VERSION "2021.24.4"

NS_ :

BS_:

BU_: VEH CH Receiver X

BO_ 832 VCFRONT_alertMatrix: 8 Vector__XXX
 SG_ VCFRONT_a060_engineeringBuild m0 : 63|1@1+ (1,0) [0|0] "" Vector__XXX
 SG_ VCFRONT_a120_DI_DRIVE_MIA m1 : 63|1@1+ (1,0) [0|0] "" Vector__XXX
 SG_ VCFRONT_a180_DCDCNotSupportingLV m2 : 63|1@1+ (1,0) [0|0] "" Vector__XXX
 SG_ VCFRONT_a240_lowSideCompromised m3 : 63|1@1+ (1,0) [0|0] "" Vector__XXX
 SG_ VCFRONT_a300_louverActuatorSwapD m4 : 63|1@1+ (1,0) [0|0] "" Vector__XXX
 SG_ VCFRONT_a360_ungracefulAccPlusEx m5 : 63|1@1+ (1,0) [0|0] "" Vector__XXX
 SG_ VCFRONT_a420_holidayParty m6 : 63|1@1+ (1,0) [0|0] "" Vector__XXX
 SG_ VCFRONT_a480_vnf1048Fault m7 : 63|1@1+ (1,0) [0|0] "" Vector__XXX
 SG_ VCFRONT_a540_radiatorSteamDetect m8 : 63|1@1+ (1,0) [0|0] "" Vector__XXX
 SG_ VCFRONT_a600_currentSensorMismat m9 : 63|1@1+ (1,0) [0|0] "" Vector__XXX
 SG_ VCFRONT_d660_coolantValveCircuit m10 : 63|1@1+ (1,0) [0|0] "" Vector__XXX
 SG_ VCFRONT_a059_inputResistanceHigh m0 : 62|1@1+ (1,0) [0|0] "" Vector__XXX
 SG_ VCFRONT_a119_SCCM_MIA m1 : 62|1@1+ (1,0) [0|0] "" Vector__XXX
 SG_ VCFRONT_a179_highLVAmpsIntoPCS m2 : 62|1@1+ (1,0) [0|0] "" Vector__XXX
 SG_ VCFRONT_a239_thmlFanChipComms m3 : 62|1@1+ (1,0) [0|0] "" Vector__XXX
 SG_ VCFRONT_a299_homelinkConfigurati m4 : 62|1@1+ (1,0) [0|0] "" Vector__XXX
 SG_ VCFRONT_a359_postPORExcessiveAh m5 : 62|1@1+ (1,0) [0|0] "" Vector__XXX
 SG_ VCFRONT_a419_TLVBMS_BrickSocLow m6 : 62|1@1+ (1,0) [0|0] "" Vector__XXX
 SG_ VCFRONT_a479_LVBMS_ECPA_NotClose m7 : 62|1@1+ (1,0) [0|0] "" Vector__XXX
 SG_ VCFRONT_a539_ccrExvCalibInitDebu m8 : 62|1@1+ (1,0) [0|0] "" Vector__XXX
 SG_ VCFRONT_a599_LVBatteryTypeUnsupp m9 : 62|1@1+ (1,0) [0|0] "" Vector__XXX
 SG_ VCFRONT_d659_radiatorFanCommLost m10 : 62|1@1+ (1,0) [0|0] "" Vector__XXX
 SG_ VCFRONT_a058_inputRHighSyncDebug m0 : 61|1@1+ (1,0) [0|0] "" Vector__XXX
 SG_ VCFRONT_a118_VCFRONT_MIA m1 : 61|1@1+ (1,0) [0|0] "" Vector__XXX
 SG_ VCFRONT_a178_compLiquidPumpOut m2 : 61|1@1+ (1,0) [0|0] "" Vector__XXX
 SG_ VCFRONT_a238_pumpPtChipComms m3 : 61|1@1+ (1,0) [0|0] "" Vector__XXX
 SG_ VCFRONT_a298_radiatorLowAirFlowD m4 : 61|1@1+ (1,0) [0|0] "" Vector__XXX
 SG_ VCFRONT_a358_hornOvercurrent m5 : 61|1@1+ (1,0) [0|0] "" Vector__XXX
 SG_ VCFRONT_a418_TLVBMS_BrickOverVol m6 : 61|1@1+ (1,0) [0|0] "" Vector__XXX
 SG_ VCFRONT_a478_LVBMS_MOSFET_Open m7 : 61|1@1+ (1,0) [0|0] "" Vector__XXX
 SG_ VCFRONT_a538_cclExvCalibInitDebu m8 : 61|1@1+ (1,0) [0|0] "" Vector__XXX
 SG_ VCFRONT_a598_eFuseSelfTestFailur m9 : 61|1@1+ (1,0) [0|0] "" Vector__XXX
 SG_ VCFRONT_d658_radiatorFanCircuitI m10 : 61|1@1+ (1,0) [0|0] "" Vector__XXX
 SG_ VCFRONT_a057_HVP_MIA m0 : 60|1@1+ (1,0) [0|0] "" Vector__XXX
 SG_ VCFRONT_a117_VCLEFT_MIA m1 : 60|1@1+ (1,0) [0|0] "" Vector__XXX
 SG_ VCFRONT_a177_mcuAudioEFuseFault m2 : 60|1@1+ (1,0) [0|0] "" Vector__XXX
 SG_ VCFRONT_a237_pumpBatChipComms m3 : 60|1@1+ (1,0) [0|0] "" Vector__XXX
 SG_ VCFRONT_a297_TLVBMS_BmbHwOverTem m4 : 60|1@1+ (1,0) [0|0] "" Vector__XXX
 SG_ VCFRONT_a357_hornUndercurrent m5 : 60|1@1+ (1,0) [0|0] "" Vector__XXX
 SG_ VCFRONT_a417_TLVBMS_BrickOverVol m6 : 60|1@1+ (1,0) [0|0] "" Vector__XXX
 SG_ VCFRONT_a477_LVBatteryUnrecovera m7 : 60|1@1+ (1,0) [0|0] "" Vector__XXX
 SG_ VCFRONT_a537_lccExvCalibInitDebu m8 : 60|1@1+ (1,0) [0|0] "" Vector__XXX
 SG_ VCFRONT_a597_vcrightFastBlowPowe m9 : 60|1@1+ (1,0) [0|0] "" Vector__XXX
 SG_ VCFRONT_d657_radiatorFanOperatio m10 : 60|1@1+ (1,0) [0|0] "" Vector__XXX
 SG_ VCFRONT_a116_VCRIGHT_MIA m1 : 59|1@1+ (1,0) [0|0] "" Vector__XXX
 SG_ VCFRONT_a176_vehicleInSelfTest m2 : 59|1@1+ (1,0) [0|0] "" Vector__XXX
 SG_ VCFRONT_a236_batTempSnsIrrationa m3 : 59|1@1+ (1,0) [0|0] "" Vector__XXX
 SG_ VCFRONT_a296_turnSignalIssue m4 : 59|1@1+ (1,0) [0|0] "" Vector__XXX
 SG_ VCFRONT_a356_refrigSysLockout m5 : 59|1@1+ (1,0) [0|0] "" Vector__XXX
 SG_ VCFRONT_a416_TLVBMS_BrickOverDis m6 : 59|1@1+ (1,0) [0|0] "" Vector__XXX
 SG_ VCFRONT_a476_LVBMSMIA m7 : 59|1@1+ (1,0) [0|0] "" Vector__XXX
 SG_ VCFRONT_a536_recircExvCalibInitD m8 : 59|1@1+ (1,0) [0|0] "" Vector__XXX
 SG_ VCFRONT_a596_vcrightCurvePowerCu m9 : 59|1@1+ (1,0) [0|0] "" Vector__XXX
 SG_ VCFRONT_d656_batteryCoolantPumpC m10 : 59|1@1+ (1,0) [0|0] "" Vector__XXX
 SG_ VCFRONT_a115_VCSEC_MIA m1 : 58|1@1+ (1,0) [0|0] "" Vector__XXX
 SG_ VCFRONT_a175_ambientTempSns m2 : 58|1@1+ (1,0) [0|0] "" Vector__XXX
 SG_ VCFRONT_a235_ptTempSnsIrrational m3 : 58|1@1+ (1,0) [0|0] "" Vector__XXX
 SG_ VCFRONT_a295_rightSideRepeaterLi m4 : 58|1@1+ (1,0) [0|0] "" Vector__XXX
 SG_ VCFRONT_a355_coolantSysLockout m5 : 58|1@1+ (1,0) [0|0] "" Vector__XXX
 SG_ VCFRONT_a415_prechargeLVLoadRedu m6 : 58|1@1+ (1,0) [0|0] "" Vector__XXX
 SG_ VCFRONT_a475_rightHeadlampIntern m7 : 58|1@1+ (1,0) [0|0] "" Vector__XXX
 SG_ VCFRONT_a535_evapExvCalibInitDeb m8 : 58|1@1+ (1,0) [0|0] "" Vector__XXX
 SG_ VCFRONT_a595_voltageSensorMismat m9 : 58|1@1+ (1,0) [0|0] "" Vector__XXX
 SG_ VCFRONT_d655_batteryCoolantPumpC m10 : 58|1@1+ (1,0) [0|0] "" Vector__XXX
 SG_ VCFRONT_a054_compressorLowFlowUs m0 : 57|1@1+ (1,0) [0|0] "" Vector__XXX
 SG_ VCFRONT_a114_ESP_MIA m1 : 57|1@1+ (1,0) [0|0] "" Vector__XXX
 SG_ VCFRONT_a174_driveNotAuthed m2 : 57|1@1+ (1,0) [0|0] "" Vector__XXX
 SG_ VCFRONT_a234_autopilot2EFuseFaul m3 : 57|1@1+ (1,0) [0|0] "" Vector__XXX
 SG_ VCFRONT_a294_leftSideRepeaterLig m4 : 57|1@1+ (1,0) [0|0] "" Vector__XXX
 SG_ VCFRONT_a354_windshieldCameraHea m5 : 57|1@1+ (1,0) [0|0] "" Vector__XXX
 SG_ VCFRONT_a414_prechargeLVLoadRedu m6 : 57|1@1+ (1,0) [0|0] "" Vector__XXX
 SG_ VCFRONT_a474_leftHeadlampInterna m7 : 57|1@1+ (1,0) [0|0] "" Vector__XXX
 SG_ VCFRONT_a534_chillerExvCalibInit m8 : 57|1@1+ (1,0) [0|0] "" Vector__XXX
 SG_ VCFRONT_a594_virtualPitchConvers m9 : 57|1@1+ (1,0) [0|0] "" Vector__XXX
 SG_ VCFRONT_d654_batteryCoolantPumpS m10 : 57|1@1+ (1,0) [0|0] "" Vector__XXX
 SG_ VCFRONT_a053_wiperCommErrorUser m0 : 56|1@1+ (1,0) [0|0] "" Vector__XXX
 SG_ VCFRONT_a113_UI_MIA m1 : 56|1@1+ (1,0) [0|0] "" Vector__XXX
 SG_ VCFRONT_a173_HVBlckdByMsmtch m2 : 56|1@1+ (1,0) [0|0] "" Vector__XXX
 SG_ VCFRONT_a233_autopilot1EFuseFaul m3 : 56|1@1+ (1,0) [0|0] "" Vector__XXX
 SG_ VCFRONT_a293_interiorFrunkLightF m4 : 56|1@1+ (1,0) [0|0] "" Vector__XXX
 SG_ VCFRONT_a353_wiperHeaterUndercur m5 : 56|1@1+ (1,0) [0|0] "" Vector__XXX
 SG_ VCFRONT_a413_TLVBMS_BmbVrefWarni m6 : 56|1@1+ (1,0) [0|0] "" Vector__XXX
 SG_ VCFRONT_a473_rightHeadlampRangeU m7 : 56|1@1+ (1,0) [0|0] "" Vector__XXX
 SG_ VCFRONT_a533_TLVBMS_MosfetOverTe m8 : 56|1@1+ (1,0) [0|0] "" Vector__XXX
 SG_ VCFRONT_a593_vcleftFastBlowPower m9 : 56|1@1+ (1,0) [0|0] "" Vector__XXX
 SG_ VCFRONT_d653_ptCoolantPumpCommLo m10 : 56|1@1+ (1,0) [0|0] "" Vector__XXX
 SG_ VCFRONT_a112_EPBL_MIA m1 : 55|1@1+ (1,0) [0|0] "" Vector__XXX
 SG_ VCFRONT_a172_wsteHtBlckdByMsmtch m2 : 55|1@1+ (1,0) [0|0] "" Vector__XXX
 SG_ VCFRONT_a232_lowSideControllerHi m3 : 55|1@1+ (1,0) [0|0] "" Vector__XXX
 SG_ VCFRONT_a292_sideMarkerLightPipe m4 : 55|1@1+ (1,0) [0|0] "" Vector__XXX
 SG_ VCFRONT_a352_audioCurrentSpikeDa m5 : 55|1@1+ (1,0) [0|0] "" Vector__XXX
 SG_ VCFRONT_a412_dcrData3 m6 : 55|1@1+ (1,0) [0|0] "" Vector__XXX
 SG_ VCFRONT_a472_leftHeadlampRangeUp m7 : 55|1@1+ (1,0) [0|0] "" Vector__XXX
 SG_ VCFRONT_a532_gtwMIAInDrive m8 : 55|1@1+ (1,0) [0|0] "" Vector__XXX
 SG_ VCFRONT_a592_vcleftCurvePowerCut m9 : 55|1@1+ (1,0) [0|0] "" Vector__XXX
 SG_ VCFRONT_d652_ptCoolantPumpCircui m10 : 55|1@1+ (1,0) [0|0] "" Vector__XXX
 SG_ VCFRONT_a111_EPBR_MIA m1 : 54|1@1+ (1,0) [0|0] "" Vector__XXX
 SG_ VCFRONT_a171_driveBlckdByMsmtch m2 : 54|1@1+ (1,0) [0|0] "" Vector__XXX
 SG_ VCFRONT_a231_12VTempSensShort m3 : 54|1@1+ (1,0) [0|0] "" Vector__XXX
 SG_ VCFRONT_a291_rightFogLightFault m4 : 54|1@1+ (1,0) [0|0] "" Vector__XXX
 SG_ VCFRONT_a351_emergencyFrunkButto m5 : 54|1@1+ (1,0) [0|0] "" Vector__XXX
 SG_ VCFRONT_a411_LVBatteryDataCollec m6 : 54|1@1+ (1,0) [0|0] "" Vector__XXX
 SG_ VCFRONT_a531_lowPowerIndexFlagge m8 : 54|1@1+ (1,0) [0|0] "" Vector__XXX
 SG_ VCFRONT_a591_vcrightFastBlowDete m9 : 54|1@1+ (1,0) [0|0] "" Vector__XXX
 SG_ VCFRONT_d651_ptCoolantPumpStall m10 : 54|1@1+ (1,0) [0|0] "" Vector__XXX
 SG_ VCFRONT_a110_GTW_MIA m1 : 53|1@1+ (1,0) [0|0] "" Vector__XXX
 SG_ VCFRONT_a170_hcmUnderVoltage m2 : 53|1@1+ (1,0) [0|0] "" Vector__XXX
 SG_ VCFRONT_a230_thmlFanFbkSanity m3 : 53|1@1+ (1,0) [0|0] "" Vector__XXX
 SG_ VCFRONT_a290_leftFogLightFault m4 : 53|1@1+ (1,0) [0|0] "" Vector__XXX
 SG_ VCFRONT_a350_espValveCurrentSens m5 : 53|1@1+ (1,0) [0|0] "" Vector__XXX
 SG_ VCFRONT_a410_LVBatteryDataCollec m6 : 53|1@1+ (1,0) [0|0] "" Vector__XXX
 SG_ VCFRONT_a470_implausiblePdPlDete m7 : 53|1@1+ (1,0) [0|0] "" Vector__XXX
 SG_ VCFRONT_a530_sharpCurrentRise m8 : 53|1@1+ (1,0) [0|0] "" Vector__XXX
 SG_ VCFRONT_a590_vcrightPwrRationali m9 : 53|1@1+ (1,0) [0|0] "" Vector__XXX
 SG_ VCFRONT_d650_lowCoolantLevel m10 : 53|1@1+ (1,0) [0|0] "" Vector__XXX
 SG_ VCFRONT_a109_RCM_MIA m1 : 52|1@1+ (1,0) [0|0] "" Vector__XXX
 SG_ VCFRONT_a169_hcmPhaseEnableFail m2 : 52|1@1+ (1,0) [0|0] "" Vector__XXX
 SG_ VCFRONT_a229_pumpPtFbkSanity m3 : 52|1@1+ (1,0) [0|0] "" Vector__XXX
 SG_ VCFRONT_a289_ccRightExvFault m4 : 52|1@1+ (1,0) [0|0] "" Vector__XXX
 SG_ VCFRONT_a349_vbatFusedFastTripSl m5 : 52|1@1+ (1,0) [0|0] "" Vector__XXX
 SG_ VCFRONT_a409_invalidConfiguratio m6 : 52|1@1+ (1,0) [0|0] "" Vector__XXX
 SG_ VCFRONT_a469_prvPopDetected m7 : 52|1@1+ (1,0) [0|0] "" Vector__XXX
 SG_ VCFRONT_a529_discnctdBatteryStat m8 : 52|1@1+ (1,0) [0|0] "" Vector__XXX
 SG_ VCFRONT_a589_vcleftFastBlowDetec m9 : 52|1@1+ (1,0) [0|0] "" Vector__XXX
 SG_ VCFRONT_a649_persistAccPortPower m10 : 52|1@1+ (1,0) [0|0] "" Vector__XXX
 SG_ VCFRONT_a108_DIF_MIA m1 : 51|1@1+ (1,0) [0|0] "" Vector__XXX
 SG_ VCFRONT_a168_hcmShortToVBAT m2 : 51|1@1+ (1,0) [0|0] "" Vector__XXX
 SG_ VCFRONT_a228_pumpBatFbkSanity m3 : 51|1@1+ (1,0) [0|0] "" Vector__XXX
 SG_ VCFRONT_a288_ccLeftExvFault m4 : 51|1@1+ (1,0) [0|0] "" Vector__XXX
 SG_ VCFRONT_a348_espFastTripSlope m5 : 51|1@1+ (1,0) [0|0] "" Vector__XXX
 SG_ VCFRONT_a408_standbyChargeProfil m6 : 51|1@1+ (1,0) [0|0] "" Vector__XXX
 SG_ VCFRONT_a468_highPowerIndexFlagg m7 : 51|1@1+ (1,0) [0|0] "" Vector__XXX
 SG_ VCFRONT_a528_LVBatteryCommsDiscn m8 : 51|1@1+ (1,0) [0|0] "" Vector__XXX
 SG_ VCFRONT_a588_vcleftPwrRationalit m9 : 51|1@1+ (1,0) [0|0] "" Vector__XXX
 SG_ VCFRONT_d648_louverBlocked m10 : 51|1@1+ (1,0) [0|0] "" Vector__XXX
 SG_ VCFRONT_a047_resetReason m0 : 50|1@1+ (1,0) [0|0] "" Vector__XXX
 SG_ VCFRONT_a107_BMS_MIA m1 : 50|1@1+ (1,0) [0|0] "" Vector__XXX
 SG_ VCFRONT_a167_leftHCMMIA m2 : 50|1@1+ (1,0) [0|0] "" Vector__XXX
 SG_ VCFRONT_a287_lccExvFault m4 : 50|1@1+ (1,0) [0|0] "" Vector__XXX
 SG_ VCFRONT_a347_iboosterFastTripSlo m5 : 50|1@1+ (1,0) [0|0] "" Vector__XXX
 SG_ VCFRONT_a407_dcrMilliOhmsAboveTh m6 : 50|1@1+ (1,0) [0|0] "" Vector__XXX
 SG_ VCFRONT_a467_lowPowerIndexFlagge m7 : 50|1@1+ (1,0) [0|0] "" Vector__XXX
 SG_ VCFRONT_a527_LVBatteryCellImbala m8 : 50|1@1+ (1,0) [0|0] "" Vector__XXX
 SG_ VCFRONT_a587_externalLVPowerSupp m9 : 50|1@1+ (1,0) [0|0] "" Vector__XXX
 SG_ VCFRONT_d647_louverCommLost m10 : 50|1@1+ (1,0) [0|0] "" Vector__XXX
 SG_ VCFRONT_a046_Task1000msError m0 : 49|1@1+ (1,0) [0|0] "" Vector__XXX
 SG_ VCFRONT_a106_PCS_MIA m1 : 49|1@1+ (1,0) [0|0] "" Vector__XXX
 SG_ VCFRONT_a166_rightHCMMIA m2 : 49|1@1+ (1,0) [0|0] "" Vector__XXX
 SG_ VCFRONT_a286_recircExvFault m4 : 49|1@1+ (1,0) [0|0] "" Vector__XXX
 SG_ VCFRONT_a346_epas3sFastTripSlope m5 : 49|1@1+ (1,0) [0|0] "" Vector__XXX
 SG_ VCFRONT_a406_dcrData2 m6 : 49|1@1+ (1,0) [0|0] "" Vector__XXX
 SG_ VCFRONT_a466_highFlowIndexLowSub m7 : 49|1@1+ (1,0) [0|0] "" Vector__XXX
 SG_ VCFRONT_a586_rightLowOrHighBeamL m9 : 49|1@1+ (1,0) [0|0] "" Vector__XXX
 SG_ VCFRONT_a646_washPumpHealthCalcu m10 : 49|1@1+ (1,0) [0|0] "" Vector__XXX
 SG_ VCFRONT_a045_Task100msError m0 : 48|1@1+ (1,0) [0|0] "" Vector__XXX
 SG_ VCFRONT_a105_TAS_MIA m1 : 48|1@1+ (1,0) [0|0] "" Vector__XXX
 SG_ VCFRONT_a165_unxpctdEFuseLckout m2 : 48|1@1+ (1,0) [0|0] "" Vector__XXX
 SG_ VCFRONT_a225_driveBlckdByShowroo m3 : 48|1@1+ (1,0) [0|0] "" Vector__XXX
 SG_ VCFRONT_a285_evaporatorExvFault m4 : 48|1@1+ (1,0) [0|0] "" Vector__XXX
 SG_ VCFRONT_a345_epas3pFastTripSlope m5 : 48|1@1+ (1,0) [0|0] "" Vector__XXX
 SG_ VCFRONT_a405_dcrData1 m6 : 48|1@1+ (1,0) [0|0] "" Vector__XXX
 SG_ VCFRONT_a465_lowFlowIndexHighSub m7 : 48|1@1+ (1,0) [0|0] "" Vector__XXX
 SG_ VCFRONT_a525_LVBatterySWMisconfi m8 : 48|1@1+ (1,0) [0|0] "" Vector__XXX
 SG_ VCFRONT_a585_bothHeadlampsIntern m9 : 48|1@1+ (1,0) [0|0] "" Vector__XXX
 SG_ VCFRONT_a645_washPumpHealthCalcu m10 : 48|1@1+ (1,0) [0|0] "" Vector__XXX
 SG_ VCFRONT_a044_Task10msError m0 : 47|1@1+ (1,0) [0|0] "" Vector__XXX
 SG_ VCFRONT_a104_DAS_MIA m1 : 47|1@1+ (1,0) [0|0] "" Vector__XXX
 SG_ VCFRONT_a164_eFuseLckoutMissing m2 : 47|1@1+ (1,0) [0|0] "" Vector__XXX
 SG_ VCFRONT_a224_revBatChrgPmpFault m3 : 47|1@1+ (1,0) [0|0] "" Vector__XXX
 SG_ VCFRONT_a284_chillerExvFault m4 : 47|1@1+ (1,0) [0|0] "" Vector__XXX
 SG_ VCFRONT_a344_pcsFastTripSlope m5 : 47|1@1+ (1,0) [0|0] "" Vector__XXX
 SG_ VCFRONT_a404_resistanceEstimatio m6 : 47|1@1+ (1,0) [0|0] "" Vector__XXX
 SG_ VCFRONT_a464_highFlowIndexHighSu m7 : 47|1@1+ (1,0) [0|0] "" Vector__XXX
 SG_ VCFRONT_a524_rightHeadlampAiming m8 : 47|1@1+ (1,0) [0|0] "" Vector__XXX
 SG_ VCFRONT_a584_frunkSwitchGroupDeb m9 : 47|1@1+ (1,0) [0|0] "" Vector__XXX
 SG_ VCFRONT_a644_washPumpHealthCalcu m10 : 47|1@1+ (1,0) [0|0] "" Vector__XXX
 SG_ VCFRONT_a043_Task1msError m0 : 46|1@1+ (1,0) [0|0] "" Vector__XXX
 SG_ VCFRONT_a103_CP_MIA m1 : 46|1@1+ (1,0) [0|0] "" Vector__XXX
 SG_ VCFRONT_a163_compressorDisabledF m2 : 46|1@1+ (1,0) [0|0] "" Vector__XXX
 SG_ VCFRONT_a223_12VTempSensDiscnect m3 : 46|1@1+ (1,0) [0|0] "" Vector__XXX
 SG_ VCFRONT_a283_thmlFanLimitedByCur m4 : 46|1@1+ (1,0) [0|0] "" Vector__XXX
 SG_ VCFRONT_a343_vcrightFastTripSlop m5 : 46|1@1+ (1,0) [0|0] "" Vector__XXX
 SG_ VCFRONT_a403_chargeExitHardCurre m6 : 46|1@1+ (1,0) [0|0] "" Vector__XXX
 SG_ VCFRONT_a463_frunkSensorService m7 : 46|1@1+ (1,0) [0|0] "" Vector__XXX
 SG_ VCFRONT_a523_eFuseThresholdsInco m8 : 46|1@1+ (1,0) [0|0] "" Vector__XXX
 SG_ VCFRONT_a583_frunkSwitchGroupDis m9 : 46|1@1+ (1,0) [0|0] "" Vector__XXX
 SG_ VCFRONT_a643_rightHeadlampUartCo m10 : 46|1@1+ (1,0) [0|0] "" Vector__XXX
 SG_ VCFRONT_a042_HighStackUsage m0 : 45|1@1+ (1,0) [0|0] "" Vector__XXX
 SG_ VCFRONT_a102_PTC_MIA m1 : 45|1@1+ (1,0) [0|0] "" Vector__XXX
 SG_ VCFRONT_a162_compressorInhibited m2 : 45|1@1+ (1,0) [0|0] "" Vector__XXX
 SG_ VCFRONT_a222_rightTurnLightFault m3 : 45|1@1+ (1,0) [0|0] "" Vector__XXX
 SG_ VCFRONT_a282_coolantLevelSensorF m4 : 45|1@1+ (1,0) [0|0] "" Vector__XXX
 SG_ VCFRONT_a342_vcleftFastTripSlope m5 : 45|1@1+ (1,0) [0|0] "" Vector__XXX
 SG_ VCFRONT_a402_LVBatteryCannotSupp m6 : 45|1@1+ (1,0) [0|0] "" Vector__XXX
 SG_ VCFRONT_a462_LVBMSFault m7 : 45|1@1+ (1,0) [0|0] "" Vector__XXX
 SG_ VCFRONT_a522_hibernationActiveLo m8 : 45|1@1+ (1,0) [0|0] "" Vector__XXX
 SG_ VCFRONT_a582_goodForPCSPowerCycl m9 : 45|1@1+ (1,0) [0|0] "" Vector__XXX
 SG_ VCFRONT_d642_batteryCoolantPumpC m10 : 45|1@1+ (1,0) [0|0] "" Vector__XXX
 SG_ VCFRONT_a041_HighCPULoad m0 : 44|1@1+ (1,0) [0|0] "" Vector__XXX
 SG_ VCFRONT_a101_PM_MIA m1 : 44|1@1+ (1,0) [0|0] "" Vector__XXX
 SG_ VCFRONT_a161_compressorSelfFault m2 : 44|1@1+ (1,0) [0|0] "" Vector__XXX
 SG_ VCFRONT_a221_leftTurnLightFault m3 : 44|1@1+ (1,0) [0|0] "" Vector__XXX
 SG_ VCFRONT_a281_alcoholInterlockBlo m4 : 44|1@1+ (1,0) [0|0] "" Vector__XXX
 SG_ VCFRONT_a341_vbatFusedFastTripOC m5 : 44|1@1+ (1,0) [0|0] "" Vector__XXX
 SG_ VCFRONT_a401_deadLVMinimalAhDisc m6 : 44|1@1+ (1,0) [0|0] "" Vector__XXX
 SG_ VCFRONT_a461_TLVBMS_SocHighAhErr m7 : 44|1@1+ (1,0) [0|0] "" Vector__XXX
 SG_ VCFRONT_a521_vcleftEFuseLoadShed m8 : 44|1@1+ (1,0) [0|0] "" Vector__XXX
 SG_ VCFRONT_a581_windshieldWiperEFus m9 : 44|1@1+ (1,0) [0|0] "" Vector__XXX
 SG_ VCFRONT_d641_ptCoolantPumpCircui m10 : 44|1@1+ (1,0) [0|0] "" Vector__XXX
 SG_ VCFRONT_a040_Backtrace m0 : 43|1@1+ (1,0) [0|0] "" Vector__XXX
 SG_ VCFRONT_a100_CANbus_MIA m1 : 43|1@1+ (1,0) [0|0] "" Vector__XXX
 SG_ VCFRONT_a160_compressorInhibited m2 : 43|1@1+ (1,0) [0|0] "" Vector__XXX
 SG_ VCFRONT_a220_reverseBatteryFault m3 : 43|1@1+ (1,0) [0|0] "" Vector__XXX
 SG_ VCFRONT_a280_refrigLiquidPresSns m4 : 43|1@1+ (1,0) [0|0] "" Vector__XXX
 SG_ VCFRONT_a340_espFastTripOCMax m5 : 43|1@1+ (1,0) [0|0] "" Vector__XXX
 SG_ VCFRONT_a400_TLVBMS_BmbVrefBad m6 : 43|1@1+ (1,0) [0|0] "" Vector__XXX
 SG_ VCFRONT_a460_hardIsentropicTdFai m7 : 43|1@1+ (1,0) [0|0] "" Vector__XXX
 SG_ VCFRONT_a580_rightHeadlightEFuse m9 : 43|1@1+ (1,0) [0|0] "" Vector__XXX
 SG_ VCFRONT_d640_firmwareVersionMism m10 : 43|1@1+ (1,0) [0|0] "" Vector__XXX
 SG_ VCFRONT_a039_ProtFaultAddress m0 : 42|1@1+ (1,0) [0|0] "" Vector__XXX
 SG_ VCFRONT_a099_PARK_MIA m1 : 42|1@1+ (1,0) [0|0] "" Vector__XXX
 SG_ VCFRONT_a159_coolantValveFault m2 : 42|1@1+ (1,0) [0|0] "" Vector__XXX
 SG_ VCFRONT_a219_LVVoltFloorRchd m3 : 42|1@1+ (1,0) [0|0] "" Vector__XXX
 SG_ VCFRONT_a279_refrigLiquidTempSns m4 : 42|1@1+ (1,0) [0|0] "" Vector__XXX
 SG_ VCFRONT_a339_iboosterFastTripOCM m5 : 42|1@1+ (1,0) [0|0] "" Vector__XXX
 SG_ VCFRONT_a399_frunkNeverReportedO m6 : 42|1@1+ (1,0) [0|0] "" Vector__XXX
 SG_ VCFRONT_a459_thermalFillAndDrive m7 : 42|1@1+ (1,0) [0|0] "" Vector__XXX
 SG_ VCFRONT_a579_leftHeadlightEFuseT m9 : 42|1@1+ (1,0) [0|0] "" Vector__XXX
 SG_ VCFRONT_d639_batteryCoolantTempS m10 : 42|1@1+ (1,0) [0|0] "" Vector__XXX
 SG_ VCFRONT_a038_ProtFaultInfo m0 : 41|1@1+ (1,0) [0|0] "" Vector__XXX
 SG_ VCFRONT_a098_DIR_MIA m1 : 41|1@1+ (1,0) [0|0] "" Vector__XXX
 SG_ VCFRONT_a158_louverDisconnected m2 : 41|1@1+ (1,0) [0|0] "" Vector__XXX
 SG_ VCFRONT_a218_socMonitorDetectedT m3 : 41|1@1+ (1,0) [0|0] "" Vector__XXX
 SG_ VCFRONT_a278_TLVBMS_BmbHwOverCur m4 : 41|1@1+ (1,0) [0|0] "" Vector__XXX
 SG_ VCFRONT_a338_epas3sFastTripOCMax m5 : 41|1@1+ (1,0) [0|0] "" Vector__XXX
 SG_ VCFRONT_a398_tempSensorCheckInco m6 : 41|1@1+ (1,0) [0|0] "" Vector__XXX
 SG_ VCFRONT_a458_grosslyLowRefrigera m7 : 41|1@1+ (1,0) [0|0] "" Vector__XXX
 SG_ VCFRONT_a518_LVBMSFault_MOS_Open m8 : 41|1@1+ (1,0) [0|0] "" Vector__XXX
 SG_ VCFRONT_a578_vbatFusedLowCurrent m9 : 41|1@1+ (1,0) [0|0] "" Vector__XXX
 SG_ VCFRONT_a698_rightHeadlampNotAim m11 : 41|1@1+ (1,0) [0|0] "" Vector__XXX
 SG_ VCFRONT_d638_ptCoolantTempSensor m10 : 41|1@1+ (1,0) [0|0] "" Vector__XXX
 SG_ VCFRONT_a097_CMP_MIA m1 : 40|1@1+ (1,0) [0|0] "" Vector__XXX
 SG_ VCFRONT_a157_louverBreakage m2 : 40|1@1+ (1,0) [0|0] "" Vector__XXX
 SG_ VCFRONT_a277_TLVBMS_BmbStatusReg m4 : 40|1@1+ (1,0) [0|0] "" Vector__XXX
 SG_ VCFRONT_a337_epas3pFastTripOCMax m5 : 40|1@1+ (1,0) [0|0] "" Vector__XXX
 SG_ VCFRONT_a397_temperatureSensorCh m6 : 40|1@1+ (1,0) [0|0] "" Vector__XXX
 SG_ VCFRONT_a457_liquidTempSensInter m7 : 40|1@1+ (1,0) [0|0] "" Vector__XXX
 SG_ VCFRONT_a517_hibernationRecovery m8 : 40|1@1+ (1,0) [0|0] "" Vector__XXX
 SG_ VCFRONT_a577_tasEFuseTrip m9 : 40|1@1+ (1,0) [0|0] "" Vector__XXX
 SG_ VCFRONT_a697_leftHeadlampNotAime m11 : 40|1@1+ (1,0) [0|0] "" Vector__XXX
 SG_ VCFRONT_d637_battCoolantPumpDete m10 : 40|1@1+ (1,0) [0|0] "" Vector__XXX
 SG_ VCFRONT_a096_OCS1P_MIA m1 : 39|1@1+ (1,0) [0|0] "" Vector__XXX
 SG_ VCFRONT_a156_louverBlockage m2 : 39|1@1+ (1,0) [0|0] "" Vector__XXX
 SG_ VCFRONT_a216_powerCutoffImminent m3 : 39|1@1+ (1,0) [0|0] "" Vector__XXX
 SG_ VCFRONT_a276_TLVBMS_BmbDataInteg m4 : 39|1@1+ (1,0) [0|0] "" Vector__XXX
 SG_ VCFRONT_a336_pcsFastTripOCMax m5 : 39|1@1+ (1,0) [0|0] "" Vector__XXX
 SG_ VCFRONT_a396_coolantLevelLowUser m6 : 39|1@1+ (1,0) [0|0] "" Vector__XXX
 SG_ VCFRONT_a456_liquidPresSensInter m7 : 39|1@1+ (1,0) [0|0] "" Vector__XXX
 SG_ VCFRONT_a516_hibernationActive m8 : 39|1@1+ (1,0) [0|0] "" Vector__XXX
 SG_ VCFRONT_a576_mcuLogicEFuseTrip m9 : 39|1@1+ (1,0) [0|0] "" Vector__XXX
 SG_ VCFRONT_d636_ptCoolantPumpDetect m10 : 39|1@1+ (1,0) [0|0] "" Vector__XXX
 SG_ VCFRONT_a095_CHG_MIA m1 : 38|1@1+ (1,0) [0|0] "" Vector__XXX
 SG_ VCFRONT_a155_prechargeDCRData2 m2 : 38|1@1+ (1,0) [0|0] "" Vector__XXX
 SG_ VCFRONT_a275_TLVBMS_BmbCommunica m4 : 38|1@1+ (1,0) [0|0] "" Vector__XXX
 SG_ VCFRONT_a335_vcrightFastTripOCMa m5 : 38|1@1+ (1,0) [0|0] "" Vector__XXX
 SG_ VCFRONT_a395_pressureSensorCheck m6 : 38|1@1+ (1,0) [0|0] "" Vector__XXX
 SG_ VCFRONT_a455_suctionTempSensInte m7 : 38|1@1+ (1,0) [0|0] "" Vector__XXX
 SG_ VCFRONT_a515_LVBMSFault_MOS_Open m8 : 38|1@1+ (1,0) [0|0] "" Vector__XXX
 SG_ VCFRONT_a575_frontOilPumpEFuseTr m9 : 38|1@1+ (1,0) [0|0] "" Vector__XXX
 SG_ VCFRONT_a635_rtosSleepFailed m10 : 38|1@1+ (1,0) [0|0] "" Vector__XXX
 SG_ VCFRONT_a094_EPAS3P_MIA m1 : 37|1@1+ (1,0) [0|0] "" Vector__XXX
 SG_ VCFRONT_a154_prechargeDCRData1 m2 : 37|1@1+ (1,0) [0|0] "" Vector__XXX
 SG_ VCFRONT_a274_failureToPrechargeR m4 : 37|1@1+ (1,0) [0|0] "" Vector__XXX
 SG_ VCFRONT_a334_vcleftFastTripOCMax m5 : 37|1@1+ (1,0) [0|0] "" Vector__XXX
 SG_ VCFRONT_a394_pressureSensorCheck m6 : 37|1@1+ (1,0) [0|0] "" Vector__XXX
 SG_ VCFRONT_a454_suctionPresSensInte m7 : 37|1@1+ (1,0) [0|0] "" Vector__XXX
 SG_ VCFRONT_a514_LVBMSFault_MOS_Open m8 : 37|1@1+ (1,0) [0|0] "" Vector__XXX
 SG_ VCFRONT_a574_frontDriveInverterE m9 : 37|1@1+ (1,0) [0|0] "" Vector__XXX
 SG_ VCFRONT_a634_indeterminateSwitch m10 : 37|1@1+ (1,0) [0|0] "" Vector__XXX
 SG_ VCFRONT_a033_eccNonCorrectableEr m0 : 36|1@1+ (1,0) [0|0] "" Vector__XXX
 SG_ VCFRONT_a093_VCSEATP_MIA m1 : 36|1@1+ (1,0) [0|0] "" Vector__XXX
 SG_ VCFRONT_a153_userPresenceDisplay m2 : 36|1@1+ (1,0) [0|0] "" Vector__XXX
 SG_ VCFRONT_a213_LVOvercharge m3 : 36|1@1+ (1,0) [0|0] "" Vector__XXX
 SG_ VCFRONT_a273_wiperFrictionModelF m4 : 36|1@1+ (1,0) [0|0] "" Vector__XXX
 SG_ VCFRONT_a333_vbatFusedSlowTripOC m5 : 36|1@1+ (1,0) [0|0] "" Vector__XXX
 SG_ VCFRONT_a393_ambientTempNetworkS m6 : 36|1@1+ (1,0) [0|0] "" Vector__XXX
 SG_ VCFRONT_a453_dischargeTempSensIn m7 : 36|1@1+ (1,0) [0|0] "" Vector__XXX
 SG_ VCFRONT_a513_LVBMSFault_MOS_Open m8 : 36|1@1+ (1,0) [0|0] "" Vector__XXX
 SG_ VCFRONT_a573_radarEFuseTrip m9 : 36|1@1+ (1,0) [0|0] "" Vector__XXX
 SG_ VCFRONT_a032_ipcWatchdogExpired m0 : 35|1@1+ (1,0) [0|0] "" Vector__XXX
 SG_ VCFRONT_a092_VCSEATD_MIA m1 : 35|1@1+ (1,0) [0|0] "" Vector__XXX
 SG_ VCFRONT_a152_thmlFanLowRPMCBang m2 : 35|1@1+ (1,0) [0|0] "" Vector__XXX
 SG_ VCFRONT_a212_IBSOverTemp m3 : 35|1@1+ (1,0) [0|0] "" Vector__XXX
 SG_ VCFRONT_a332_espSlowTripOC m5 : 35|1@1+ (1,0) [0|0] "" Vector__XXX
 SG_ VCFRONT_a392_TLVBMS_BmbHwUnderVo m6 : 35|1@1+ (1,0) [0|0] "" Vector__XXX
 SG_ VCFRONT_a452_dischargePresSensIn m7 : 35|1@1+ (1,0) [0|0] "" Vector__XXX
 SG_ VCFRONT_a512_LVBMSFault_MOS_Open m8 : 35|1@1+ (1,0) [0|0] "" Vector__XXX
 SG_ VCFRONT_a572_hvacCompressorEFuse m9 : 35|1@1+ (1,0) [0|0] "" Vector__XXX
 SG_ VCFRONT_a031_UDSActive m0 : 34|1@1+ (1,0) [0|0] "" Vector__XXX
 SG_ VCFRONT_a091_CMPD_MIA m1 : 34|1@1+ (1,0) [0|0] "" Vector__XXX
 SG_ VCFRONT_a151_pumpPtLowRPMCBang m2 : 34|1@1+ (1,0) [0|0] "" Vector__XXX
 SG_ VCFRONT_a211_I2CFault m3 : 34|1@1+ (1,0) [0|0] "" Vector__XXX
 SG_ VCFRONT_a271_LVBatteryPermSuppor m4 : 34|1@1+ (1,0) [0|0] "" Vector__XXX
 SG_ VCFRONT_a331_iboosterSlowTripOC m5 : 34|1@1+ (1,0) [0|0] "" Vector__XXX
 SG_ VCFRONT_a391_frunkLatchSwitchFau m6 : 34|1@1+ (1,0) [0|0] "" Vector__XXX
 SG_ VCFRONT_a451_refrigerantNotCommi m7 : 34|1@1+ (1,0) [0|0] "" Vector__XXX
 SG_ VCFRONT_a511_DCDCSaturationLoadS m8 : 34|1@1+ (1,0) [0|0] "" Vector__XXX
 SG_ VCFRONT_a571_headlampsAdaptedToR m9 : 34|1@1+ (1,0) [0|0] "" Vector__XXX
 SG_ VCFRONT_a631_rightHeadlampFactor m10 : 34|1@1+ (1,0) [0|0] "" Vector__XXX
 SG_ VCFRONT_a030_ECULogUploadRequest m0 : 33|1@1+ (1,0) [0|0] "" Vector__XXX
 SG_ VCFRONT_a090_APS_MIA m1 : 33|1@1+ (1,0) [0|0] "" Vector__XXX
 SG_ VCFRONT_a150_pumpBatLowRPMCBang m2 : 33|1@1+ (1,0) [0|0] "" Vector__XXX
 SG_ VCFRONT_a210_coolantValveCalib m3 : 33|1@1+ (1,0) [0|0] "" Vector__XXX
 SG_ VCFRONT_a330_epas3sSlowTripOC m5 : 33|1@1+ (1,0) [0|0] "" Vector__XXX
 SG_ VCFRONT_a390_heatPumpModeConverg m6 : 33|1@1+ (1,0) [0|0] "" Vector__XXX
 SG_ VCFRONT_a450_hornSwitchNotPresse m7 : 33|1@1+ (1,0) [0|0] "" Vector__XXX
 SG_ VCFRONT_a510_LVBatteryRecoveryTi m8 : 33|1@1+ (1,0) [0|0] "" Vector__XXX
 SG_ VCFRONT_a570_headlampsAdaptedToL m9 : 33|1@1+ (1,0) [0|0] "" Vector__XXX
 SG_ VCFRONT_a630_leftHeadlampFactory m10 : 33|1@1+ (1,0) [0|0] "" Vector__XXX
 SG_ VCFRONT_a029_CoreDump m0 : 32|1@1+ (1,0) [0|0] "" Vector__XXX
 SG_ VCFRONT_a089_IBST_MIA m1 : 32|1@1+ (1,0) [0|0] "" Vector__XXX
 SG_ VCFRONT_a149_BLEFrontPowerCycled m2 : 32|1@1+ (1,0) [0|0] "" Vector__XXX
 SG_ VCFRONT_a209_brakeFluidSNA m3 : 32|1@1+ (1,0) [0|0] "" Vector__XXX
 SG_ VCFRONT_a269_drveBlckdVltgeTooLo m4 : 32|1@1+ (1,0) [0|0] "" Vector__XXX
 SG_ VCFRONT_a329_epas3pSlowTripOC m5 : 32|1@1+ (1,0) [0|0] "" Vector__XXX
 SG_ VCFRONT_a389_frunkInhibitingRele m6 : 32|1@1+ (1,0) [0|0] "" Vector__XXX
 SG_ VCFRONT_a449_hornSwitchStuckOn m7 : 32|1@1+ (1,0) [0|0] "" Vector__XXX
 SG_ VCFRONT_a509_vcrightEFuseLoadShe m8 : 32|1@1+ (1,0) [0|0] "" Vector__XXX
 SG_ VCFRONT_a569_rightDaytimeRunning m9 : 32|1@1+ (1,0) [0|0] "" Vector__XXX
 SG_ VCFRONT_a629_TLVBMS_PackTemperat m10 : 32|1@1+ (1,0) [0|0] "" Vector__XXX
 SG_ VCFRONT_a088_DIRER_MIA m1 : 31|1@1+ (1,0) [0|0] "" Vector__XXX
 SG_ VCFRONT_a148_thmlFanSoftStall m2 : 31|1@1+ (1,0) [0|0] "" Vector__XXX
 SG_ VCFRONT_a208_brakeFluidLow m3 : 31|1@1+ (1,0) [0|0] "" Vector__XXX
 SG_ VCFRONT_a268_vbatFusedVoltageMis m4 : 31|1@1+ (1,0) [0|0] "" Vector__XXX
 SG_ VCFRONT_a328_pcsSlowTripOC m5 : 31|1@1+ (1,0) [0|0] "" Vector__XXX
 SG_ VCFRONT_a388_shortedCell m6 : 31|1@1+ (1,0) [0|0] "" Vector__XXX
 SG_ VCFRONT_a448_gtwSteeringBtnReset m7 : 31|1@1+ (1,0) [0|0] "" Vector__XXX
 SG_ VCFRONT_a508_TLVBMS_ImpedanceGro m8 : 31|1@1+ (1,0) [0|0] "" Vector__XXX
 SG_ VCFRONT_a568_leftDaytimeRunningL m9 : 31|1@1+ (1,0) [0|0] "" Vector__XXX
 SG_ VCFRONT_a628_TLVBMS_BmbThermisto m10 : 31|1@1+ (1,0) [0|0] "" Vector__XXX
 SG_ VCFRONT_a087_DIREL_MIA m1 : 30|1@1+ (1,0) [0|0] "" Vector__XXX
 SG_ VCFRONT_a147_pumpPtSoftStall m2 : 30|1@1+ (1,0) [0|0] "" Vector__XXX
 SG_ VCFRONT_a207_vbatFusdSelfTestFai m3 : 30|1@1+ (1,0) [0|0] "" Vector__XXX
 SG_ VCFRONT_a267_EPAS3sVoltageMismat m4 : 30|1@1+ (1,0) [0|0] "" Vector__XXX
 SG_ VCFRONT_a327_vcrightSlowTripOC m5 : 30|1@1+ (1,0) [0|0] "" Vector__XXX
 SG_ VCFRONT_a387_shortedCellInstc m6 : 30|1@1+ (1,0) [0|0] "" Vector__XXX
 SG_ VCFRONT_a447_cabinHVACUnavailabl m7 : 30|1@1+ (1,0) [0|0] "" Vector__XXX
 SG_ VCFRONT_a507_leftHeadlampAimingF m8 : 30|1@1+ (1,0) [0|0] "" Vector__XXX
 SG_ VCFRONT_a567_rightFrontTurnLight m9 : 30|1@1+ (1,0) [0|0] "" Vector__XXX
 SG_ VCFRONT_a627_LVBatteryUnrecovera m10 : 30|1@1+ (1,0) [0|0] "" Vector__XXX
 SG_ VCFRONT_a086_VCBATT_MIA m1 : 29|1@1+ (1,0) [0|0] "" Vector__XXX
 SG_ VCFRONT_a146_pumpBatSoftStall m2 : 29|1@1+ (1,0) [0|0] "" Vector__XXX
 SG_ VCFRONT_a206_espSelfTestFail m3 : 29|1@1+ (1,0) [0|0] "" Vector__XXX
 SG_ VCFRONT_a266_EPAS3pVoltageMismat m4 : 29|1@1+ (1,0) [0|0] "" Vector__XXX
 SG_ VCFRONT_a326_vcleftSlowTripOC m5 : 29|1@1+ (1,0) [0|0] "" Vector__XXX
 SG_ VCFRONT_a386_exvMotorWarning m6 : 29|1@1+ (1,0) [0|0] "" Vector__XXX
 SG_ VCFRONT_a446_cabinHVACUnavailabl m7 : 29|1@1+ (1,0) [0|0] "" Vector__XXX
 SG_ VCFRONT_a506_invalidRefrigerantS m8 : 29|1@1+ (1,0) [0|0] "" Vector__XXX
 SG_ VCFRONT_a566_leftFrontTurnLightF m9 : 29|1@1+ (1,0) [0|0] "" Vector__XXX
 SG_ VCFRONT_a626_LVBatteryResistance m10 : 29|1@1+ (1,0) [0|0] "" Vector__XXX
 SG_ VCFRONT_a085_CCCM_MIA m1 : 28|1@1+ (1,0) [0|0] "" Vector__XXX
 SG_ VCFRONT_a145_thmlFanICTransFault m2 : 28|1@1+ (1,0) [0|0] "" Vector__XXX
 SG_ VCFRONT_a205_iBoosterSelfTestFai m3 : 28|1@1+ (1,0) [0|0] "" Vector__XXX
 SG_ VCFRONT_a265_ESPVoltageMismatch m4 : 28|1@1+ (1,0) [0|0] "" Vector__XXX
 SG_ VCFRONT_a325_vbatFusedOvertempMa m5 : 28|1@1+ (1,0) [0|0] "" Vector__XXX
 SG_ VCFRONT_a385_ccRightExvWarning m6 : 28|1@1+ (1,0) [0|0] "" Vector__XXX
 SG_ VCFRONT_a445_drv8703SpiFaultDBG m7 : 28|1@1+ (1,0) [0|0] "" Vector__XXX
 SG_ VCFRONT_a505_BLEFrontUnderVoltag m8 : 28|1@1+ (1,0) [0|0] "" Vector__XXX
 SG_ VCFRONT_a565_userPresenceDisplay m9 : 28|1@1+ (1,0) [0|0] "" Vector__XXX
 SG_ VCFRONT_a084_TPMS_MIA m1 : 27|1@1+ (1,0) [0|0] "" Vector__XXX
 SG_ VCFRONT_a144_pumpPtICTransFault m2 : 27|1@1+ (1,0) [0|0] "" Vector__XXX
 SG_ VCFRONT_a204_epas3sSelfTestFail m3 : 27|1@1+ (1,0) [0|0] "" Vector__XXX
 SG_ VCFRONT_a264_iBoosterVoltageMism m4 : 27|1@1+ (1,0) [0|0] "" Vector__XXX
 SG_ VCFRONT_a324_espOvertempMax m5 : 27|1@1+ (1,0) [0|0] "" Vector__XXX
 SG_ VCFRONT_a384_ccLeftExvWarning m6 : 27|1@1+ (1,0) [0|0] "" Vector__XXX
 SG_ VCFRONT_a444_drv8703Fault m7 : 27|1@1+ (1,0) [0|0] "" Vector__XXX
 SG_ VCFRONT_a504_airInRefrigerantDet m8 : 27|1@1+ (1,0) [0|0] "" Vector__XXX
 SG_ VCFRONT_a564_leftHeadlampAimingD m9 : 27|1@1+ (1,0) [0|0] "" Vector__XXX
 SG_ VCFRONT_a083_VCLEFT_IPC_MIA m1 : 26|1@1+ (1,0) [0|0] "" Vector__XXX
 SG_ VCFRONT_a143_pumpBatICTransFault m2 : 26|1@1+ (1,0) [0|0] "" Vector__XXX
 SG_ VCFRONT_a203_epas3pSelfTestFail m3 : 26|1@1+ (1,0) [0|0] "" Vector__XXX
 SG_ VCFRONT_a263_pcsVoltageMismatch m4 : 26|1@1+ (1,0) [0|0] "" Vector__XXX
 SG_ VCFRONT_a323_iboosterOvertempMax m5 : 26|1@1+ (1,0) [0|0] "" Vector__XXX
 SG_ VCFRONT_a383_lccExvWarning m6 : 26|1@1+ (1,0) [0|0] "" Vector__XXX
 SG_ VCFRONT_a443_TLVBMS_BmbDieOverTe m7 : 26|1@1+ (1,0) [0|0] "" Vector__XXX
 SG_ VCFRONT_a503_TLVBMS_BrickExtende m8 : 26|1@1+ (1,0) [0|0] "" Vector__XXX
 SG_ VCFRONT_a563_chargePortDoorOpenB m9 : 26|1@1+ (1,0) [0|0] "" Vector__XXX
 SG_ VCFRONT_a623_LVUnhealthy m10 : 26|1@1+ (1,0) [0|0] "" Vector__XXX
 SG_ VCFRONT_a022_TaskInitError m0 : 25|1@1+ (1,0) [0|0] "" Vector__XXX
 SG_ VCFRONT_a082_VCRIGHT_IPC_MIA m1 : 25|1@1+ (1,0) [0|0] "" Vector__XXX
 SG_ VCFRONT_a142_exvMotorFault m2 : 25|1@1+ (1,0) [0|0] "" Vector__XXX
 SG_ VCFRONT_a202_pcsSelfTestFail m3 : 25|1@1+ (1,0) [0|0] "" Vector__XXX
 SG_ VCFRONT_a262_vcrightVoltageMisma m4 : 25|1@1+ (1,0) [0|0] "" Vector__XXX
 SG_ VCFRONT_a322_epas3sOvertempMax m5 : 25|1@1+ (1,0) [0|0] "" Vector__XXX
 SG_ VCFRONT_a382_recircExvWarning m6 : 25|1@1+ (1,0) [0|0] "" Vector__XXX
 SG_ VCFRONT_a442_TLVBMS_SocChange m7 : 25|1@1+ (1,0) [0|0] "" Vector__XXX
 SG_ VCFRONT_a502_TLVBMS_WeakShortImp m8 : 25|1@1+ (1,0) [0|0] "" Vector__XXX
 SG_ VCFRONT_a562_LVBMSModuleOvertemp m9 : 25|1@1+ (1,0) [0|0] "" Vector__XXX
 SG_ VCFRONT_a021_TaskSchedulerError m0 : 24|1@1+ (1,0) [0|0] "" Vector__XXX
 SG_ VCFRONT_a141_coolantTempBatSns m2 : 24|1@1+ (1,0) [0|0] "" Vector__XXX
 SG_ VCFRONT_a201_vcrightSelfTestFail m3 : 24|1@1+ (1,0) [0|0] "" Vector__XXX
 SG_ VCFRONT_a261_vcleftVoltageMismat m4 : 24|1@1+ (1,0) [0|0] "" Vector__XXX
 SG_ VCFRONT_a321_epas3pOvertempMax m5 : 24|1@1+ (1,0) [0|0] "" Vector__XXX
 SG_ VCFRONT_a381_evaporatorExvWarnin m6 : 24|1@1+ (1,0) [0|0] "" Vector__XXX
 SG_ VCFRONT_a441_TLVBMS_ResetNeededF m7 : 24|1@1+ (1,0) [0|0] "" Vector__XXX
 SG_ VCFRONT_a501_vnf1048Configuratio m8 : 24|1@1+ (1,0) [0|0] "" Vector__XXX
 SG_ VCFRONT_a561_LVBMSEFuseOvertempe m9 : 24|1@1+ (1,0) [0|0] "" Vector__XXX
 SG_ VCFRONT_a140_coolantTempPtSns m2 : 23|1@1+ (1,0) [0|0] "" Vector__XXX
 SG_ VCFRONT_a200_vcleftSelfTestFail m3 : 23|1@1+ (1,0) [0|0] "" Vector__XXX
 SG_ VCFRONT_a260_deadLVBattery m4 : 23|1@1+ (1,0) [0|0] "" Vector__XXX
 SG_ VCFRONT_a320_pcsOvertempMax m5 : 23|1@1+ (1,0) [0|0] "" Vector__XXX
 SG_ VCFRONT_a380_chillerExvWarning m6 : 23|1@1+ (1,0) [0|0] "" Vector__XXX
 SG_ VCFRONT_a440_TLVBMS_PackSNInvali m7 : 23|1@1+ (1,0) [0|0] "" Vector__XXX
 SG_ VCFRONT_a500_eFuseASICStateMisma m8 : 23|1@1+ (1,0) [0|0] "" Vector__XXX
 SG_ VCFRONT_a560_compressorHighSuper m9 : 23|1@1+ (1,0) [0|0] "" Vector__XXX
 SG_ VCFRONT_a139_refrigSuctPresSns m2 : 22|1@1+ (1,0) [0|0] "" Vector__XXX
 SG_ VCFRONT_a199_PRVCANUndertrminate m3 : 22|1@1+ (1,0) [0|0] "" Vector__XXX
 SG_ VCFRONT_a259_LVVoltageDropOnHigh m4 : 22|1@1+ (1,0) [0|0] "" Vector__XXX
 SG_ VCFRONT_a319_vcrightOvertempMax m5 : 22|1@1+ (1,0) [0|0] "" Vector__XXX
 SG_ VCFRONT_a379_shortedCellTestRunD m6 : 22|1@1+ (1,0) [0|0] "" Vector__XXX
 SG_ VCFRONT_a439_TLVBMS_PackOverTemp m7 : 22|1@1+ (1,0) [0|0] "" Vector__XXX
 SG_ VCFRONT_a499_loadShedPumpFlowReq m8 : 22|1@1+ (1,0) [0|0] "" Vector__XXX
 SG_ VCFRONT_a559_LVBatteryLowSOC m9 : 22|1@1+ (1,0) [0|0] "" Vector__XXX
 SG_ VCFRONT_a619_frunkSwitchReleaseT m10 : 22|1@1+ (1,0) [0|0] "" Vector__XXX
 SG_ VCFRONT_a138_refrigSuctTempSns m2 : 21|1@1+ (1,0) [0|0] "" Vector__XXX
 SG_ VCFRONT_a198_PRVCANOverterminate m3 : 21|1@1+ (1,0) [0|0] "" Vector__XXX
 SG_ VCFRONT_a258_resistanceEstimatio m4 : 21|1@1+ (1,0) [0|0] "" Vector__XXX
 SG_ VCFRONT_a318_vcleftOvertempMax m5 : 21|1@1+ (1,0) [0|0] "" Vector__XXX
 SG_ VCFRONT_a378_wiperECUDebug m6 : 21|1@1+ (1,0) [0|0] "" Vector__XXX
 SG_ VCFRONT_a438_TLVBMS_PackOverTemp m7 : 21|1@1+ (1,0) [0|0] "" Vector__XXX
 SG_ VCFRONT_a498_TLVBMS_ImpedanceTes m8 : 21|1@1+ (1,0) [0|0] "" Vector__XXX
 SG_ VCFRONT_a558_rightHeadlampAiming m9 : 21|1@1+ (1,0) [0|0] "" Vector__XXX
 SG_ VCFRONT_a618_cabinCoolingCapacit m10 : 21|1@1+ (1,0) [0|0] "" Vector__XXX
 SG_ VCFRONT_a017_NVMMStatusDbg m0 : 20|1@1+ (1,0) [0|0] "" Vector__XXX
 SG_ VCFRONT_a137_refrigDischPresSns m2 : 20|1@1+ (1,0) [0|0] "" Vector__XXX
 SG_ VCFRONT_a197_prechargeDCRData3 m3 : 20|1@1+ (1,0) [0|0] "" Vector__XXX
 SG_ VCFRONT_a257_portExpanderVOR m4 : 20|1@1+ (1,0) [0|0] "" Vector__XXX
 SG_ VCFRONT_a317_vbatFusedOvertempSl m5 : 20|1@1+ (1,0) [0|0] "" Vector__XXX
 SG_ VCFRONT_a377_wiperParkFault m6 : 20|1@1+ (1,0) [0|0] "" Vector__XXX
 SG_ VCFRONT_a437_TLVBMS_NvmRegistrat m7 : 20|1@1+ (1,0) [0|0] "" Vector__XXX
 SG_ VCFRONT_a497_LVBatteryWarnDiscon m8 : 20|1@1+ (1,0) [0|0] "" Vector__XXX
 SG_ VCFRONT_a016_NVMMRecordError m0 : 19|1@1+ (1,0) [0|0] "" Vector__XXX
 SG_ VCFRONT_a136_refrigDischTempSns m2 : 19|1@1+ (1,0) [0|0] "" Vector__XXX
 SG_ VCFRONT_a196_discnctdLVBattery m3 : 19|1@1+ (1,0) [0|0] "" Vector__XXX
 SG_ VCFRONT_a256_compTornShaftSeal m4 : 19|1@1+ (1,0) [0|0] "" Vector__XXX
 SG_ VCFRONT_a316_espOvertempSlope m5 : 19|1@1+ (1,0) [0|0] "" Vector__XXX
 SG_ VCFRONT_a376_controllerWakeupDeb m6 : 19|1@1+ (1,0) [0|0] "" Vector__XXX
 SG_ VCFRONT_a436_TLVBMS_DischargeOve m7 : 19|1@1+ (1,0) [0|0] "" Vector__XXX
 SG_ VCFRONT_a496_LVBatteryExitDriveW m8 : 19|1@1+ (1,0) [0|0] "" Vector__XXX
 SG_ VCFRONT_a556_falseTriggerOfDiscn m9 : 19|1@1+ (1,0) [0|0] "" Vector__XXX
 SG_ VCFRONT_a015_NVMMError m0 : 18|1@1+ (1,0) [0|0] "" Vector__XXX
 SG_ VCFRONT_a135_coolantLevelLow m2 : 18|1@1+ (1,0) [0|0] "" Vector__XXX
 SG_ VCFRONT_a195_drveBlckdVltgeTooHg m3 : 18|1@1+ (1,0) [0|0] "" Vector__XXX
 SG_ VCFRONT_a255_pumpPtStopped m4 : 18|1@1+ (1,0) [0|0] "" Vector__XXX
 SG_ VCFRONT_a315_iboosterOvertempSlo m5 : 18|1@1+ (1,0) [0|0] "" Vector__XXX
 SG_ VCFRONT_a375_refVoltageOutOfSpec m6 : 18|1@1+ (1,0) [0|0] "" Vector__XXX
 SG_ VCFRONT_a435_TLVBMS_DchgCurrentL m7 : 18|1@1+ (1,0) [0|0] "" Vector__XXX
 SG_ VCFRONT_a495_LVBatteryRecoveryBl m8 : 18|1@1+ (1,0) [0|0] "" Vector__XXX
 SG_ VCFRONT_a555_LVBatteryCellRebala m9 : 18|1@1+ (1,0) [0|0] "" Vector__XXX
 SG_ VCFRONT_a615_TLVBMS_BatteryHeate m10 : 18|1@1+ (1,0) [0|0] "" Vector__XXX
 SG_ VCFRONT_a134_fusedHighEFuseTrip m2 : 17|1@1+ (1,0) [0|0] "" Vector__XXX
 SG_ VCFRONT_a194_iBoosterRetry m3 : 17|1@1+ (1,0) [0|0] "" Vector__XXX
 SG_ VCFRONT_a254_pumpBatStopped m4 : 17|1@1+ (1,0) [0|0] "" Vector__XXX
 SG_ VCFRONT_a314_epas3sOvertempSlope m5 : 17|1@1+ (1,0) [0|0] "" Vector__XXX
 SG_ VCFRONT_a374_lccInletSolenoidFau m6 : 17|1@1+ (1,0) [0|0] "" Vector__XXX
 SG_ VCFRONT_a434_TLVBMS_ConfigInitFa m7 : 17|1@1+ (1,0) [0|0] "" Vector__XXX
 SG_ VCFRONT_a494_LVBatteryTempBlocki m8 : 17|1@1+ (1,0) [0|0] "" Vector__XXX
 SG_ VCFRONT_a614_coolantSysDriverles m10 : 17|1@1+ (1,0) [0|0] "" Vector__XXX
 SG_ VCFRONT_a013_AlertManagerFault m0 : 16|1@1+ (1,0) [0|0] "" Vector__XXX
 SG_ VCFRONT_a133_espEFuseTrip m2 : 16|1@1+ (1,0) [0|0] "" Vector__XXX
 SG_ VCFRONT_a193_mcuAudioRetry m3 : 16|1@1+ (1,0) [0|0] "" Vector__XXX
 SG_ VCFRONT_a253_maxChrgeSssionTmeou m4 : 16|1@1+ (1,0) [0|0] "" Vector__XXX
 SG_ VCFRONT_a313_epas3pOvertempSlope m5 : 16|1@1+ (1,0) [0|0] "" Vector__XXX
 SG_ VCFRONT_a373_chillerControlFlood m6 : 16|1@1+ (1,0) [0|0] "" Vector__XXX
 SG_ VCFRONT_a433_TLVBMS_ConfigFromBm m7 : 16|1@1+ (1,0) [0|0] "" Vector__XXX
 SG_ VCFRONT_a493_TLVBMS_SocImbalance m8 : 16|1@1+ (1,0) [0|0] "" Vector__XXX
 SG_ VCFRONT_a553_rightHeadlampSoftSh m9 : 16|1@1+ (1,0) [0|0] "" Vector__XXX
 SG_ VCFRONT_a613_selfTestsBlockingDr m10 : 16|1@1+ (1,0) [0|0] "" Vector__XXX
 SG_ VCFRONT_a012_CPUReset m0 : 15|1@1+ (1,0) [0|0] "" Vector__XXX
 SG_ VCFRONT_a132_iBoosterEFuseTrip m2 : 15|1@1+ (1,0) [0|0] "" Vector__XXX
 SG_ VCFRONT_a192_vehicleLoadShed m3 : 15|1@1+ (1,0) [0|0] "" Vector__XXX
 SG_ VCFRONT_a252_controllerWakeup m4 : 15|1@1+ (1,0) [0|0] "" Vector__XXX
 SG_ VCFRONT_a312_pcsOvertempSlope m5 : 15|1@1+ (1,0) [0|0] "" Vector__XXX
 SG_ VCFRONT_a372_TLVBMS_BmbHwOverVol m6 : 15|1@1+ (1,0) [0|0] "" Vector__XXX
 SG_ VCFRONT_a432_TLVBMS_ChargeRegula m7 : 15|1@1+ (1,0) [0|0] "" Vector__XXX
 SG_ VCFRONT_a492_TLVBMS_SocImbalance m8 : 15|1@1+ (1,0) [0|0] "" Vector__XXX
 SG_ VCFRONT_a552_eFuseSelfTestFailur m9 : 15|1@1+ (1,0) [0|0] "" Vector__XXX
 SG_ VCFRONT_a612_LVUnhealthyLoadShed m10 : 15|1@1+ (1,0) [0|0] "" Vector__XXX
 SG_ VCFRONT_a131_epas3sEFuseTrip m2 : 14|1@1+ (1,0) [0|0] "" Vector__XXX
 SG_ VCFRONT_a191_exitDriveLowLVBusVo m3 : 14|1@1+ (1,0) [0|0] "" Vector__XXX
 SG_ VCFRONT_a251_UIWakeupTrigger m4 : 14|1@1+ (1,0) [0|0] "" Vector__XXX
 SG_ VCFRONT_a311_vcrightOvertempSlop m5 : 14|1@1+ (1,0) [0|0] "" Vector__XXX
 SG_ VCFRONT_a371_failureToPrechargeR m6 : 14|1@1+ (1,0) [0|0] "" Vector__XXX
 SG_ VCFRONT_a431_TLVBMS_ChargeOverCu m7 : 14|1@1+ (1,0) [0|0] "" Vector__XXX
 SG_ VCFRONT_a491_rightHeadlampLastPo m8 : 14|1@1+ (1,0) [0|0] "" Vector__XXX
 SG_ VCFRONT_a551_leftHeadlampSoftSho m9 : 14|1@1+ (1,0) [0|0] "" Vector__XXX
 SG_ VCFRONT_a611_poorRadiatorHeatRej m10 : 14|1@1+ (1,0) [0|0] "" Vector__XXX
 SG_ VCFRONT_a010_ExtSupplyVoltError m0 : 13|1@1+ (1,0) [0|0] "" Vector__XXX
 SG_ VCFRONT_a130_epas3pEFuseTrip m2 : 13|1@1+ (1,0) [0|0] "" Vector__XXX
 SG_ VCFRONT_a190_linSchedulingInfo m3 : 13|1@1+ (1,0) [0|0] "" Vector__XXX
 SG_ VCFRONT_a250_headlampsNotAimed m4 : 13|1@1+ (1,0) [0|0] "" Vector__XXX
 SG_ VCFRONT_a310_vcleftOvertempSlope m5 : 13|1@1+ (1,0) [0|0] "" Vector__XXX
 SG_ VCFRONT_a370_noLVSupportSocTooLo m6 : 13|1@1+ (1,0) [0|0] "" Vector__XXX
 SG_ VCFRONT_a430_TLVBMS_ChargeCurren m7 : 13|1@1+ (1,0) [0|0] "" Vector__XXX
 SG_ VCFRONT_a490_coolantPumpsNotIden m8 : 13|1@1+ (1,0) [0|0] "" Vector__XXX
 SG_ VCFRONT_a610_frunkOpenFailureMet m10 : 13|1@1+ (1,0) [0|0] "" Vector__XXX
 SG_ VCFRONT_a670_TLVBMS_EfuseStateIr m11 : 13|1@1+ (1,0) [0|0] "" Vector__XXX
 SG_ VCFRONT_a009_LCCPurgeAttempted m0 : 12|1@1+ (1,0) [0|0] "" Vector__XXX
 SG_ VCFRONT_a129_pcsEFuseTrip m2 : 12|1@1+ (1,0) [0|0] "" Vector__XXX
 SG_ VCFRONT_a189_IBSMIA m3 : 12|1@1+ (1,0) [0|0] "" Vector__XXX
 SG_ VCFRONT_a249_coolantValveBadMode m4 : 12|1@1+ (1,0) [0|0] "" Vector__XXX
 SG_ VCFRONT_a309_frunkEmergencyRelea m5 : 12|1@1+ (1,0) [0|0] "" Vector__XXX
 SG_ VCFRONT_a369_reducedPowerDischar m6 : 12|1@1+ (1,0) [0|0] "" Vector__XXX
 SG_ VCFRONT_a429_TLVBMS_CapacityTest m7 : 12|1@1+ (1,0) [0|0] "" Vector__XXX
 SG_ VCFRONT_a489_ValveStuckFlagged m8 : 12|1@1+ (1,0) [0|0] "" Vector__XXX
 SG_ VCFRONT_a609_autopilotDriveNotAu m10 : 12|1@1+ (1,0) [0|0] "" Vector__XXX
 SG_ VCFRONT_a669_thermalHVPowerBudge m11 : 12|1@1+ (1,0) [0|0] "" Vector__XXX
 SG_ VCFRONT_a008_adaptiveHeadlightsU m0 : 11|1@1+ (1,0) [0|0] "" Vector__XXX
 SG_ VCFRONT_a128_vcrightEFuseTrip m2 : 11|1@1+ (1,0) [0|0] "" Vector__XXX
 SG_ VCFRONT_a188_sleepFailed m3 : 11|1@1+ (1,0) [0|0] "" Vector__XXX
 SG_ VCFRONT_a248_voltageOutOfSpec m4 : 11|1@1+ (1,0) [0|0] "" Vector__XXX
 SG_ VCFRONT_a308_frunkSecUnderCurren m5 : 11|1@1+ (1,0) [0|0] "" Vector__XXX
 SG_ VCFRONT_a368_dischargeRoutineExi m6 : 11|1@1+ (1,0) [0|0] "" Vector__XXX
 SG_ VCFRONT_a428_TLVBMS_CacImbalance m7 : 11|1@1+ (1,0) [0|0] "" Vector__XXX
 SG_ VCFRONT_a488_rightHeadlampSteppe m8 : 11|1@1+ (1,0) [0|0] "" Vector__XXX
 SG_ VCFRONT_a548_HVFaultLoadShed m9 : 11|1@1+ (1,0) [0|0] "" Vector__XXX
 SG_ VCFRONT_a608_TLVBMS_BleedFetFail m10 : 11|1@1+ (1,0) [0|0] "" Vector__XXX
 SG_ VCFRONT_a668_rightHeadlampRegion m11 : 11|1@1+ (1,0) [0|0] "" Vector__XXX
 SG_ VCFRONT_a127_vcleftEFuseTrip m2 : 10|1@1+ (1,0) [0|0] "" Vector__XXX
 SG_ VCFRONT_a187_busesNotSleeping m3 : 10|1@1+ (1,0) [0|0] "" Vector__XXX
 SG_ VCFRONT_a247_evapSolenoidFault m4 : 10|1@1+ (1,0) [0|0] "" Vector__XXX
 SG_ VCFRONT_a307_frunkSecOverCurrent m5 : 10|1@1+ (1,0) [0|0] "" Vector__XXX
 SG_ VCFRONT_a367_dischargeRoutineEnt m6 : 10|1@1+ (1,0) [0|0] "" Vector__XXX
 SG_ VCFRONT_a427_TLVBMS_CacChange m7 : 10|1@1+ (1,0) [0|0] "" Vector__XXX
 SG_ VCFRONT_a487_leftHeadlampLastPos m8 : 10|1@1+ (1,0) [0|0] "" Vector__XXX
 SG_ VCFRONT_a547_postCrashLoadShed m9 : 10|1@1+ (1,0) [0|0] "" Vector__XXX
 SG_ VCFRONT_a607_sleepPowerDebug m10 : 10|1@1+ (1,0) [0|0] "" Vector__XXX
 SG_ VCFRONT_a667_leftHeadlampRegionO m11 : 10|1@1+ (1,0) [0|0] "" Vector__XXX
 SG_ VCFRONT_a006_CANTX_cyclicError m0 : 9|1@1+ (1,0) [0|0] "" Vector__XXX
 SG_ VCFRONT_a126_thmlFanICWarning m2 : 9|1@1+ (1,0) [0|0] "" Vector__XXX
 SG_ VCFRONT_a186_noDriveChgCableCon m3 : 9|1@1+ (1,0) [0|0] "" Vector__XXX
 SG_ VCFRONT_a246_pump2EFuseFault m4 : 9|1@1+ (1,0) [0|0] "" Vector__XXX
 SG_ VCFRONT_a306_frunkPriUnderCurren m5 : 9|1@1+ (1,0) [0|0] "" Vector__XXX
 SG_ VCFRONT_a366_burnInRoutineExited m6 : 9|1@1+ (1,0) [0|0] "" Vector__XXX
 SG_ VCFRONT_a426_TLVBMS_BusVoltageTo m7 : 9|1@1+ (1,0) [0|0] "" Vector__XXX
 SG_ VCFRONT_a486_mcuGraphicsEFuseFau m8 : 9|1@1+ (1,0) [0|0] "" Vector__XXX
 SG_ VCFRONT_a546_leftLowOrHighBeamLi m9 : 9|1@1+ (1,0) [0|0] "" Vector__XXX
 SG_ VCFRONT_a606_chillerBattHeatingE m10 : 9|1@1+ (1,0) [0|0] "" Vector__XXX
 SG_ VCFRONT_a666_rightHeadlampRetryI m11 : 9|1@1+ (1,0) [0|0] "" Vector__XXX
 SG_ VCFRONT_a005_CANTXError m0 : 8|1@1+ (1,0) [0|0] "" Vector__XXX
 SG_ VCFRONT_a125_thmlFanICLatchFault m2 : 8|1@1+ (1,0) [0|0] "" Vector__XXX
 SG_ VCFRONT_a185_washerFluidLow m3 : 8|1@1+ (1,0) [0|0] "" Vector__XXX
 SG_ VCFRONT_a245_pump1EFuseFault m4 : 8|1@1+ (1,0) [0|0] "" Vector__XXX
 SG_ VCFRONT_a305_frunkPriOverCurrent m5 : 8|1@1+ (1,0) [0|0] "" Vector__XXX
 SG_ VCFRONT_a365_burnInRoutineEntere m6 : 8|1@1+ (1,0) [0|0] "" Vector__XXX
 SG_ VCFRONT_a425_TLVBMS_BusVoltageTo m7 : 8|1@1+ (1,0) [0|0] "" Vector__XXX
 SG_ VCFRONT_a485_leftHeadlampMigrati m8 : 8|1@1+ (1,0) [0|0] "" Vector__XXX
 SG_ VCFRONT_a545_LVBatteryTypeUnknow m9 : 8|1@1+ (1,0) [0|0] "" Vector__XXX
 SG_ VCFRONT_a605_sleepBypassPowerOff m10 : 8|1@1+ (1,0) [0|0] "" Vector__XXX
 SG_ VCFRONT_a665_leftHeadlampRetryIn m11 : 8|1@1+ (1,0) [0|0] "" Vector__XXX
 SG_ VCFRONT_a004_adaptiveHeadlightsU m0 : 7|1@1+ (1,0) [0|0] "" Vector__XXX
 SG_ VCFRONT_a064_busSleepReqTimeout m1 : 7|1@1+ (1,0) [0|0] "" Vector__XXX
 SG_ VCFRONT_a124_pumpPtICWarning m2 : 7|1@1+ (1,0) [0|0] "" Vector__XXX
 SG_ VCFRONT_a184_cabinCoolingPerform m3 : 7|1@1+ (1,0) [0|0] "" Vector__XXX
 SG_ VCFRONT_a244_sleepBypassFault m4 : 7|1@1+ (1,0) [0|0] "" Vector__XXX
 SG_ VCFRONT_a304_frunkReleaseFailed m5 : 7|1@1+ (1,0) [0|0] "" Vector__XXX
 SG_ VCFRONT_a364_heaterTypeEstimatio m6 : 7|1@1+ (1,0) [0|0] "" Vector__XXX
 SG_ VCFRONT_a424_TLVBMS_BrickUnderVo m7 : 7|1@1+ (1,0) [0|0] "" Vector__XXX
 SG_ VCFRONT_a484_headlampLevelingRid m8 : 7|1@1+ (1,0) [0|0] "" Vector__XXX
 SG_ VCFRONT_a544_LVBatteryCommsBusTu m9 : 7|1@1+ (1,0) [0|0] "" Vector__XXX
 SG_ VCFRONT_a664_rightHeadlampUartWa m11 : 7|1@1+ (1,0) [0|0] "" Vector__XXX
 SG_ VCFRONT_a003_SWAssertion m0 : 6|1@1+ (1,0) [0|0] "" Vector__XXX
 SG_ VCFRONT_a063_SwitchFault m1 : 6|1@1+ (1,0) [0|0] "" Vector__XXX
 SG_ VCFRONT_a123_pumpPtICLatchFault m2 : 6|1@1+ (1,0) [0|0] "" Vector__XXX
 SG_ VCFRONT_a183_replaceLVBattery2 m3 : 6|1@1+ (1,0) [0|0] "" Vector__XXX
 SG_ VCFRONT_a243_LVOverchargeInstc m4 : 6|1@1+ (1,0) [0|0] "" Vector__XXX
 SG_ VCFRONT_a303_frunkAccessPostActi m5 : 6|1@1+ (1,0) [0|0] "" Vector__XXX
 SG_ VCFRONT_a363_TLVBMS_BleedBasedWe m6 : 6|1@1+ (1,0) [0|0] "" Vector__XXX
 SG_ VCFRONT_a423_TLVBMS_BrickUnderVo m7 : 6|1@1+ (1,0) [0|0] "" Vector__XXX
 SG_ VCFRONT_a483_leftHeadlampStepper m8 : 6|1@1+ (1,0) [0|0] "" Vector__XXX
 SG_ VCFRONT_a543_compressorLowFlowDe m9 : 6|1@1+ (1,0) [0|0] "" Vector__XXX
 SG_ VCFRONT_a663_leftHeadlampUartWat m11 : 6|1@1+ (1,0) [0|0] "" Vector__XXX
 SG_ VCFRONT_a002_PowerLossReset m0 : 5|1@1+ (1,0) [0|0] "" Vector__XXX
 SG_ VCFRONT_a062_XCPWasConnected m1 : 5|1@1+ (1,0) [0|0] "" Vector__XXX
 SG_ VCFRONT_a122_pumpBatICWarning m2 : 5|1@1+ (1,0) [0|0] "" Vector__XXX
 SG_ VCFRONT_a182_replaceLVBattery m3 : 5|1@1+ (1,0) [0|0] "" Vector__XXX
 SG_ VCFRONT_a242_drveBlckdVltgeTooLo m4 : 5|1@1+ (1,0) [0|0] "" Vector__XXX
 SG_ VCFRONT_a302_wiperCommError m5 : 5|1@1+ (1,0) [0|0] "" Vector__XXX
 SG_ VCFRONT_a362_TLVBMS_AllSocCorrec m6 : 5|1@1+ (1,0) [0|0] "" Vector__XXX
 SG_ VCFRONT_a482_rightHeadlampMigrat m8 : 5|1@1+ (1,0) [0|0] "" Vector__XXX
 SG_ VCFRONT_a542_refrigerantReclaim m9 : 5|1@1+ (1,0) [0|0] "" Vector__XXX
 SG_ VCFRONT_a662_mculessRightHeadlam m11 : 5|1@1+ (1,0) [0|0] "" Vector__XXX
 SG_ VCFRONT_a001_WatchdogReset m0 : 4|1@1+ (1,0) [0|0] "" Vector__XXX
 SG_ VCFRONT_a061_XCPConnected m1 : 4|1@1+ (1,0) [0|0] "" Vector__XXX
 SG_ VCFRONT_a121_pumpBatICLatchFault m2 : 4|1@1+ (1,0) [0|0] "" Vector__XXX
 SG_ VCFRONT_a181_homelinkMIA m3 : 4|1@1+ (1,0) [0|0] "" Vector__XXX
 SG_ VCFRONT_a301_wipersFactoryDisabl m5 : 4|1@1+ (1,0) [0|0] "" Vector__XXX
 SG_ VCFRONT_a361_washerFluidLowMomen m6 : 4|1@1+ (1,0) [0|0] "" Vector__XXX
 SG_ VCFRONT_a421_leftHeadlampUartCon m7 : 4|1@1+ (1,0) [0|0] "" Vector__XXX
 SG_ VCFRONT_a481_vnf1048SelfTestFail m8 : 4|1@1+ (1,0) [0|0] "" Vector__XXX
 SG_ VCFRONT_a541_LVBatteryChargeOCLe m9 : 4|1@1+ (1,0) [0|0] "" Vector__XXX
 SG_ VCFRONT_a601_autopilotAirPurgeLi m10 : 4|1@1+ (1,0) [0|0] "" Vector__XXX
 SG_ VCFRONT_a661_mculessLeftHeadlamp m11 : 4|1@1+ (1,0) [0|0] "" Vector__XXX
 SG_ VCFRONT_matrixIndex M : 0|4@1+ (1,0) [0|0] "" Vector__XXX

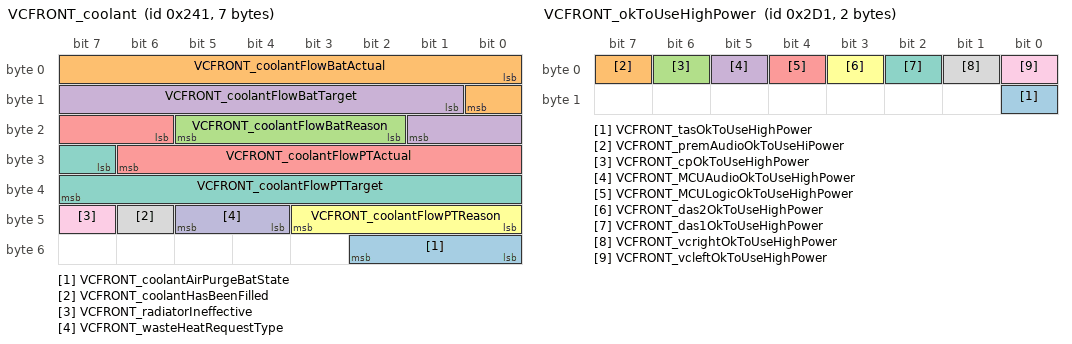
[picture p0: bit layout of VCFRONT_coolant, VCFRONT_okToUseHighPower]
BO_ 577 VCFRONT_coolant: 7 VEH
 SG_ VCFRONT_coolantAirPurgeBatState: 48|3@1+ (1,0) [0|0] "" X
 SG_ VCFRONT_coolantFlowBatActual: 0|9@1+ (0.1,0) [0|0] "LPM" X
 SG_ VCFRONT_coolantFlowBatReason: 18|4@1+ (1,0) [0|0] "" X
 SG_ VCFRONT_coolantFlowBatTarget: 9|9@1+ (0.1,0) [0|0] "LPM" X
 SG_ VCFRONT_coolantFlowPTActual: 22|9@1+ (0.1,0) [0|0] "LPM" X
 SG_ VCFRONT_coolantFlowPTReason: 40|4@1+ (1,0) [0|0] "" X
 SG_ VCFRONT_coolantFlowPTTarget: 31|9@1+ (0.1,0) [0|0] "LPM" X
 SG_ VCFRONT_coolantHasBeenFilled: 46|1@1+ (1,0) [0|0] "" X
 SG_ VCFRONT_radiatorIneffective: 47|1@1+ (1,0) [0|0] "" X
 SG_ VCFRONT_wasteHeatRequestType: 44|2@1+ (1,0) [0|0] "" X

BO_ 753 VCFRONT_eFuseDebugStatus: 8 Vector__XXX
 SG_ VCFRONT_headlampRightTemperature m12 : 56|8@1+ (1,-40) [0|0] "" Vector__XXX
 SG_ VCFRONT_pump2AndAirCompVoltage m14 : 51|12@1+ (0.1,0) [0|0] "" Vector__XXX
 SG_ VCFRONT_headlampRightCurrentFilt m16 : 50|10@1+ (0.027,0) [0|0] "" Vector__XXX
 SG_ VCFRONT_headlampLeftTemperature m12 : 48|8@1+ (1,-40) [0|0] "" Vector__XXX
 SG_ VCFRONT_EPAS3PCurrent m4 : 47|14@1+ (0.1,0) [0|0] "" Vector__XXX
 SG_ VCFRONT_EPAS3SCurrent m5 : 47|14@1+ (0.1,0) [0|0] "" Vector__XXX
 SG_ VCFRONT_ESPMotorCurrent m6 : 47|14@1+ (0.1,0) [0|0] "" Vector__XXX
 SG_ VCFRONT_iBoosterCurrent m3 : 47|14@1+ (0.1,0) [0|0] "" Vector__XXX
 SG_ VCFRONT_leftControllerCurrent m1 : 47|14@1+ (0.1,0) [0|0] "" Vector__XXX
 SG_ VCFRONT_rightControllerCurrent m0 : 47|14@1+ (0.1,0) [0|0] "" Vector__XXX
 SG_ VCFRONT_vbatFusedHighCurrent m13 : 46|16@1+ (0.1,0) [0|0] "" Vector__XXX
 SG_ VCFRONT_ESPValveCurrent m7 : 44|16@1+ (0.01,0) [0|0] "" Vector__XXX
 SG_ VCFRONT_railB_5v m15 : 44|12@1+ (0.005443676098,0) [0|0] "" Vector__XXX
 SG_ VCFRONT_autopilot1Current m8 : 43|10@1+ (0.044,0) [0|0] "" Vector__XXX
 SG_ VCFRONT_autopilot2Current m9 : 43|10@1+ (0.044,0) [0|0] "" Vector__XXX
 SG_ VCFRONT_mcuGraphicsCurrent m18 : 42|16@1+ (0.1,0) [0|0] "" Vector__XXX
 SG_ VCFRONT_mcuGraphicsFault m18 : 41|1@1+ (1,0) [0|0] "" Vector__XXX
 SG_ VCFRONT_IBSUnfilteredTemperature m17 : 40|16@1- (0.01,0) [0|0] "" Vector__XXX
 SG_ VCFRONT_headlampLeftCurrentFilte m16 : 40|10@1+ (0.027,0) [0|0] "" Vector__XXX
 SG_ VCFRONT_headlampRightVoltage m12 : 40|8@1+ (0.1,0) [0|0] "" Vector__XXX
 SG_ VCFRONT_mcuGraphicsState m18 : 40|1@1+ (1,0) [0|0] "" Vector__XXX
 SG_ VCFRONT_pump2AndAirCompCurrent m14 : 35|10@1+ (0.05,0) [0|0] "" Vector__XXX
 SG_ VCFRONT_pump2AndAirCompState m14 : 34|1@1+ (1,0) [0|0] "" Vector__XXX
 SG_ VCFRONT_railA_5v m15 : 32|12@1+ (0.005443676098,0) [0|0] "" Vector__XXX
 SG_ VCFRONT_EPAS3PVoltage m4 : 31|9@1+ (0.1,0) [0|0] "" Vector__XXX
 SG_ VCFRONT_EPAS3SVoltage m5 : 31|14@1+ (0.1,0) [0|0] "" Vector__XXX
 SG_ VCFRONT_ESPMotorVoltage m6 : 31|14@1+ (0.1,0) [0|0] "" Vector__XXX
 SG_ VCFRONT_PCSVoltage m2 : 31|14@1+ (0.1,0) [0|0] "" Vector__XXX
 SG_ VCFRONT_iBoosterVoltage m3 : 31|9@1+ (0.1,0) [0|0] "" Vector__XXX
 SG_ VCFRONT_leftControllerVoltage m1 : 31|14@1+ (0.1,0) [0|0] "" Vector__XXX
 SG_ VCFRONT_rightControllerVoltage m0 : 31|14@1+ (0.1,0) [0|0] "" Vector__XXX
 SG_ VCFRONT_headlampRightCurrent m12 : 30|10@1+ (0.027,0) [0|0] "" Vector__XXX
 SG_ VCFRONT_vbatFusedHighVoltage m13 : 30|16@1+ (0.1,0) [0|0] "" Vector__XXX
 SG_ VCFRONT_headlampRightFault m12 : 29|1@1+ (1,0) [0|0] "" Vector__XXX
 SG_ VCFRONT_ESPValveVoltage m7 : 28|16@1+ (0.1,0) [0|0] "" Vector__XXX
 SG_ VCFRONT_headlampRightState m12 : 28|1@1+ (1,0) [0|0] "" Vector__XXX
 SG_ VCFRONT_autopilot1Voltage m8 : 27|16@1+ (0.1,0) [0|0] "" Vector__XXX
 SG_ VCFRONT_autopilot2Voltage m9 : 27|16@1+ (0.1,0) [0|0] "" Vector__XXX
 SG_ VCFRONT_sleepBypassCurrent m10 : 26|16@1+ (0.1,0) [0|0] "" Vector__XXX
 SG_ VCFRONT_ChargePumpVoltage m16 : 24|16@1+ (0.005443676098,0) [0|0] "" Vector__XXX
 SG_ VCFRONT_dischargedIBSAmpHours m17 : 24|16@1+ (1,0) [0|0] "" Vector__XXX
 SG_ VCFRONT_mcuAudioVoltage m18 : 24|8@1+ (0.1,0) [0|0] "" Vector__XXX
 SG_ VCFRONT_mcuLogicVoltage m11 : 24|8@1+ (0.1,0) [0|0] "" Vector__XXX
 SG_ VCFRONT_pump1AndFanVoltage m14 : 22|12@1+ (0.1,0) [0|0] "" Vector__XXX
 SG_ VCFRONT_headlampLeftVoltage m12 : 20|8@1+ (0.1,0) [0|0] "" Vector__XXX
 SG_ VCFRONT_railB_12v m15 : 20|12@1+ (0.005443676098,0) [0|0] "" Vector__XXX
 SG_ VCFRONT_EPAS3PTemp m4 : 15|11@1+ (0.125,-40) [0|0] "" Vector__XXX
 SG_ VCFRONT_EPAS3STemp m5 : 15|11@1+ (0.125,-40) [0|0] "" Vector__XXX
 SG_ VCFRONT_ESPMotorTemp m6 : 15|11@1+ (0.125,-40) [0|0] "" Vector__XXX
 SG_ VCFRONT_PCSTemp m2 : 15|11@1+ (0.125,-40) [0|0] "" Vector__XXX
 SG_ VCFRONT_iBoosterTemp m3 : 15|11@1+ (0.125,-40) [0|0] "" Vector__XXX
 SG_ VCFRONT_leftControllerTemp m1 : 15|11@1+ (0.125,-40) [0|0] "" Vector__XXX
 SG_ VCFRONT_rightControllerTemp m0 : 15|11@1+ (0.125,-40) [0|0] "" Vector__XXX
 SG_ VCFRONT_vbatFusedHighTemp m13 : 14|11@1+ (0.125,-40) [0|0] "" Vector__XXX
 SG_ VCFRONT_ESPValveTemp m7 : 12|11@1+ (0.125,-40) [0|0] "" Vector__XXX
 SG_ VCFRONT_EPAS3PSelfTestResult m4 : 11|4@1+ (1,0) [0|0] "" Vector__XXX
 SG_ VCFRONT_EPAS3SSelfTestResult m5 : 11|4@1+ (1,0) [0|0] "" Vector__XXX
 SG_ VCFRONT_ESPMotorSelfTestResult m6 : 11|4@1+ (1,0) [0|0] "" Vector__XXX
 SG_ VCFRONT_autopilot1Temp m8 : 11|11@1+ (0.125,-40) [0|0] "" Vector__XXX
 SG_ VCFRONT_autopilot2Temp m9 : 11|11@1+ (0.125,-40) [0|0] "" Vector__XXX
 SG_ VCFRONT_iBoosterSelfTestResult m3 : 11|4@1+ (1,0) [0|0] "" Vector__XXX
 SG_ VCFRONT_pcsSelfTestResult m2 : 11|4@1+ (1,0) [0|0] "" Vector__XXX
 SG_ VCFRONT_vcleftSelfTestResult m1 : 11|4@1+ (1,0) [0|0] "" Vector__XXX
 SG_ VCFRONT_vcrightSelfTestResult m0 : 11|4@1+ (1,0) [0|0] "" Vector__XXX
 SG_ VCFRONT_EPAS3PFault m4 : 10|1@1+ (1,0) [0|0] "" Vector__XXX
 SG_ VCFRONT_EPAS3SFault m5 : 10|1@1+ (1,0) [0|0] "" Vector__XXX
 SG_ VCFRONT_ESPMotorFault m6 : 10|1@1+ (1,0) [0|0] "" Vector__XXX
 SG_ VCFRONT_ESPValveFault m7 : 10|1@1+ (1,0) [0|0] "" Vector__XXX
 SG_ VCFRONT_PCSFault m2 : 10|1@1+ (1,0) [0|0] "" Vector__XXX
 SG_ VCFRONT_autopilot1Fault m8 : 10|1@1+ (1,0) [0|0] "" Vector__XXX
 SG_ VCFRONT_autopilot2Fault m9 : 10|1@1+ (1,0) [0|0] "" Vector__XXX
 SG_ VCFRONT_headlampLeftCurrent m12 : 10|10@1+ (0.027,0) [0|0] "" Vector__XXX
 SG_ VCFRONT_iBoosterFault m3 : 10|1@1+ (1,0) [0|0] "" Vector__XXX
 SG_ VCFRONT_leftControllerFault m1 : 10|1@1+ (1,0) [0|0] "" Vector__XXX
 SG_ VCFRONT_rightControllerFault m0 : 10|1@1+ (1,0) [0|0] "" Vector__XXX
 SG_ VCFRONT_sleepBypassVoltage m10 : 10|16@1+ (0.1,0) [0|0] "" Vector__XXX
 SG_ VCFRONT_vbatFusedSelfTestResult m13 : 10|4@1+ (1,0) [0|0] "" Vector__XXX
 SG_ VCFRONT_headlampLeftFault m12 : 9|1@1+ (1,0) [0|0] "" Vector__XXX
 SG_ VCFRONT_sleepBypassFault m10 : 9|1@1+ (1,0) [0|0] "" Vector__XXX
 SG_ VCFRONT_vbatFusedHighFault m13 : 9|1@1+ (1,0) [0|0] "" Vector__XXX
 SG_ VCFRONT_EPAS3PState m4 : 8|2@1+ (1,0) [0|0] "" Vector__XXX
 SG_ VCFRONT_EPAS3SState m5 : 8|2@1+ (1,0) [0|0] "" Vector__XXX
 SG_ VCFRONT_ESPMotorState m6 : 8|2@1+ (1,0) [0|0] "" Vector__XXX
 SG_ VCFRONT_ESPValveState m7 : 8|2@1+ (1,0) [0|0] "" Vector__XXX
 SG_ VCFRONT_PCSState m2 : 8|2@1+ (1,0) [0|0] "" Vector__XXX
 SG_ VCFRONT_autopilot1State m8 : 8|2@1+ (1,0) [0|0] "" Vector__XXX
 SG_ VCFRONT_autopilot2State m9 : 8|2@1+ (1,0) [0|0] "" Vector__XXX
 SG_ VCFRONT_chargedIBSAmpHours m17 : 8|16@1+ (1,0) [0|0] "" Vector__XXX
 SG_ VCFRONT_eFuseLockoutVoltage m16 : 8|12@1+ (0.005443676098,0) [0|0] "" Vector__XXX
 SG_ VCFRONT_headlampLeftState m12 : 8|1@1+ (1,0) [0|0] "" Vector__XXX
 SG_ VCFRONT_iBoosterState m3 : 8|2@1+ (1,0) [0|0] "" Vector__XXX
 SG_ VCFRONT_leftControllerState m1 : 8|2@1+ (1,0) [0|0] "" Vector__XXX
 SG_ VCFRONT_mcuAudioCurrent m18 : 8|10@1+ (0.025,0) [0|0] "" Vector__XXX
 SG_ VCFRONT_mcuLogicCurrent m11 : 8|10@1+ (0.027,0) [0|0] "" Vector__XXX
 SG_ VCFRONT_railA_12v m15 : 8|12@1+ (0.005443676098,0) [0|0] "" Vector__XXX
 SG_ VCFRONT_rightControllerState m0 : 8|2@1+ (1,0) [0|0] "" Vector__XXX
 SG_ VCFRONT_sleepBypassState m10 : 8|1@1+ (1,0) [0|0] "" Vector__XXX
 SG_ VCFRONT_vbatFusedHighState m13 : 8|1@1+ (1,0) [0|0] "" Vector__XXX
 SG_ VCFRONT_mcuAudioFault m18 : 6|1@1+ (1,0) [0|0] "" Vector__XXX
 SG_ VCFRONT_mcuLogicFault m11 : 6|1@1+ (1,0) [0|0] "" Vector__XXX
 SG_ VCFRONT_pump1AndFanCurrent m14 : 6|16@1+ (0.05,0) [0|0] "" Vector__XXX
 SG_ VCFRONT_mcuAudioState m18 : 5|1@1+ (1,0) [0|0] "" Vector__XXX
 SG_ VCFRONT_mcuLogicState m11 : 5|1@1+ (1,0) [0|0] "" Vector__XXX
 SG_ VCFRONT_pump1AndFanState m14 : 5|1@1+ (1,0) [0|0] "" Vector__XXX
 SG_ VCFRONT_eFuseDebugStatusIndex M : 0|5@1+ (1,0) [0|0] "" Vector__XXX

BO_ 769 VCFRONT_info: 8 Vector__XXX
 SG_ VCFRONT_infoComponentId m10 : 48|16@1+ (1,0) [0|0] "" Vector__XXX
 SG_ VCFRONT_infoSubUsageId m11 : 40|16@1+ (1,0) [0|0] "" Vector__XXX
 SG_ VCFRONT_infoBattPumpAppCRC m32 : 32|32@1+ (1,0) [0|0] "" Vector__XXX
 SG_ VCFRONT_infoFanAppCRC m34 : 32|32@1+ (1,0) [0|0] "" Vector__XXX
 SG_ VCFRONT_infoHardwareId m10 : 32|16@1+ (1,0) [0|0] "" Vector__XXX
 SG_ VCFRONT_infoPtPumpAppCRC m33 : 32|32@1+ (1,0) [0|0] "" Vector__XXX
 SG_ VCFRONT_infoSubcomponent10 m37 : 32|32@1+ (1,0) [0|0] "" Vector__XXX
 SG_ VCFRONT_infoSubcomponent11 m38 : 32|32@1+ (1,0) [0|0] "" Vector__XXX
 SG_ VCFRONT_infoSubcomponent12 m39 : 32|32@1+ (1,0) [0|0] "" Vector__XXX
 SG_ VCFRONT_infoSubcomponent13 m40 : 32|32@1+ (1,0) [0|0] "" Vector__XXX
 SG_ VCFRONT_infoSubcomponent14 m41 : 32|32@1+ (1,0) [0|0] "" Vector__XXX
 SG_ VCFRONT_infoSubcomponent3 m24 : 32|32@1+ (1,0) [0|0] "" Vector__XXX
 SG_ VCFRONT_infoSubcomponent8 m35 : 32|32@1+ (1,0) [0|0] "" Vector__XXX
 SG_ VCFRONT_infoSubcomponent9 m36 : 32|32@1+ (1,0) [0|0] "" Vector__XXX
 SG_ VC_infoHCMLAppCRC m16 : 32|32@1+ (1,0) [0|0] "" Vector__XXX
 SG_ VC_infoHCMRAppCRC m23 : 32|32@1+ (1,0) [0|0] "" Vector__XXX
 SG_ VC_infoWiperAppCRC m31 : 32|32@1+ (1,0) [0|0] "" Vector__XXX
 SG_ VCFRONT_infoBootCrc m20 : 24|32@1+ (1,0) [0|0] "" Vector__XXX
 SG_ VCFRONT_infoUsageId m11 : 24|16@1+ (1,0) [0|0] "" Vector__XXX
 SG_ VCFRONT_infoAssemblyId m11 : 16|8@1+ (1,0) [0|0] "" Vector__XXX
 SG_ VCFRONT_infoBuildConfigId m10 : 16|16@1+ (1,0) [0|0] "" Vector__XXX
 SG_ VCFRONT_infoAppCrc m13 : 8|32@1+ (1,0) [0|0] "" Vector__XXX
 SG_ VCFRONT_infoAppGitHash m17 : 8|56@1+ (1,0) [0|0] "" Vector__XXX
 SG_ VCFRONT_infoBootGitHash m18 : 8|56@1+ (1,0) [0|0] "" Vector__XXX
 SG_ VCFRONT_infoBootUdsProtoVersion m20 : 8|16@1+ (1,0) [0|0] "" Vector__XXX
 SG_ VCFRONT_infoBuildType m10 : 8|3@1+ (1,0) [0|0] "" Vector__XXX
 SG_ VCFRONT_infoPcbaId m11 : 8|8@1+ (1,0) [0|0] "" Vector__XXX
 SG_ VCFRONT_infoPlatformType m19 : 8|8@1+ (1,0) [0|0] "" Vector__XXX
 SG_ VCFRONT_infoIndex M : 0|8@1+ (1,0) [0|0] "" Vector__XXX

BO_ 1009 VCFRONT_lighting_3F1: 8 VEH
 SG_ VCFRONT_DRLLeftStatus: 36|2@1+ (1,0) [0|0] "" X
 SG_ VCFRONT_DRLRightStatus: 38|2@1+ (1,0) [0|0] "" X
 SG_ VCFRONT_ambientLightingBrightnes: 8|8@1+ (0.5,0) [0|0] "%" X
 SG_ VCFRONT_approachLightingRequest: 25|1@1+ (1,0) [0|0] "" X
 SG_ VCFRONT_courtesyLightingRequest: 24|1@1+ (1,0) [0|0] "" X
 SG_ VCFRONT_fogLeftStatus: 40|2@1+ (1,0) [0|0] "" X
 SG_ VCFRONT_fogRightStatus: 42|2@1+ (1,0) [0|0] "" X
 SG_ VCFRONT_hazardLightRequest: 4|3@1+ (1,0) [0|0] "" X
 SG_ VCFRONT_hazardSwitchBacklight: 27|1@1+ (1,0) [0|0] "" X
 SG_ VCFRONT_highBeamLeftStatus: 32|2@1+ (1,0) [0|0] "" X
 SG_ VCFRONT_highBeamRightStatus: 34|2@1+ (1,0) [0|0] "" X
 SG_ VCFRONT_highBeamSwitchActive: 58|1@1+ (1,0) [0|0] "" X
 SG_ VCFRONT_indicatorLeftRequest: 0|2@1+ (1,0) [0|0] "" X
 SG_ VCFRONT_indicatorRightRequest: 2|2@1+ (1,0) [0|0] "" X
 SG_ VCFRONT_lowBeamLeftStatus: 28|2@1+ (1,0) [0|0] "" X
 SG_ VCFRONT_lowBeamRightStatus: 30|2@1+ (1,0) [0|0] "" X
 SG_ VCFRONT_lowBeamsCalibrated: 62|1@1+ (1,0) [0|0] "" X
 SG_ VCFRONT_lowBeamsOnForDRL: 61|1@1+ (1,0) [0|0] "" X
 SG_ VCFRONT_parkLeftStatus: 54|2@1+ (1,0) [0|0] "" X
 SG_ VCFRONT_parkRightStatus: 56|2@1+ (1,0) [0|0] "" X
 SG_ VCFRONT_seeYouHomeLightingReq: 26|1@1+ (1,0) [0|0] "" X
 SG_ VCFRONT_sideMarkersStatus: 44|2@1+ (1,0) [0|0] "" X
 SG_ VCFRONT_sideRepeaterLeftStatus: 46|2@1+ (1,0) [0|0] "" X
 SG_ VCFRONT_sideRepeaterRightStatus: 48|2@1+ (1,0) [0|0] "" X
 SG_ VCFRONT_simLatchingStalk: 59|2@1+ (1,0) [0|0] "" X
 SG_ VCFRONT_switchLightingBrightness: 16|8@1+ (0.5,0) [0|0] "%" X
 SG_ VCFRONT_turnSignalLeftStatus: 50|2@1+ (1,0) [0|0] "" X
 SG_ VCFRONT_turnSignalRightStatus: 52|2@1+ (1,0) [0|0] "" X

BO_ 705 VCFRONT_logging10Hz: 8 Vector__XXX
 SG_ VCFRONT_compLimitHvPowerBudget m1 : 63|1@1+ (1,0) [0|0] "" Vector__XXX
 SG_ VCFRONT_compressorDwellEnabled m2 : 63|1@1+ (1,0) [0|0] "" Vector__XXX
 SG_ VCFRONT_COP1OilWarmingActive m1 : 62|1@1+ (1,0) [0|0] "" Vector__XXX
 SG_ VCFRONT_COP1OilWarmingNeeded m0 : 62|1@1+ (1,0) [0|0] "" Vector__XXX
 SG_ VCFRONT_compressorDelayEnabled m2 : 62|1@1+ (1,0) [0|0] "" Vector__XXX
 SG_ VCFRONT_chargeTrapNominalCOP1Chi m0 : 61|1@1+ (1,0) [0|0] "" Vector__XXX
 SG_ VCFRONT_compLimitTempDischargeSi m1 : 61|1@1+ (1,0) [0|0] "" Vector__XXX
 SG_ VCFRONT_chargeTrapNominalCOP1Bat m0 : 60|1@1+ (1,0) [0|0] "" Vector__XXX
 SG_ VCFRONT_compStandbyMultipleTdCut m1 : 60|1@1+ (1,0) [0|0] "" Vector__XXX
 SG_ VCFRONT_activeLouverStallCounter m2 : 59|3@1+ (1,0) [0|0] "" Vector__XXX
 SG_ VCFRONT_compStandbyMultiplePdCut m1 : 59|1@1+ (1,0) [0|0] "" Vector__XXX
 SG_ VCFRONT_thmlFanSpiError m0 : 59|1@1+ (1,0) [0|0] "" Vector__XXX
 SG_ VCFRONT_activeLouverFalsStallCal m2 : 58|1@1+ (1,0) [0|0] "" Vector__XXX
 SG_ VCFRONT_compStandbyRefrigNotOk m1 : 58|1@1+ (1,0) [0|0] "" Vector__XXX
 SG_ VCFRONT_activeLouverFalsStallRun m2 : 57|1@1+ (1,0) [0|0] "" Vector__XXX
 SG_ VCFRONT_compStandbyLowDischPress m1 : 57|1@1+ (1,0) [0|0] "" Vector__XXX
 SG_ VCFRONT_ccRightExvTorqueCount m4 : 56|8@1+ (1,0) [0|0] "" Vector__XXX
 SG_ VCFRONT_compStandbyLowAmbient m1 : 56|1@1+ (1,0) [0|0] "" Vector__XXX
 SG_ VCFRONT_compStandbyHVNotReady m1 : 55|1@1+ (1,0) [0|0] "" Vector__XXX
 SG_ VCFRONT_compStandbyCommunication m1 : 54|1@1+ (1,0) [0|0] "" Vector__XXX
 SG_ VCFRONT_compStandbySelfNotReady m1 : 53|1@1+ (1,0) [0|0] "" Vector__XXX
 SG_ VCFRONT_compLimitDeadband m1 : 52|1@1+ (1,0) [0|0] "" Vector__XXX
 SG_ VCFRONT_radiatorFanPhaseIMax m0 : 52|7@1+ (0.25,5) [0|0] "" Vector__XXX
 SG_ VCFRONT_compLimitScrollSepRamp m1 : 51|1@1+ (1,0) [0|0] "" Vector__XXX
 SG_ VCFRONT_activeLouverDemand m2 : 50|7@1+ (1,0) [0|0] "" Vector__XXX
 SG_ VCFRONT_compLimitNvh m1 : 50|1@1+ (1,0) [0|0] "" Vector__XXX
 SG_ VCFRONT_wiperHeaterCurrent m3 : 50|9@1+ (0.032,0) [0|0] "" Vector__XXX
 SG_ VCFRONT_COP1PdOscillationPurge m3 : 49|1@1+ (1,0) [0|0] "" Vector__XXX
 SG_ VCFRONT_activeLouverIsCalibrated m2 : 49|1@1+ (1,0) [0|0] "" Vector__XXX
 SG_ VCFRONT_compLimitScrollSepRegion m1 : 49|1@1+ (1,0) [0|0] "" Vector__XXX
 SG_ VCFRONT_COP1PdOscillationDetecte m3 : 48|1@1+ (1,0) [0|0] "" Vector__XXX
 SG_ VCFRONT_activeLouverStallOL m2 : 48|1@1+ (1,0) [0|0] "" Vector__XXX
 SG_ VCFRONT_ccLeftExvTorqueCount m4 : 48|8@1+ (1,0) [0|0] "" Vector__XXX
 SG_ VCFRONT_compLimitTempDischargeHi m1 : 48|1@1+ (1,0) [0|0] "" Vector__XXX
 SG_ VCFRONT_activeLouverCommSuccess m2 : 47|1@1+ (1,0) [0|0] "" Vector__XXX
 SG_ VCFRONT_compLimitPresDischargeHi m1 : 47|1@1+ (1,0) [0|0] "" Vector__XXX
 SG_ VCFRONT_activeLouverMotorState m2 : 44|3@1+ (1,0) [0|0] "" Vector__XXX
 SG_ VCFRONT_radiatorFanPhaseCurrent m0 : 44|8@1+ (0.25,-10) [0|0] "" Vector__XXX
 SG_ VCFRONT_activeLouverStalled m2 : 43|1@1+ (1,0) [0|0] "" Vector__XXX
 SG_ VCFRONT_radiatorFanPowerOn m0 : 43|1@1+ (1,0) [0|0] "" Vector__XXX
 SG_ VCFRONT_activeLouverDisconnect m2 : 42|1@1+ (1,0) [0|0] "" Vector__XXX
 SG_ VCFRONT_coolantValveISense m1 : 42|5@1+ (0.05,0) [0|0] "" Vector__XXX
 SG_ VCFRONT_radiatorFanEnabled m0 : 42|1@1+ (1,0) [0|0] "" Vector__XXX
 SG_ VCFRONT_activeLouverOverTemp m2 : 41|1@1+ (1,0) [0|0] "" Vector__XXX
 SG_ VCFRONT_radiatorFanInitd m0 : 41|1@1+ (1,0) [0|0] "" Vector__XXX
 SG_ VCFRONT_activeLouverOverCurrent m2 : 40|1@1+ (1,0) [0|0] "" Vector__XXX
 SG_ VCFRONT_lccExvTorqueCount m4 : 40|8@1+ (1,0) [0|0] "" Vector__XXX
 SG_ VCFRONT_radarHeaterTargetVoltage m3 : 40|8@1+ (0.1,0) [0|0] "" Vector__XXX
 SG_ VCFRONT_activeLouverAbnormalKT m2 : 39|1@1+ (1,0) [0|0] "" Vector__XXX
 SG_ VCFRONT_coolantValveDuty m1 : 34|8@1- (1,0) [0|0] "" Vector__XXX
 SG_ VCFRONT_radiatorFanOutVoltage m0 : 34|7@1+ (0.2,0) [0|0] "" Vector__XXX
 SG_ VCFRONT_solenoidEvapCurrent m2 : 33|6@1+ (0.04,0) [0|0] "" Vector__XXX
 SG_ VCFRONT_coolantValveState m1 : 32|2@1+ (1,0) [0|0] "" Vector__XXX
 SG_ VCFRONT_radarHeaterDuty m3 : 32|7@1+ (1,0) [0|0] "" Vector__XXX
 SG_ VCFRONT_recircExvTorqueCount m4 : 32|8@1+ (1,0) [0|0] "" Vector__XXX
 SG_ VCFRONT_usingSimulatedAmbTemp m2 : 32|1@1+ (1,0) [0|0] "" Vector__XXX
 SG_ VCFRONT_usingSimulatedDischTemp m2 : 31|1@1+ (1,0) [0|0] "" Vector__XXX
 SG_ VCFRONT_usingSimulatedSuctTemp m2 : 30|1@1+ (1,0) [0|0] "" Vector__XXX
 SG_ VCFRONT_exvPrechillActive m2 : 29|1@1+ (1,0) [0|0] "" Vector__XXX
 SG_ VCFRONT_exvIsFlooding m2 : 28|1@1+ (1,0) [0|0] "" Vector__XXX
 SG_ VCFRONT_coolantFlowChillerActual m0 : 26|8@1+ (0.1,0) [0|0] "" Vector__XXX
 SG_ VCFRONT_pumpPtSpiError m0 : 25|1@1+ (1,0) [0|0] "" Vector__XXX
 SG_ VCFRONT_evapExvTorqueCount m4 : 24|8@1+ (1,0) [0|0] "" Vector__XXX
 SG_ VCFRONT_pumpBatSpiError m0 : 24|1@1+ (1,0) [0|0] "" Vector__XXX
 SG_ VCFRONT_radarHeaterCurrent m3 : 24|8@1+ (0.1,0) [0|0] "" Vector__XXX
 SG_ VCFRONT_pumpsWake m0 : 23|1@1+ (1,0) [0|0] "" Vector__XXX
 SG_ VCFRONT_coolantValveAngleTarget m1 : 22|10@1+ (0.25,-5) [0|0] "" Vector__XXX
 SG_ VCFRONT_pumpPowertrainPowerOn m0 : 22|1@1+ (1,0) [0|0] "" Vector__XXX
 SG_ VCFRONT_pumpBatteryPowerOn m0 : 21|1@1+ (1,0) [0|0] "" Vector__XXX
 SG_ VCFRONT_exvFlow m2 : 20|8@1+ (0.5,0) [0|0] "" Vector__XXX
 SG_ VCFRONT_pumpPowertrainEnabled m0 : 20|1@1+ (1,0) [0|0] "" Vector__XXX
 SG_ VCFRONT_pumpBatteryEnabled m0 : 19|1@1+ (1,0) [0|0] "" Vector__XXX
 SG_ VCFRONT_pumpPowertrainInitd m0 : 18|1@1+ (1,0) [0|0] "" Vector__XXX
 SG_ VCFRONT_pumpBatteryInitd m0 : 17|1@1+ (1,0) [0|0] "" Vector__XXX
 SG_ VCFRONT_activeLouverCalibRange m3 : 16|8@1+ (1,630) [0|0] "" Vector__XXX
 SG_ VCFRONT_chillerExvTorqueCount m4 : 16|8@1+ (1,0) [0|0] "" Vector__XXX
 SG_ VCFRONT_exvMotorState m2 : 16|4@1+ (1,0) [0|0] "" Vector__XXX
 SG_ VCFRONT_refrigerantValvesClosed m2 : 15|1@1+ (1,0) [0|0] "" Vector__XXX
 SG_ VCFRONT_coolantValveAngleActual m1 : 11|11@1+ (0.25,-100) [0|0] "" Vector__XXX
 SG_ VCFRONT_pumpPowertrainOutVoltage m0 : 10|7@1+ (0.2,0) [0|0] "" Vector__XXX
 SG_ VCFRONT_radiatorFanDemandLimited m1 : 10|1@1+ (1,0) [0|0] "" Vector__XXX
 SG_ VCFRONT_ccRightExvTorqueCountAva m4 : 8|1@1+ (1,0) [0|0] "" Vector__XXX
 SG_ VCFRONT_compRampRateUpMax m2 : 8|7@1+ (0.2,0) [0|0] "" Vector__XXX
 SG_ VCFRONT_ccLeftExvTorqueCountAvai m4 : 7|1@1+ (1,0) [0|0] "" Vector__XXX
 SG_ VCFRONT_lccExvTorqueCountAvailab m4 : 6|1@1+ (1,0) [0|0] "" Vector__XXX
 SG_ VCFRONT_recircExvTorqueCountAvai m4 : 5|1@1+ (1,0) [0|0] "" Vector__XXX
 SG_ VCFRONT_evapExvTorqueCountAvaila m4 : 4|1@1+ (1,0) [0|0] "" Vector__XXX
 SG_ VCFRONT_activeLouverMotorCounts m3 : 3|11@1+ (1,-100) [0|0] "" Vector__XXX
 SG_ VCFRONT_chillerExvTorqueCountAva m4 : 3|1@1+ (1,0) [0|0] "" Vector__XXX
 SG_ VCFRONT_pumpBatteryOutVoltage m0 : 3|7@1+ (0.2,0) [0|0] "" Vector__XXX
 SG_ VCFRONT_radiatorFanDemandLimit m1 : 3|7@1+ (1,0) [0|0] "" Vector__XXX
 SG_ VCFRONT_logging10HzIndex M : 0|3@1+ (1,0) [0|0] "" Vector__XXX

BO_ 897 VCFRONT_logging1Hz: 8 Vector__XXX
 SG_ VCFRONT_battAboveMaxCoolantTemp m13 : 63|1@1+ (1,0) [0|0] "" Vector__XXX
 SG_ VCFRONT_cmpIsentropicCheckPassed m17 : 63|1@1+ (1,0) [0|0] "" Vector__XXX
 SG_ VCFRONT_compStandbyOTA m9 : 63|1@1+ (1,0) [0|0] "" Vector__XXX
 SG_ VCFRONT_compStandbyShowroomMode m7 : 63|1@1+ (1,0) [0|0] "" Vector__XXX
 SG_ VCFRONT_hpPotentialFrozenRadiato m14 : 63|1@1+ (1,0) [0|0] "" Vector__XXX
 SG_ VCFRONT_LCCPurgeActive m5 : 62|1@1+ (1,0) [0|0] "" Vector__XXX
 SG_ VCFRONT_ambientTempSpeedSampling m8 : 62|1@1+ (1,0) [0|0] "" Vector__XXX
 SG_ VCFRONT_autopilotAirPurgeRo_0000 m21 : 62|2@1+ (1,0) [0|0] "" Vector__XXX
 SG_ VCFRONT_compStandbyCoastDownMode m7 : 62|1@1+ (1,0) [0|0] "" Vector__XXX
 SG_ VCFRONT_coolantTempBasedMode m1 : 62|2@1+ (1,0) [0|0] "" Vector__XXX
 SG_ VCFRONT_hpRefrigerantPurgeState m6 : 62|2@1+ (1,0) [0|0] "" Vector__XXX
 SG_ VCFRONT_psModelGrosslyOff m13 : 62|1@1+ (1,0) [0|0] "" Vector__XXX
 SG_ VCFRONT_usingModeledTl m2 : 62|1@1+ (1,0) [0|0] "" Vector__XXX
 SG_ VCFRONT_ambientTempRadSampling m8 : 61|1@1+ (1,0) [0|0] "" Vector__XXX
 SG_ VCFRONT_autopilotAirPurgeRoutine m3 : 61|3@1+ (1,0) [0|0] "" Vector__XXX
 SG_ VCFRONT_coolantValveModeWrong m1 : 61|1@1+ (1,0) [0|0] "" Vector__XXX
 SG_ VCFRONT_cycleModelConverged m7 : 61|1@1+ (1,0) [0|0] "" Vector__XXX
 SG_ VCFRONT_hpPotentialLowRefrig m6 : 61|1@1+ (1,0) [0|0] "" Vector__XXX
 SG_ VCFRONT_hpRefrigPressureSensorCh m18 : 61|1@1+ (1,0) [0|0] "" Vector__XXX
 SG_ VCFRONT_isExpectedQChillerVeryHi m21 : 61|1@1+ (1,0) [0|0] "" Vector__XXX
 SG_ VCFRONT_pdModelGrosslyOff m13 : 61|1@1+ (1,0) [0|0] "" Vector__XXX
 SG_ VCFRONT_targetPTActiveCoolSource m16 : 61|3@1+ (1,0) [0|0] "" Vector__XXX
 SG_ VCFRONT_usingModeledTd m2 : 61|1@1+ (1,0) [0|0] "" Vector__XXX
 SG_ VCFRONT_vcleftFastBlowCounter0 m23 : 61|3@1+ (1,0) [0|0] "" Vector__XXX
 SG_ VCFRONT_vcrightFastBlowCounter0 m24 : 61|3@1+ (1,0) [0|0] "" Vector__XXX
 SG_ VCFRONT_ambientTempPassiveSniffi m8 : 60|1@1+ (1,0) [0|0] "" Vector__XXX
 SG_ VCFRONT_chillerBattHeatingPowerA m21 : 60|1@1+ (1,0) [0|0] "" Vector__XXX
 SG_ VCFRONT_dtcConfirmed m3 : 60|1@1+ (1,0) [0|0] "" Vector__XXX
 SG_ VCFRONT_hpRefrigTempSensorCheckC m18 : 60|1@1+ (1,0) [0|0] "" Vector__XXX
 SG_ VCFRONT_modelLoadCoolingDominant m6 : 60|1@1+ (1,0) [0|0] "" Vector__XXX
 SG_ VCFRONT_refCommissionStatus m5 : 60|2@1+ (1,0) [0|0] "" Vector__XXX
 SG_ VCFRONT_usingModeledTs m2 : 60|1@1+ (1,0) [0|0] "" Vector__XXX
 SG_ VCFRONT_ambientTempSniffActive m8 : 59|1@1+ (1,0) [0|0] "" Vector__XXX
 SG_ VCFRONT_feedfwdLoadCoolingDomina m6 : 59|1@1+ (1,0) [0|0] "" Vector__XXX
 SG_ VCFRONT_preventReEntryTillNexthp m21 : 59|1@1+ (1,0) [0|0] "" Vector__XXX
 SG_ VCFRONT_refrigerantHasBeenFilled m5 : 59|1@1+ (1,0) [0|0] "" Vector__XXX
 SG_ VCFRONT_usingModeledPl m2 : 59|1@1+ (1,0) [0|0] "" Vector__XXX
 SG_ VCFRONT_ccRightExvCalibFailed m8 : 58|1@1+ (1,0) [0|0] "" Vector__XXX
 SG_ VCFRONT_chargeShuttleType m18 : 58|2@1+ (1,0) [0|0] "" Vector__XXX
 SG_ VCFRONT_targetBatActiveCoolSourc m16 : 58|3@1+ (1,0) [0|0] "" Vector__XXX
 SG_ VCFRONT_totalLoadCoolingDominant m6 : 58|1@1+ (1,0) [0|0] "" Vector__XXX
 SG_ VCFRONT_usingModeledPd m2 : 58|1@1+ (1,0) [0|0] "" Vector__XXX
 SG_ VCFRONT_vcleftFastBlowCounter m23 : 58|3@1+ (1,0) [0|0] "" Vector__XXX
 SG_ VCFRONT_vcrightFastBlowCounter m24 : 58|3@1+ (1,0) [0|0] "" Vector__XXX
 SG_ VCFRONT_ccLeftExvCalibFailed m8 : 57|1@1+ (1,0) [0|0] "" Vector__XXX
 SG_ VCFRONT_lowerGlassHeaterCurrent m20 : 57|7@1+ (0.2,0) [0|0] "" Vector__XXX
 SG_ VCFRONT_pressureRefrigLiquidEst m17 : 57|6@1+ (0.5,0) [0|0] "" Vector__XXX
 SG_ VCFRONT_radiatorFanRunReason m1 : 57|4@1+ (1,0) [0|0] "" Vector__XXX
 SG_ VCFRONT_suctionSuperheatEstPsSNA m13 : 57|4@1+ (2,0) [0|0] "" Vector__XXX
 SG_ VCFRONT_usingModeledPs m2 : 57|1@1+ (1,0) [0|0] "" Vector__XXX
 SG_ VCFRONT_batteryDischArbState m21 : 56|3@1+ (1,0) [0|0] "" Vector__XXX
 SG_ VCFRONT_chillerCOP1CoolantFlowRa m10 : 56|8@1+ (0.00196078431372549,0) [0|0] "" Vector__XXX
 SG_ VCFRONT_chillerCOP1CoolantInlet m22 : 56|7@1- (1.2698412698412698,0) [0|0] "" Vector__XXX
 SG_ VCFRONT_fanControlRadiatorInletT m12 : 56|6@1- (1.8,36) [0|0] "" Vector__XXX
 SG_ VCFRONT_hpCompPowerIndexFiltered m9 : 56|7@1+ (1,0) [0|0] "" Vector__XXX
 SG_ VCFRONT_hvCompCurrent m19 : 56|8@1+ (0.1,0) [0|0] "" Vector__XXX
 SG_ VCFRONT_lccExvCalibFailed m8 : 56|1@1+ (1,0) [0|0] "" Vector__XXX
 SG_ VCFRONT_maxCompressorRPMAllowed m11 : 56|7@1+ (90,0) [0|0] "" Vector__XXX
 SG_ VCFRONT_passiveCoolingState m6 : 56|2@1+ (1,0) [0|0] "" Vector__XXX
 SG_ VCFRONT_tempCoolantRadOutletEst m4 : 56|7@1- (1,23) [0|0] "" Vector__XXX
 SG_ VCFRONT_tempCoolantRadOutletEstS m16 : 56|2@1+ (1,0) [0|0] "" Vector__XXX
 SG_ VCFRONT_totalBattHeatingPower m14 : 56|7@1+ (150,0) [0|0] "" Vector__XXX
 SG_ VCFRONT_estQLift m7 : 55|6@1+ (100,0) [0|0] "" Vector__XXX
 SG_ VCFRONT_recircExvCalibFailed m8 : 55|1@1+ (1,0) [0|0] "" Vector__XXX
 SG_ VCFRONT_targetBatActiveHeat m0 : 55|7@1+ (1,-40) [0|0] "" Vector__XXX
 SG_ VCFRONT_evapExvCalibFailed m8 : 54|1@1+ (1,0) [0|0] "" Vector__XXX
 SG_ VCFRONT_chillerExvCalibFailed m8 : 53|1@1+ (1,0) [0|0] "" Vector__XXX
 SG_ VCFRONT_vcleftDynamicBucketFill3 m23 : 53|5@1+ (40,0) [0|0] "" Vector__XXX
 SG_ VCFRONT_vcrightDynamicBucke_0003 m24 : 53|5@1+ (40,0) [0|0] "" Vector__XXX
 SG_ VCFRONT_estimatedChillerLoadCOP1 m3 : 52|8@1+ (39.21568627450981,0) [0|0] "" Vector__XXX
 SG_ VCFRONT_pressureRefrigSuctionEst m13 : 51|6@1+ (0.16,0) [0|0] "" Vector__XXX
 SG_ VCFRONT_tempRefrigLiquidEst m17 : 51|6@1+ (2,0) [0|0] "" Vector__XXX
 SG_ VCFRONT_ccrEXVControlState m8 : 50|3@1+ (1,0) [0|0] "" Vector__XXX
 SG_ VCFRONT_coolantValveRadBypass m2 : 50|7@1+ (1,0) [0|0] "" Vector__XXX
 SG_ VCFRONT_hpAtSteadyState m13 : 50|1@1+ (1,0) [0|0] "" Vector__XXX
 SG_ VCFRONT_shutOffValve1Current m19 : 50|6@1+ (0.2,0) [0|0] "" Vector__XXX
 SG_ VCFRONT_evapFdFrwrdTargetMinimum m6 : 49|7@1+ (80,0) [0|0] "" Vector__XXX
 SG_ VCFRONT_fanControlRadiatorUa m12 : 49|7@1+ (8,0) [0|0] "" Vector__XXX
 SG_ VCFRONT_hpBattHeatingPower m16 : 49|7@1+ (100,0) [0|0] "" Vector__XXX
 SG_ VCFRONT_radOptionalRejectEstimat m10 : 49|7@1+ (150,0) [0|0] "" Vector__XXX
 SG_ VCFRONT_radiatorFanFETTemp m1 : 49|8@1+ (1,-40) [0|0] "" Vector__XXX
 SG_ VCFRONT_tempSuperheatTarget m5 : 49|10@1+ (0.1,0) [0|0] "" Vector__XXX
 SG_ VCFRONT_cabinHeatingCOP1MinActiv m25 : 48|7@1+ (10,0) [0|0] "" Vector__XXX
 SG_ VCFRONT_ccRightExvRange m4 : 48|8@1+ (7,0) [0|0] "" Vector__XXX
 SG_ VCFRONT_coolantValveAngleTravel m18 : 48|10@1+ (5,0) [0|0] "" Vector__XXX
 SG_ VCFRONT_fanControlFeedfwdActive m12 : 48|1@1+ (1,0) [0|0] "" Vector__XXX
 SG_ VCFRONT_hpCompPowerIndexCorrecte m22 : 48|7@1+ (1,0) [0|0] "" Vector__XXX
 SG_ VCFRONT_minAllowedChillerPowerIn m9 : 48|8@1+ (40,0) [0|0] "" Vector__XXX
 SG_ VCFRONT_minAllowedSuctionPressur m11 : 48|7@1+ (0.02,0) [0|0] "" Vector__XXX
 SG_ VCFRONT_radiatorFanRPMTarget m21 : 48|8@1+ (40,0) [0|0] "" Vector__XXX
 SG_ VCFRONT_targetBatPassive m0 : 48|7@1+ (1,-20) [0|0] "" Vector__XXX
 SG_ VCFRONT_upperGlassHeaterCurrent m20 : 48|9@1+ (0.05,0) [0|0] "" Vector__XXX
 SG_ VCFRONT_vcleftDynamicBucketFill2 m23 : 48|5@1+ (40,0) [0|0] "" Vector__XXX
 SG_ VCFRONT_vcrightDynamicBucke_0002 m24 : 48|5@1+ (40,0) [0|0] "" Vector__XXX
 SG_ VCFRONT_wiperCycles m15 : 48|16@1+ (100,0) [0|0] "" Vector__XXX
 SG_ VCFRONT_abnormalHighSuctionSuper m18 : 47|1@1+ (1,0) [0|0] "" Vector__XXX
 SG_ VCFRONT_cclEXVControlState m8 : 47|3@1+ (1,0) [0|0] "" Vector__XXX
 SG_ VCFRONT_fanControlRadCanCool m12 : 47|1@1+ (1,0) [0|0] "" Vector__XXX
 SG_ VCFRONT_estCompressorRpm m7 : 46|9@1+ (30,0) [0|0] "" Vector__XXX
 SG_ VCFRONT_radBypassMoveReason m16 : 45|4@1+ (1,0) [0|0] "" Vector__XXX
 SG_ VCFRONT_radarCurrent m19 : 45|5@1+ (0.5,0) [0|0] "" Vector__XXX
 SG_ VCFRONT_subcoolEstPlSNA m17 : 45|6@1- (2,0) [0|0] "" Vector__XXX
 SG_ VCFRONT_tempRefrigLiquid m14 : 45|11@1+ (0.125,-40) [0|0] "" Vector__XXX
 SG_ VCFRONT_coolantValveWindupEst m2 : 44|6@1+ (2,0) [0|0] "" Vector__XXX
 SG_ VCFRONT_lccEXVControlState m8 : 44|3@1+ (1,0) [0|0] "" Vector__XXX
 SG_ VCFRONT_radMovementBlockActive m16 : 44|1@1+ (1,0) [0|0] "" Vector__XXX
 SG_ VCFRONT_coolantLevelVoltage m3 : 43|9@1+ (0.01,0) [0|0] "" Vector__XXX
 SG_ VCFRONT_hpCompPowerIndex m13 : 43|7@1+ (1,0) [0|0] "" Vector__XXX
 SG_ VCFRONT_vcleftDynamicBucketFill1 m23 : 43|5@1+ (40,0) [0|0] "" Vector__XXX
 SG_ VCFRONT_vcrightDynamicBucke_0001 m24 : 43|5@1+ (40,0) [0|0] "" Vector__XXX
 SG_ VCFRONT_DIQdotA m6 : 42|7@1+ (80,0) [0|0] "" Vector__XXX
 SG_ VCFRONT_radActiveRejectEstimate m10 : 42|7@1+ (150,0) [0|0] "" Vector__XXX
 SG_ VCFRONT_windshldFluidPumpCurrent m20 : 42|6@1+ (0.5,0) [0|0] "" Vector__XXX
 SG_ VCFRONT_chillerCOP1ResidualLoad m15 : 41|7@1+ (78.74015748031496,0) [0|0] "" Vector__XXX
 SG_ VCFRONT_pumpPowertrainFETTemp m1 : 41|8@1+ (1,-40) [0|0] "" Vector__XXX
 SG_ VCFRONT_recircEXVControlState m8 : 41|3@1+ (1,0) [0|0] "" Vector__XXX
 SG_ VCFRONT_targetBatOptionalActiveC m0 : 41|7@1+ (1,0) [0|0] "" Vector__XXX
 SG_ VCFRONT_PSuctionControllerOutput m11 : 40|8@1+ (0.5,0) [0|0] "" Vector__XXX
 SG_ VCFRONT_ccLeftExvRange m4 : 40|8@1+ (7,0) [0|0] "" Vector__XXX
 SG_ VCFRONT_compressorSuctionVaporQu m25 : 40|5@1+ (0.01,0.7) [0|0] "" Vector__XXX
 SG_ VCFRONT_coolantFlowChillerTarget m21 : 40|8@1+ (0.161,0) [0|0] "" Vector__XXX
 SG_ VCFRONT_fanCurrentIndex m22 : 40|7@1+ (1,0) [0|0] "" Vector__XXX
 SG_ VCFRONT_highSideDpResidual m18 : 40|7@1- (0.1,0) [0|0] "" Vector__XXX
 SG_ VCFRONT_homelinkCurrent m19 : 40|5@1+ (0.01,0) [0|0] "" Vector__XXX
 SG_ VCFRONT_maxAllowedEvapPowerInSer m9 : 40|8@1+ (40,0) [0|0] "" Vector__XXX
 SG_ VCFRONT_chillerLiftDisabledLowPs m11 : 39|1@1+ (1,0) [0|0] "" Vector__XXX
 SG_ VCFRONT_estTempDisch m7 : 39|7@1- (1.5,75) [0|0] "" Vector__XXX
 SG_ VCFRONT_maxChillerCoolingPower m12 : 39|8@1+ (100,0) [0|0] "" Vector__XXX
 SG_ VCFRONT_subcoolEstTlSNA m17 : 39|6@1- (2,0) [0|0] "" Vector__XXX
 SG_ VCFRONT_tempSuperheatActual m5 : 39|10@1+ (0.1,-20) [0|0] "" Vector__XXX
 SG_ VCFRONT_ambientSourcingDisabled m11 : 38|1@1+ (1,0) [0|0] "" Vector__XXX
 SG_ VCFRONT_estPressureDischargeSat m14 : 38|7@1+ (0.25,0) [0|0] "" Vector__XXX
 SG_ VCFRONT_evapEXVControlState m8 : 38|3@1+ (1,0) [0|0] "" Vector__XXX
 SG_ VCFRONT_isSolenoidAllowed m12 : 38|1@1+ (1,0) [0|0] "" Vector__XXX
 SG_ VCFRONT_vcleftDynamicBucketFill0 m23 : 38|5@1+ (40,0) [0|0] "" Vector__XXX
 SG_ VCFRONT_vcrightDynamicBucke_0000 m24 : 38|5@1+ (40,0) [0|0] "" Vector__XXX
 SG_ VCFRONT_coolantPurgeMinutesRun m3 : 37|6@1+ (1,0) [0|0] "" Vector__XXX
 SG_ VCFRONT_dischargePressureLimit m16 : 37|7@1+ (0.25,0) [0|0] "" Vector__XXX
 SG_ VCFRONT_hpForceModeRadClear m14 : 37|1@1+ (1,0) [0|0] "" Vector__XXX
 SG_ VCFRONT_frunkLEDCurrent m19 : 36|4@1+ (0.01,0) [0|0] "" Vector__XXX
 SG_ VCFRONT_hpDiagHighSideNotNominal m14 : 36|1@1+ (1,0) [0|0] "" Vector__XXX
 SG_ VCFRONT_windshieldWiperCurrent m20 : 36|6@1+ (1,0) [0|0] "" Vector__XXX
 SG_ VCFRONT_chillerEXVControlState m8 : 35|3@1+ (1,0) [0|0] "" Vector__XXX
 SG_ VCFRONT_evapFdbk m6 : 35|7@1- (100,-3300) [0|0] "" Vector__XXX
 SG_ VCFRONT_feedFwdPumpDemand m10 : 35|7@1+ (1,0) [0|0] "" Vector__XXX
 SG_ VCFRONT_hcmrSelectedBinningMetho m3 : 35|2@1+ (1,0) [0|0] "" Vector__XXX
 SG_ VCFRONT_hpDiagLouverCalib m14 : 35|1@1+ (1,0) [0|0] "" Vector__XXX
 SG_ VCFRONT_ambientTempUnlatchReason m25 : 34|3@1+ (1,0) [0|0] "" Vector__XXX
 SG_ VCFRONT_ccRefrigerantMassFlow m18 : 34|6@1+ (4,0) [0|0] "" Vector__XXX
 SG_ VCFRONT_estCompPower m13 : 34|9@1+ (20,0) [0|0] "" Vector__XXX
 SG_ VCFRONT_hpBattOverTempHvacDisabl m14 : 34|1@1+ (1,0) [0|0] "" Vector__XXX
 SG_ VCFRONT_mdotAirRadiator m15 : 34|7@1+ (0.031496062992125984,0) [0|0] "" Vector__XXX
 SG_ VCFRONT_targetBatActiveCool m0 : 34|7@1+ (1,0) [0|0] "" Vector__XXX
 SG_ VCFRONT_estTempSuct m7 : 33|6@1- (1,2) [0|0] "" Vector__XXX
 SG_ VCFRONT_hcmlSelectedBinningMetho m3 : 33|2@1+ (1,0) [0|0] "" Vector__XXX
 SG_ VCFRONT_pumpBatteryFETTemp m1 : 33|8@1+ (1,-40) [0|0] "" Vector__XXX
 SG_ VCFRONT_vcleftDynamicBucketFill m23 : 33|5@1+ (40,0) [0|0] "" Vector__XXX
 SG_ VCFRONT_vcrightDynamicBucketFill m24 : 33|5@1+ (40,0) [0|0] "" Vector__XXX
 SG_ VCFRONT_ambientTempState m25 : 32|2@1+ (1,0) [0|0] "" Vector__XXX
 SG_ VCFRONT_lccExvRange m4 : 32|8@1+ (7,0) [0|0] "" Vector__XXX
 SG_ VCFRONT_lccPassiveHeatPower m9 : 32|8@1+ (60,0) [0|0] "" Vector__XXX
 SG_ VCFRONT_lowSideWattsLift m5 : 32|7@1+ (60,0) [0|0] "" Vector__XXX
 SG_ VCFRONT_pumpPowertrainRPMTarget m21 : 32|8@1+ (30,0) [0|0] "" Vector__XXX
 SG_ VCFRONT_suctionPressureTarget m11 : 32|6@1+ (0.15,0) [0|0] "" Vector__XXX
 SG_ VCFRONT_battCoolEvapEnableDelay m25 : 31|1@1+ (1,0) [0|0] "" Vector__XXX
 SG_ VCFRONT_hpCompFlowIndexFiltered m17 : 31|8@1+ (1,30) [0|0] "" Vector__XXX
 SG_ VCFRONT_ccRightExvCalibOffset m8 : 30|5@1- (8,0) [0|0] "" Vector__XXX
 SG_ VCFRONT_coolantValveCurrent m20 : 30|6@1+ (0.5,0) [0|0] "" Vector__XXX
 SG_ VCFRONT_coolantValveDailyAngleTr m16 : 30|7@1+ (60,0) [0|0] "" Vector__XXX
 SG_ VCFRONT_feedBackDuctTempControll m12 : 30|8@1+ (0.01,-1) [0|0] "" Vector__XXX
 SG_ VCFRONT_radiatorSteamDetectionSt m3 : 30|3@1+ (1,0) [0|0] "" Vector__XXX
 SG_ VCFRONT_coolantValveRecalCount m2 : 28|16@1+ (1,0) [0|0] "" Vector__XXX
 SG_ VCFRONT_evapFdFrwrdTarget m6 : 28|7@1+ (80,0) [0|0] "" Vector__XXX
 SG_ VCFRONT_feedFwdFanDemand m10 : 28|7@1+ (1,0) [0|0] "" Vector__XXX
 SG_ VCFRONT_rightSideRepeaterCurrent m19 : 28|8@1+ (0.062,0) [0|0] "" Vector__XXX
 SG_ VCFRONT_tempRefrigDischargeEst m13 : 28|6@1+ (1.5,46) [0|0] "" Vector__XXX
 SG_ VCFRONT_tempRefrigSuctionEst m14 : 28|6@1- (1.2,7.2) [0|0] "" Vector__XXX
 SG_ VCFRONT_vcleftStaticBucketFill3 m23 : 28|5@1+ (40,0) [0|0] "" Vector__XXX
 SG_ VCFRONT_vcrightStaticBucketFill3 m24 : 28|5@1+ (40,0) [0|0] "" Vector__XXX
 SG_ VCFRONT_minCompressorRPMAllowed m18 : 27|7@1+ (90,0) [0|0] "" Vector__XXX
 SG_ VCFRONT_targetPTPassive m0 : 27|7@1+ (1,-20) [0|0] "" Vector__XXX
 SG_ VCFRONT_correctedLowSideTemperat m15 : 26|8@1- (0.7874015748031497,10.236220472440946) [0|0] "" Vector__XXX
 SG_ VCFRONT_ductRightAtSS m18 : 26|1@1+ (1,0) [0|0] "" Vector__XXX
 SG_ VCFRONT_hpCOP m5 : 26|6@1+ (0.1,0) [0|0] "" Vector__XXX
 SG_ VCFRONT_ccLeftExvCalibOffset m8 : 25|5@1- (8,0) [0|0] "" Vector__XXX
 SG_ VCFRONT_ductLeftAtSS m18 : 25|1@1+ (1,0) [0|0] "" Vector__XXX
 SG_ VCFRONT_estTempLiq m7 : 25|8@1- (0.8,68.8) [0|0] "" Vector__XXX
 SG_ VCFRONT_frunkSensorWindowActive m15 : 25|1@1+ (1,0) [0|0] "" Vector__XXX
 SG_ VCFRONT_tempRefrigSuction m1 : 25|8@1+ (0.5,-40) [0|0] "" Vector__XXX
 SG_ VCFRONT_PDischargeControllerOutp m11 : 24|8@1+ (0.5,0) [0|0] "" Vector__XXX
 SG_ VCFRONT_chillerPassiveCoolPower m9 : 24|8@1- (60,7560) [0|0] "" Vector__XXX
 SG_ VCFRONT_nominalTevapHWLimit m25 : 24|7@1+ (0.5,0) [0|0] "" Vector__XXX
 SG_ VCFRONT_pumpBatteryRPMTarget m21 : 24|8@1+ (30,0) [0|0] "" Vector__XXX
 SG_ VCFRONT_radiatorUAIndex m26 : 24|8@1+ (1,0) [0|0] "" Vector__XXX
 SG_ VCFRONT_recircExvRange m4 : 24|8@1+ (7,0) [0|0] "" Vector__XXX
 SG_ VCFRONT_suctionSuperheatEstTsSNA m14 : 24|4@1+ (2,0) [0|0] "" Vector__XXX
 SG_ VCFRONT_feedBackEvapTempControll m12 : 23|7@1+ (0.01,-0.5) [0|0] "" Vector__XXX
 SG_ VCFRONT_hpBatteryCoolEvaporator m14 : 23|1@1+ (1,0) [0|0] "" Vector__XXX
 SG_ VCFRONT_hpCompFlowIndex m17 : 23|8@1+ (1,30) [0|0] "" Vector__XXX
 SG_ VCFRONT_pressureRefrigDischEst m13 : 23|5@1+ (1,0) [0|0] "" Vector__XXX
 SG_ VCFRONT_targetLccActiveCoolEff m16 : 23|7@1+ (1,0) [0|0] "" Vector__XXX
 SG_ VCFRONT_vcleftStaticBucketFill2 m23 : 23|5@1+ (40,0) [0|0] "" Vector__XXX
 SG_ VCFRONT_vcrightStaticBucketFill2 m24 : 23|5@1+ (40,0) [0|0] "" Vector__XXX
 SG_ VCFRONT_hpBatteryCoolCabinReheat m14 : 22|1@1+ (1,0) [0|0] "" Vector__XXX
 SG_ VCFRONT_radInletTempEstimate m3 : 22|8@1- (1,0) [0|0] "" Vector__XXX
 SG_ VCFRONT_CCQdotActual m6 : 21|7@1+ (80,0) [0|0] "" Vector__XXX
 SG_ VCFRONT_CMPDischargeSuperheat m5 : 21|5@1- (1,6) [0|0] "" Vector__XXX
 SG_ VCFRONT_frontOilPumpCurrent m20 : 21|9@1+ (0.047,0) [0|0] "" Vector__XXX
 SG_ VCFRONT_hpBatteryCoolCabinC_0000 m14 : 21|1@1+ (1,0) [0|0] "" Vector__XXX
 SG_ VCFRONT_chillerInletTempEstimate m10 : 20|8@1- (1,0) [0|0] "" Vector__XXX
 SG_ VCFRONT_hpBatteryCoolCabinConden m14 : 20|1@1+ (1,0) [0|0] "" Vector__XXX
 SG_ VCFRONT_lccExvCalibOffset m8 : 20|5@1- (8,0) [0|0] "" Vector__XXX
 SG_ VCFRONT_leftSideRepeaterCurrent m19 : 20|8@1+ (0.062,0) [0|0] "" Vector__XXX
 SG_ VCFRONT_targetPtOptionalActiveCo m0 : 20|7@1+ (1,0) [0|0] "" Vector__XXX
 SG_ VCFRONT_hpBatteryCool m14 : 19|1@1+ (1,0) [0|0] "" Vector__XXX
 SG_ VCFRONT_coolantValveAngleDrift m2 : 18|10@1+ (0.25,-127) [0|0] "" Vector__XXX
 SG_ VCFRONT_estPressureDisch m7 : 18|7@1+ (0.25,0) [0|0] "" Vector__XXX
 SG_ VCFRONT_fanDemandRadiator m1 : 18|7@1+ (1,0) [0|0] "" Vector__XXX
 SG_ VCFRONT_hpBatteryHeatCOP1 m14 : 18|1@1+ (1,0) [0|0] "" Vector__XXX
 SG_ VCFRONT_vcleftStaticBucketFill1 m23 : 18|5@1+ (40,0) [0|0] "" Vector__XXX
 SG_ VCFRONT_vcrightStaticBucketFill1 m24 : 18|5@1+ (40,0) [0|0] "" Vector__XXX
 SG_ VCFRONT_estCompRefrigMassflow m13 : 17|6@1+ (4,0) [0|0] "" Vector__XXX
 SG_ VCFRONT_hpBatteryHeatAmbientSour m14 : 17|1@1+ (1,0) [0|0] "" Vector__XXX
 SG_ VCFRONT_hpEnergyFlowIndexFiltere m18 : 17|8@1+ (4,0) [0|0] "" Vector__XXX
 SG_ VCFRONT_chillerDemandWatts m25 : 16|8@1+ (100,0) [0|0] "" Vector__XXX
 SG_ VCFRONT_diDissipation m9 : 16|8@1+ (80,0) [0|0] "" Vector__XXX
 SG_ VCFRONT_difDischargeCurrent m20 : 16|5@1+ (0.05,0) [0|0] "" Vector__XXX
 SG_ VCFRONT_evapExvRange m4 : 16|8@1+ (7,0) [0|0] "" Vector__XXX
 SG_ VCFRONT_hpCabinCoolEvaporatorReh m14 : 16|1@1+ (1,0) [0|0] "" Vector__XXX
 SG_ VCFRONT_hpDuctTargetRight m26 : 16|7@1+ (1,0) [0|0] "" Vector__XXX
 SG_ VCFRONT_hpHotStagnationLimit m17 : 16|7@1+ (1,-40) [0|0] "" Vector__XXX
 SG_ VCFRONT_hpSubcoolTarget m5 : 16|5@1+ (1,0) [0|0] "" Vector__XXX
 SG_ VCFRONT_minFlowPDCont m11 : 16|8@1+ (0.5,0) [0|0] "" Vector__XXX
 SG_ VCFRONT_ptLoopWorthCooling m13 : 16|1@1+ (1,0) [0|0] "" Vector__XXX
 SG_ VCFRONT_targetLccActiveCoolCap m16 : 16|7@1+ (1,0) [0|0] "" Vector__XXX
 SG_ VCFRONT_battLoopWorthCooling m13 : 15|1@1+ (1,0) [0|0] "" Vector__XXX
 SG_ VCFRONT_evapDisabledLowPsCutout m11 : 15|1@1+ (1,0) [0|0] "" Vector__XXX
 SG_ VCFRONT_feedFwdMDotCabinCondense m12 : 15|8@1+ (0.005,0) [0|0] "" Vector__XXX
 SG_ VCFRONT_frunkSwitch2Voltage m15 : 15|10@1+ (5,0) [0|0] "" Vector__XXX
 SG_ VCFRONT_hpCabinCoolEvaporator m14 : 15|1@1+ (1,0) [0|0] "" Vector__XXX
 SG_ VCFRONT_recircExvCalibOffset m8 : 15|5@1- (8,0) [0|0] "" Vector__XXX
 SG_ VCFRONT_sideMarkersCurrent m19 : 15|5@1+ (0.2,0) [0|0] "" Vector__XXX
 SG_ VCFRONT_CCQdotFdbk m6 : 14|7@1- (80,0) [0|0] "" Vector__XXX
 SG_ VCFRONT_hpCabinHeatBatteryCoolRe m14 : 14|1@1+ (1,0) [0|0] "" Vector__XXX
 SG_ VCFRONT_hpCabinHeatBatteryHeatCO m12 : 14|1@1+ (1,0) [0|0] "" Vector__XXX
 SG_ VCFRONT_hpCabinHeatBatteryHeatAm m12 : 13|1@1+ (1,0) [0|0] "" Vector__XXX
 SG_ VCFRONT_hpCabinHeatBatteryHeatRe m14 : 13|1@1+ (1,0) [0|0] "" Vector__XXX
 SG_ VCFRONT_targetPTActiveCool m0 : 13|7@1+ (1,0) [0|0] "" Vector__XXX
 SG_ VCFRONT_tempRefrigDischarge m21 : 13|11@1+ (0.125,-40) [0|0] "" Vector__XXX
 SG_ VCFRONT_vcleftStaticBucketFill0 m23 : 13|5@1+ (40,0) [0|0] "" Vector__XXX
 SG_ VCFRONT_vcrightStaticBucketFill0 m24 : 13|5@1+ (40,0) [0|0] "" Vector__XXX
 SG_ VCFRONT_hpCabinHeatCOP1 m14 : 12|1@1+ (1,0) [0|0] "" Vector__XXX
 SG_ VCFRONT_lccInletTempEstimate m10 : 12|8@1- (1,0) [0|0] "" Vector__XXX
 SG_ VCFRONT_estPressureSuct m7 : 11|7@1+ (0.125,0) [0|0] "" Vector__XXX
 SG_ VCFRONT_fanDemandCondenser m1 : 11|7@1+ (1,0) [0|0] "" Vector__XXX
 SG_ VCFRONT_hpCabinHeatBlend m14 : 11|1@1+ (1,0) [0|0] "" Vector__XXX
 SG_ VCFRONT_modeDesired m0 : 11|2@1+ (1,0) [0|0] "" Vector__XXX
 SG_ VCFRONT_evapExvCalibOffset m8 : 10|5@1- (8,0) [0|0] "" Vector__XXX
 SG_ VCFRONT_hpCabinHeatReheatAmbient m14 : 10|1@1+ (1,0) [0|0] "" Vector__XXX
 SG_ VCFRONT_hpMode m13 : 10|5@1+ (1,0) [0|0] "" Vector__XXX
 SG_ VCFRONT_rightFogLightCurrent m19 : 10|5@1+ (0.2,0) [0|0] "" Vector__XXX
 SG_ VCFRONT_PCSCurrentFiltered m3 : 9|13@1- (0.1,0) [0|0] "" Vector__XXX
 SG_ VCFRONT_ambientSourcingAvailable m13 : 9|1@1+ (1,0) [0|0] "" Vector__XXX
 SG_ VCFRONT_difCurrent m20 : 9|7@1+ (0.05,0) [0|0] "" Vector__XXX
 SG_ VCFRONT_hpCabinHeatReheatScaveng m14 : 9|1@1+ (1,0) [0|0] "" Vector__XXX
 SG_ VCFRONT_hpEnergyFlowIndex m18 : 9|8@1+ (4,0) [0|0] "" Vector__XXX
 SG_ VCFRONT_ambientColderThanBatt m13 : 8|1@1+ (1,0) [0|0] "" Vector__XXX
 SG_ VCFRONT_battDissipation m9 : 8|8@1+ (140,0) [0|0] "" Vector__XXX
 SG_ VCFRONT_chillerExvRange m4 : 8|8@1+ (7,0) [0|0] "" Vector__XXX
 SG_ VCFRONT_coolantValveCountRange m2 : 8|10@1+ (1,375) [0|0] "" Vector__XXX
 SG_ VCFRONT_debugWakeUp m22 : 8|32@1+ (1,0) [0|0] "" Vector__XXX
 SG_ VCFRONT_dischargePressureTarget m11 : 8|7@1+ (0.25,0) [0|0] "" Vector__XXX
 SG_ VCFRONT_hpCabinHeatAmbientSource m14 : 8|1@1+ (1,0) [0|0] "" Vector__XXX
 SG_ VCFRONT_hpColdStagnationLimit m17 : 8|7@1+ (1,-40) [0|0] "" Vector__XXX
 SG_ VCFRONT_hpDuctTargetLeft m26 : 8|7@1+ (1,0) [0|0] "" Vector__XXX
 SG_ VCFRONT_passiveDemandRadBypass m16 : 8|7@1+ (1,0) [0|0] "" Vector__XXX
 SG_ VCFRONT_subcoolActual m5 : 8|7@1- (0.4,15.2) [0|0] "" Vector__XXX
 SG_ VCFRONT_vcleftStaticBucketFill m23 : 8|5@1+ (40,0) [0|0] "" Vector__XXX
 SG_ VCFRONT_vcrightStaticBucketFill m24 : 8|5@1+ (40,0) [0|0] "" Vector__XXX
 SG_ VCFRONT_CCQdotFdFrwrdTarget m6 : 7|7@1+ (80,0) [0|0] "" Vector__XXX
 SG_ VCFRONT_battUnderStagUpperLimit m13 : 7|1@1+ (1,0) [0|0] "" Vector__XXX
 SG_ VCFRONT_hpCabinHeatScavengeOnly m14 : 7|1@1+ (1,0) [0|0] "" Vector__XXX
 SG_ VCFRONT_battOverStagUpperLimit m13 : 6|1@1+ (1,0) [0|0] "" Vector__XXX
 SG_ VCFRONT_exteriorQuietModeAllowed m6 : 6|1@1+ (1,0) [0|0] "" Vector__XXX
 SG_ VCFRONT_hpCOP1BatteryHeatingAllo m14 : 6|1@1+ (1,0) [0|0] "" Vector__XXX
 SG_ VCFRONT_chillerExvCalibOffset m8 : 5|5@1- (8,0) [0|0] "" Vector__XXX
 SG_ VCFRONT_condenserPressureLimit m1 : 5|6@1+ (0.16,10) [0|0] "" Vector__XXX
 SG_ VCFRONT_coolantValveRecalReason m2 : 5|3@1+ (1,0) [0|0] "" Vector__XXX
 SG_ VCFRONT_espABSValveCurrent m20 : 5|4@1+ (0.1,0) [0|0] "" Vector__XXX
 SG_ VCFRONT_estPressureLiq m7 : 5|6@1+ (0.5,0) [0|0] "" Vector__XXX
 SG_ VCFRONT_exteriorQuietModeEnabled m6 : 5|1@1+ (1,0) [0|0] "" Vector__XXX
 SG_ VCFRONT_feedFwdMDotEvaporator m12 : 5|8@1+ (0.005,0) [0|0] "" Vector__XXX
 SG_ VCFRONT_frunkSwitch1Voltage m15 : 5|10@1+ (5,0) [0|0] "" Vector__XXX
 SG_ VCFRONT_homelinkRegionCode m3 : 5|4@1+ (1,0) [0|0] "" Vector__XXX
 SG_ VCFRONT_hpASBatteryHeatingAllowe m14 : 5|1@1+ (1,0) [0|0] "" Vector__XXX
 SG_ VCFRONT_hpChargeCableType m5 : 5|2@1+ (1,0) [0|0] "" Vector__XXX
 SG_ VCFRONT_hpForceScavenge m13 : 5|1@1+ (1,0) [0|0] "" Vector__XXX
 SG_ VCFRONT_leftFogLightCurrent m19 : 5|5@1+ (0.2,0) [0|0] "" Vector__XXX
 SG_ VCFRONT_louverPosReason m18 : 5|4@1+ (1,0) [0|0] "" Vector__XXX
 SG_ VCFRONT_modeTransitionID m0 : 5|6@1+ (1,0) [0|0] "" Vector__XXX
 SG_ VCFRONT_passiveSeriesRegOn m16 : 5|1@1+ (1,0) [0|0] "" Vector__XXX
 SG_ VCFRONT_radPassiveRejectEstimate m10 : 5|7@1+ (150,0) [0|0] "" Vector__XXX
 SG_ VCFRONT_superheatProtectionLimit m25 : 5|10@1+ (0.1,0) [0|0] "" Vector__XXX
 SG_ VCFRONT_tempSuperheatActFiltered m21 : 5|8@1- (0.25,26.5) [0|0] "" Vector__XXX
 SG_ VCFRONT_logging1HzIndex M : 0|5@1+ (1,0) [0|0] "" Vector__XXX

BO_ 721 VCFRONT_okToUseHighPower: 2 Vector__XXX
 SG_ VCFRONT_tasOkToUseHighPower : 8|1@1+ (1,0) [0|0] "" Vector__XXX
 SG_ VCFRONT_premAudioOkToUseHiPower : 7|1@1+ (1,0) [0|0] "" Vector__XXX
 SG_ VCFRONT_cpOkToUseHighPower : 6|1@1+ (1,0) [0|0] "" Vector__XXX
 SG_ VCFRONT_MCUAudioOkToUseHighPower : 5|1@1+ (1,0) [0|0] "" Vector__XXX
 SG_ VCFRONT_MCULogicOkToUseHighPower : 4|1@1+ (1,0) [0|0] "" Vector__XXX
 SG_ VCFRONT_das2OkToUseHighPower : 3|1@1+ (1,0) [0|0] "" Vector__XXX
 SG_ VCFRONT_das1OkToUseHighPower : 2|1@1+ (1,0) [0|0] "" Vector__XXX
 SG_ VCFRONT_vcrightOkToUseHighPower : 1|1@1+ (1,0) [0|0] "" Vector__XXX
 SG_ VCFRONT_vcleftOkToUseHighPower : 0|1@1+ (1,0) [0|0] "" Vector__XXX

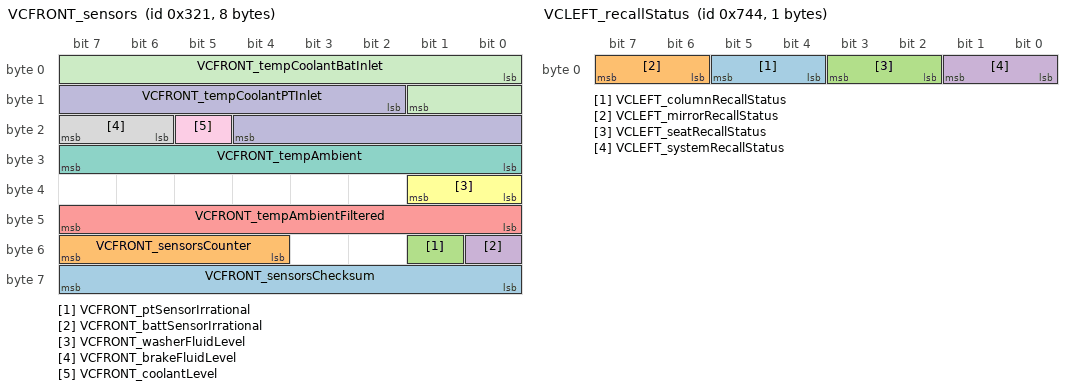
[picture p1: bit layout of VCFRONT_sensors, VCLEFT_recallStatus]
BO_ 801 VCFRONT_sensors: 8 Vector__XXX
 SG_ VCFRONT_sensorsChecksum : 56|8@1+ (1,0) [0|0] "" Vector__XXX
 SG_ VCFRONT_sensorsCounter : 52|4@1+ (1,0) [0|0] "" Vector__XXX
 SG_ VCFRONT_ptSensorIrrational : 49|1@1+ (1,0) [0|0] "" Vector__XXX
 SG_ VCFRONT_battSensorIrrational : 48|1@1+ (1,0) [0|0] "" Vector__XXX
 SG_ VCFRONT_tempAmbientFiltered : 40|8@1+ (0.5,-40) [0|0] "" Vector__XXX
 SG_ VCFRONT_washerFluidLevel : 32|2@1+ (1,0) [0|0] "" Vector__XXX
 SG_ VCFRONT_tempAmbient : 24|8@1+ (0.5,-40) [0|0] "" Vector__XXX
 SG_ VCFRONT_brakeFluidLevel : 22|2@1+ (1,0) [0|0] "" Vector__XXX
 SG_ VCFRONT_coolantLevel : 21|1@1+ (1,0) [0|0] "" Vector__XXX
 SG_ VCFRONT_tempCoolantPTInlet : 10|11@1+ (0.125,-40) [0|0] "" Vector__XXX
 SG_ VCFRONT_tempCoolantBatInlet : 0|10@1+ (0.125,-40) [0|0] "" Vector__XXX

BO_ 737 VCFRONT_status: 8 Vector__XXX
 SG_ VCFRONT_isActiveHeatingBattery m0 : 63|1@1+ (1,0) [0|0] "" Vector__XXX
 SG_ VCFRONT_frunkAccessPost m0 : 62|1@1+ (1,0) [0|0] "" Vector__XXX
 SG_ VCFRONT_headlampRightFanStatus m0 : 61|1@1+ (1,0) [0|0] "" Vector__XXX
 SG_ VCFRONT_extendedHvacPerfTestComm m2 : 60|4@1+ (1,0) [0|0] "" Vector__XXX
 SG_ VCFRONT_headlampLeftFanStatus m0 : 60|1@1+ (1,0) [0|0] "" Vector__XXX
 SG_ VCFRONT_thermalPerfTestRunning m2 : 59|1@1+ (1,0) [0|0] "" Vector__XXX
 SG_ VCFRONT_frunkLatchType m0 : 58|2@1+ (1,0) [0|0] "" Vector__XXX
 SG_ VCFRONT_closeValvesRoutineStatus m2 : 57|2@1+ (1,0) [0|0] "" Vector__XXX
 SG_ VCFRONT_passengerBuckleStatus m0 : 57|1@1+ (1,0) [0|0] "" Vector__XXX
 SG_ VCFRONT_isCOP1Running m2 : 56|1@1+ (1,0) [0|0] "" Vector__XXX
 SG_ VCFRONT_limitedSplitTempDeltaEnf m1 : 56|1@1+ (1,0) [0|0] "" Vector__XXX
 SG_ VCFRONT_windshieldCameraHeaterPo m4 : 56|6@1+ (2.5,0) [0|0] "" Vector__XXX
 SG_ VCFRONT_hvacReqOffForFasterCharg m1 : 55|1@1+ (1,0) [0|0] "" Vector__XXX
 SG_ VCFRONT_trunkExteriorWakeSwitch m0 : 55|1@1+ (1,0) [0|0] "" Vector__XXX
 SG_ VCFRONT_potentialRadiatorSteamUI m1 : 54|1@1+ (1,0) [0|0] "" Vector__XXX
 SG_ VCFRONT_refrigFillRoutineStatus m2 : 54|2@1+ (1,0) [0|0] "" Vector__XXX
 SG_ VCFRONT_potentialRadiatorSteam m1 : 53|1@1+ (1,0) [0|0] "" Vector__XXX
 SG_ VCFRONT_allowEvapInLowAmbient m1 : 52|1@1+ (1,0) [0|0] "" Vector__XXX
 SG_ VCFRONT_coolantFillRoutineStatus m2 : 52|2@1+ (1,0) [0|0] "" Vector__XXX
 SG_ VCFRONT_logVerbosity m3 : 52|3@1+ (1,0) [0|0] "" Vector__XXX
 SG_ VCFRONT_radarHeaterState m0 : 52|3@1+ (1,0) [0|0] "" Vector__XXX
 SG_ VCFRONT_activeLouverState m4 : 51|5@1+ (1,0) [0|0] "" Vector__XXX
 SG_ VCFRONT_espWakeLine m1 : 51|1@1+ (1,0) [0|0] "" Vector__XXX
 SG_ VCFRONT_hornOn m0 : 51|1@1+ (1,0) [0|0] "" Vector__XXX
 SG_ VCFRONT_anyDoorOpen m0 : 50|1@1+ (1,0) [0|0] "" Vector__XXX
 SG_ VCFRONT_anyClosureOpen m0 : 49|1@1+ (1,0) [0|0] "" Vector__XXX
 SG_ VCFRONT_hvacPerfTestCommand m2 : 49|3@1+ (1,0) [0|0] "" Vector__XXX
 SG_ VCFRONT_closureEasterEggState m1 : 48|3@1+ (1,0) [0|0] "" Vector__XXX
 SG_ VCFRONT_frunkInteriorRelSwitch m0 : 48|1@1+ (1,0) [0|0] "" Vector__XXX
 SG_ VCFRONT_occupantCount m1 : 45|3@1+ (1,0) [0|0] "" Vector__XXX
 SG_ VCFRONT_activeLouverOpenPos m4 : 44|7@1+ (1,0) [0|0] "" Vector__XXX
 SG_ VCFRONT_wiperHeaterState m1 : 42|3@1+ (1,0) [0|0] "" Vector__XXX
 SG_ VCFRONT_frunkLatchCurrent m0 : 40|8@1- (0.15748031496062992,0) [0|0] "" Vector__XXX
 SG_ VCFRONT_pressureRefrigDischarge m2 : 40|9@1+ (0.08,0) [0|0] "" Vector__XXX
 SG_ VCFRONT_vbatProt m3 : 40|12@1+ (0.005443676098,0) [0|0] "" Vector__XXX
 SG_ VCFRONT_wiperECUType m1 : 40|2@1+ (1,0) [0|0] "" Vector__XXX
 SG_ VCFRONT_maxHeatingPowerRightCC m4 : 37|7@1+ (100,0) [0|0] "" Vector__XXX
 SG_ VCFRONT_hibernationState m1 : 36|3@1+ (1,0) [0|0] "" Vector__XXX
 SG_ VCFRONT_wiperLINHealth m0 : 35|3@1+ (1,0) [0|0] "" Vector__XXX
 SG_ VCFRONT_lastUserPresenceUpdateEp m5 : 32|32@1+ (1,0) [0|0] "" Vector__XXX
 SG_ VCFRONT_pressureRefrigSuction m2 : 32|7@1+ (0.125,0) [0|0] "" Vector__XXX
 SG_ VCFRONT_wiperHealth m0 : 32|3@1+ (1,0) [0|0] "" Vector__XXX
 SG_ VCFRONT_isHeatPumpOilPurgeActive m2 : 31|1@1+ (1,0) [0|0] "" Vector__XXX
 SG_ VCFRONT_isColdStartRunning m2 : 30|1@1+ (1,0) [0|0] "" Vector__XXX
 SG_ VCFRONT_maxHeatingPowerLeftCC m4 : 30|7@1+ (100,0) [0|0] "" Vector__XXX
 SG_ VCFRONT_hasLowRefrigerant m2 : 29|1@1+ (1,0) [0|0] "" Vector__XXX
 SG_ VCFRONT_AS8510Voltage m3 : 28|12@1+ (0.005443676098,0) [0|0] "" Vector__XXX
 SG_ VCFRONT_hvacModeNotAttainable m2 : 28|1@1+ (1,0) [0|0] "" Vector__XXX
 SG_ VCFRONT_compPerfRecoveryLimited m2 : 27|1@1+ (1,0) [0|0] "" Vector__XXX
 SG_ VCFRONT_chillerDemandActive m2 : 26|1@1+ (1,0) [0|0] "" Vector__XXX
 SG_ VCFRONT_isEvapOperationAllowed m2 : 25|1@1+ (1,0) [0|0] "" Vector__XXX
 SG_ VCFRONT_crashUnlockOverrideSet m0 : 24|1@1+ (1,0) [0|0] "" Vector__XXX
 SG_ VCFRONT_freezeEvapITerm m2 : 24|1@1+ (1,0) [0|0] "" Vector__XXX
 SG_ VCFRONT_sleepCurrent m1 : 24|12@1+ (0.125,-511.875) [0|0] "" Vector__XXX
 SG_ VCFRONT_crashState m0 : 22|2@1+ (1,0) [0|0] "" Vector__XXX
 SG_ VCFRONT_UP_chargeStateTransition m5 : 21|1@1+ (1,0) [0|0] "" Vector__XXX
 SG_ VCFRONT_UP_passengerPresent m5 : 20|1@1+ (1,0) [0|0] "" Vector__XXX
 SG_ VCFRONT_crashDetectedType m0 : 20|2@1+ (1,0) [0|0] "" Vector__XXX
 SG_ VCFRONT_UP_UIUserActivity m5 : 19|1@1+ (1,0) [0|0] "" Vector__XXX
 SG_ VCFRONT_compPowerSupportingPT m4 : 19|11@1+ (10,0) [0|0] "" Vector__XXX
 SG_ VCFRONT_UP_UIChargePortDoorReque m5 : 18|1@1+ (1,0) [0|0] "" Vector__XXX
 SG_ VCFRONT_UP_chargePortDoorOpen m5 : 17|1@1+ (1,0) [0|0] "" Vector__XXX
 SG_ VCFRONT_UP_brakePressed m5 : 16|1@1+ (1,0) [0|0] "" Vector__XXX
 SG_ VCFRONT_minEvapHeatRejection m2 : 16|8@1+ (15,0) [0|0] "" Vector__XXX
 SG_ VCFRONT_vbatMonitorVoltage m3 : 16|12@1+ (0.005443676098,0) [0|0] "" Vector__XXX
 SG_ VCFRONT_wiperState m0 : 16|4@1+ (1,0) [0|0] "" Vector__XXX
 SG_ VCFRONT_UP_driverPresent m5 : 15|1@1+ (1,0) [0|0] "" Vector__XXX
 SG_ VCFRONT_wiperBlocked m0 : 15|1@1+ (1,0) [0|0] "" Vector__XXX
 SG_ VCFRONT_UP_anyClosureIsOpen m5 : 14|1@1+ (1,0) [0|0] "" Vector__XXX
 SG_ VCFRONT_UP_inTransportMode m5 : 13|1@1+ (1,0) [0|0] "" Vector__XXX
 SG_ VCFRONT_timeSpentSleeping m1 : 13|10@1+ (1,0) [0|0] "" Vector__XXX
 SG_ VCFRONT_HSDInitCompleteU16 m3 : 12|1@1+ (1,0) [0|0] "" Vector__XXX
 SG_ VCFRONT_UP_trunkOpen m5 : 12|1@1+ (1,0) [0|0] "" Vector__XXX
 SG_ VCFRONT_wiperPosition m0 : 12|3@1+ (1,0) [0|0] "" Vector__XXX
 SG_ VCFRONT_HSDInitCompleteU13 m3 : 11|1@1+ (1,0) [0|0] "" Vector__XXX
 SG_ VCFRONT_UP_rearPassengerDoorOpen m5 : 11|1@1+ (1,0) [0|0] "" Vector__XXX
 SG_ VCFRONT_PEResetLineState m3 : 10|1@1+ (1,0) [0|0] "" Vector__XXX
 SG_ VCFRONT_UP_rearDriverDoorOpen m5 : 10|1@1+ (1,0) [0|0] "" Vector__XXX
 SG_ VCFRONT_ChargePumpVoltageStable m3 : 9|1@1+ (1,0) [0|0] "" Vector__XXX
 SG_ VCFRONT_UP_frontPassengerDoorOpe m5 : 9|1@1+ (1,0) [0|0] "" Vector__XXX
 SG_ VCFRONT_UP_frontDriverDoorOpen m5 : 8|1@1+ (1,0) [0|0] "" Vector__XXX
 SG_ VCFRONT_compPowerSupportingHvac m4 : 8|11@1+ (10,0) [0|0] "" Vector__XXX
 SG_ VCFRONT_maxEvapHeatRejection m2 : 8|8@1+ (65,0) [0|0] "" Vector__XXX
 SG_ VCFRONT_railBState m3 : 8|1@1+ (1,0) [0|0] "" Vector__XXX
 SG_ VCFRONT_vehicleStatusDBG m1 : 8|5@1+ (1,0) [0|0] "" Vector__XXX
 SG_ VCFRONT_wiperSpeed m0 : 8|4@1+ (1,0) [0|0] "" Vector__XXX
 SG_ VCFRONT_UP_steeringWheelButtonIn m5 : 7|1@1+ (1,0) [0|0] "" Vector__XXX
 SG_ VCFRONT_cabinHeatingCapacityLimi m4 : 7|1@1+ (1,0) [0|0] "" Vector__XXX
 SG_ VCFRONT_railAState m3 : 7|1@1+ (1,0) [0|0] "" Vector__XXX
 SG_ VCFRONT_12VBRailStable m3 : 6|1@1+ (1,0) [0|0] "" Vector__XXX
 SG_ VCFRONT_UP_UIDisplayOnForUser m5 : 6|1@1+ (1,0) [0|0] "" Vector__XXX
 SG_ VCFRONT_cabinCoolingCapacityLimi m4 : 6|1@1+ (1,0) [0|0] "" Vector__XXX
 SG_ VCFRONT_12VARailStable m3 : 5|1@1+ (1,0) [0|0] "" Vector__XXX
 SG_ VCFRONT_UP_inDriveState m5 : 5|1@1+ (1,0) [0|0] "" Vector__XXX
 SG_ VCFRONT_iBoosterStateDBG m1 : 5|3@1+ (1,0) [0|0] "" Vector__XXX
 SG_ VCFRONT_5VBRailStable m3 : 4|1@1+ (1,0) [0|0] "" Vector__XXX
 SG_ VCFRONT_epasWakeLine m1 : 4|1@1+ (1,0) [0|0] "" Vector__XXX
 SG_ VCFRONT_5VARailStable m3 : 3|1@1+ (1,0) [0|0] "" Vector__XXX
 SG_ VCFRONT_frunkLatchStatus m0 : 3|4@1+ (1,0) [0|0] "" Vector__XXX
 SG_ VCFRONT_iBoosterWakeLine m1 : 3|1@1+ (1,0) [0|0] "" Vector__XXX
 SG_ VCFRONT_statusIndex M : 0|3@1+ (1,0) [0|0] "" Vector__XXX

BO_ 929 VCFRONT_vehicleStatus: 8 Vector__XXX
 SG_ VCFRONT_vehicleStatusChecksum : 56|8@1+ (1,0) [0|0] "" Vector__XXX
 SG_ VCFRONT_vehicleStatusCounter : 52|4@1+ (1,0) [0|0] "" Vector__XXX
 SG_ VCFRONT_pcsEFuseVoltage m0 : 42|10@1+ (0.1,0) [0|0] "" Vector__XXX
 SG_ VCFRONT_hpBattHeatingPowerTrgt m1 : 41|7@1+ (100,0) [0|0] "" Vector__XXX
 SG_ VCFRONT_2RowRightUnbuckled m0 : 40|2@1+ (1,0) [0|0] "" Vector__XXX
 SG_ VCFRONT_anySWEFuseActive m1 : 40|1@1+ (1,0) [0|0] "" Vector__XXX
 SG_ VCFRONT_driverEnteredCabinEstimateDBG m1 : 39|1@1+ (1,0) [0|0] "" Vector__XXX
 SG_ VCFRONT_2RowCenterUnbuckled m0 : 38|2@1+ (1,0) [0|0] "" Vector__XXX
 SG_ VCFRONT_refSystemNominal m1 : 38|1@1+ (1,0) [0|0] "" Vector__XXX
 SG_ VCFRONT_2RowLeftUnbuckled m0 : 36|2@1+ (1,0) [0|0] "" Vector__XXX
 SG_ VCFRONT_passengerUnbuckled m0 : 34|2@1+ (1,0) [0|0] "" Vector__XXX
 SG_ VCFRONT_driverUnbuckled m0 : 32|2@1+ (1,0) [0|0] "" Vector__XXX
 SG_ VCFRONT_driverDoorStatus m0 : 31|1@1+ (1,0) [0|0] "" Vector__XXX
 SG_ VCFRONT_driverBuckleStatus m0 : 30|1@1+ (1,0) [0|0] "" Vector__XXX
 SG_ VCFRONT_ota12VSupportRequest m0 : 29|1@1+ (1,0) [0|0] "" Vector__XXX
 SG_ VCFRONT_factoryLimitsOverrideOk m0 : 27|1@1+ (1,0) [0|0] "" Vector__XXX
 SG_ VCFRONT_PCSCurrent m1 : 25|13@1- (0.1,0) [0|0] "" Vector__XXX
 SG_ VC_userPresenceState m0 : 24|2@1+ (1,0) [0|0] "" Vector__XXX
 SG_ VCFRONT_dcr12VMilliOhms m0 : 16|8@1+ (1,0) [0|0] "" Vector__XXX
 SG_ VCFRONT_hvacReqBattCoolOutTemp m1 : 16|9@1+ (0.1,40) [0|0] "" Vector__XXX
 SG_ VCFRONT_12vStatusForDrive m0 : 14|2@1+ (1,0) [0|0] "" Vector__XXX
 SG_ VCFRONT_diPowerOnState m0 : 10|3@1+ (1,0) [0|0] "" Vector__XXX
 SG_ VCFRONT_accPlusAvailable m0 : 9|1@1+ (1,0) [0|0] "" Vector__XXX
 SG_ VCFRONT_passengerPresent m0 : 8|1@1+ (1,0) [0|0] "" Vector__XXX
 SG_ VCFRONT_driverPresent m0 : 7|1@1+ (1,0) [0|0] "" Vector__XXX
 SG_ VCFRONT_maxBattHeatRejection m1 : 6|10@1+ (30,0) [0|0] "" Vector__XXX
 SG_ VCFRONT_standbySupplySupported m0 : 6|1@1+ (1,0) [0|0] "" Vector__XXX
 SG_ VCFRONT_thermalSystemType m0 : 5|1@1+ (1,0) [0|0] "" Vector__XXX
 SG_ VCFRONT_3RowRightUnbuckled m1 : 4|2@1+ (1,0) [0|0] "" Vector__XXX
 SG_ VCFRONT_3RowLeftUnbuckled m1 : 2|2@1+ (1,0) [0|0] "" Vector__XXX
 SG_ VCFRONT_APGlassHeaterState m0 : 2|3@1+ (1,0) [0|0] "" Vector__XXX
 SG_ VCFRONT_bmsHvChargeEnable m1 : 1|1@1+ (1,0) [0|0] "" Vector__XXX
 SG_ VCFRONT_preconditionRequest m0 : 1|1@1+ (1,0) [0|0] "" Vector__XXX
 SG_ VCFRONT_vehicleStatusMuxIndex M : 0|1@1+ (1,0) [0|0] "" Vector__XXX

BO_ 864 VCLEFT_alertMatrix: 8 Vector__XXX
 SG_ VCLEFT_a060_engineeringBuild m0 : 63|1@1+ (1,0) [0|0] "" Vector__XXX
 SG_ VCLEFT_a120_DI_DRIVE_MIA m1 : 63|1@1+ (1,0) [0|0] "" Vector__XXX
 SG_ VCLEFT_a180_frontDoorLatchRehome m2 : 63|1@1+ (1,0) [0|0] "" Vector__XXX
 SG_ VCLEFT_a240_seatHeatShortFront m3 : 63|1@1+ (1,0) [0|0] "" Vector__XXX
 SG_ VCLEFT_a300_swcUnderVoltage m4 : 63|1@1+ (1,0) [0|0] "" Vector__XXX
 SG_ VCLEFT_a360_detectedStationaryWh m5 : 63|1@1+ (1,0) [0|0] "" Vector__XXX
 SG_ VCLEFT_a480_vnf1048Fault m7 : 63|1@1+ (1,0) [0|0] "" Vector__XXX
 SG_ VCLEFT_a059_inputResistanceHigh m0 : 62|1@1+ (1,0) [0|0] "" Vector__XXX
 SG_ VCLEFT_a119_SCCM_MIA m1 : 62|1@1+ (1,0) [0|0] "" Vector__XXX
 SG_ VCLEFT_a239_seatHeatIFront m3 : 62|1@1+ (1,0) [0|0] "" Vector__XXX
 SG_ VCLEFT_a299_swcMIA m4 : 62|1@1+ (1,0) [0|0] "" Vector__XXX
 SG_ VCLEFT_a359_liftgateLatchExitNoP m5 : 62|1@1+ (1,0) [0|0] "" Vector__XXX
 SG_ VCLEFT_a599_LVBatteryTypeUnsuppo m9 : 62|1@1+ (1,0) [0|0] "" Vector__XXX
 SG_ VCLEFT_a058_inputRHighSyncDebug m0 : 61|1@1+ (1,0) [0|0] "" Vector__XXX
 SG_ VCLEFT_a118_VCFRONT_MIA m1 : 61|1@1+ (1,0) [0|0] "" Vector__XXX
 SG_ VCLEFT_a238_lumbarValveMIA m3 : 61|1@1+ (1,0) [0|0] "" Vector__XXX
 SG_ VCLEFT_a358_debugLiftgateCurrent m5 : 61|1@1+ (1,0) [0|0] "" Vector__XXX
 SG_ VCLEFT_a478_BPillarCameraHeaterF m7 : 61|1@1+ (1,0) [0|0] "" Vector__XXX
 SG_ VCLEFT_a057_HVP_MIA m0 : 60|1@1+ (1,0) [0|0] "" Vector__XXX
 SG_ VCLEFT_a117_VCLEFT_MIA m1 : 60|1@1+ (1,0) [0|0] "" Vector__XXX
 SG_ VCLEFT_a237_lumbarOverPresB m3 : 60|1@1+ (1,0) [0|0] "" Vector__XXX
 SG_ VCLEFT_a297_seatBelowMinPumpTmp m4 : 60|1@1+ (1,0) [0|0] "" Vector__XXX
 SG_ VCLEFT_a357_liftgateUncalibrated m5 : 60|1@1+ (1,0) [0|0] "" Vector__XXX
 SG_ VCLEFT_a116_VCRIGHT_MIA m1 : 59|1@1+ (1,0) [0|0] "" Vector__XXX
 SG_ VCLEFT_a176_windowSealDefectRear m2 : 59|1@1+ (1,0) [0|0] "" Vector__XXX
 SG_ VCLEFT_a236_lumbarOverPresA m3 : 59|1@1+ (1,0) [0|0] "" Vector__XXX
 SG_ VCLEFT_a296_buckleFaultedRearC m4 : 59|1@1+ (1,0) [0|0] "" Vector__XXX
 SG_ VCLEFT_a356_liftgateFactoryTest m5 : 59|1@1+ (1,0) [0|0] "" Vector__XXX
 SG_ VCLEFT_a536_trunkFoldFlatSwitchF m8 : 59|1@1+ (1,0) [0|0] "" Vector__XXX
 SG_ VCLEFT_a115_VCSEC_MIA m1 : 58|1@1+ (1,0) [0|0] "" Vector__XXX
 SG_ VCLEFT_a175_windowSealDefectFron m2 : 58|1@1+ (1,0) [0|0] "" Vector__XXX
 SG_ VCLEFT_a235_seatCurrUnderLift m3 : 58|1@1+ (1,0) [0|0] "" Vector__XXX
 SG_ VCLEFT_a295_buckleFaultedRearL m4 : 58|1@1+ (1,0) [0|0] "" Vector__XXX
 SG_ VCLEFT_a355_liftgateUnexpectedSt m5 : 58|1@1+ (1,0) [0|0] "" Vector__XXX
 SG_ VCLEFT_a114_ESP_MIA m1 : 57|1@1+ (1,0) [0|0] "" Vector__XXX
 SG_ VCLEFT_a234_seatCurrUnderTilt m3 : 57|1@1+ (1,0) [0|0] "" Vector__XXX
 SG_ VCLEFT_a294_occupancyFaultedRear m4 : 57|1@1+ (1,0) [0|0] "" Vector__XXX
 SG_ VCLEFT_a354_eFuseMgmtLiftGate m5 : 57|1@1+ (1,0) [0|0] "" Vector__XXX
 SG_ VCLEFT_a113_UI_MIA m1 : 56|1@1+ (1,0) [0|0] "" Vector__XXX
 SG_ VCLEFT_a173_windowBtnDoorOpen m2 : 56|1@1+ (1,0) [0|0] "" Vector__XXX
 SG_ VCLEFT_a233_seatCurrUnderBack m3 : 56|1@1+ (1,0) [0|0] "" Vector__XXX
 SG_ VCLEFT_a293_occupancyFaultedRear m4 : 56|1@1+ (1,0) [0|0] "" Vector__XXX
 SG_ VCLEFT_a353_eFuseMgmtSteeringCol m5 : 56|1@1+ (1,0) [0|0] "" Vector__XXX
 SG_ VCLEFT_a112_EPBL_MIA m1 : 55|1@1+ (1,0) [0|0] "" Vector__XXX
 SG_ VCLEFT_a172_SPI_MIA m2 : 55|1@1+ (1,0) [0|0] "" Vector__XXX
 SG_ VCLEFT_a232_seatCurrUnderTrack m3 : 55|1@1+ (1,0) [0|0] "" Vector__XXX
 SG_ VCLEFT_a292_occupancyFaultedRear m4 : 55|1@1+ (1,0) [0|0] "" Vector__XXX
 SG_ VCLEFT_a352_liftgateClosingLatch m5 : 55|1@1+ (1,0) [0|0] "" Vector__XXX
 SG_ VCLEFT_a111_EPBR_MIA m1 : 54|1@1+ (1,0) [0|0] "" Vector__XXX
 SG_ VCLEFT_a231_seatEncOverLift m3 : 54|1@1+ (1,0) [0|0] "" Vector__XXX
 SG_ VCLEFT_a291_buckleFaultedFront m4 : 54|1@1+ (1,0) [0|0] "" Vector__XXX
 SG_ VCLEFT_a351_debugLiftgateCurrent m5 : 54|1@1+ (1,0) [0|0] "" Vector__XXX
 SG_ VCLEFT_a110_GTW_MIA m1 : 53|1@1+ (1,0) [0|0] "" Vector__XXX
 SG_ VCLEFT_a170_windowCurrentPeakR m2 : 53|1@1+ (1,0) [0|0] "" Vector__XXX
 SG_ VCLEFT_a230_seatEncOverTilt m3 : 53|1@1+ (1,0) [0|0] "" Vector__XXX
 SG_ VCLEFT_a290_occupancyFaultedFron m4 : 53|1@1+ (1,0) [0|0] "" Vector__XXX
 SG_ VCLEFT_a350_ensOutOfRange m5 : 53|1@1+ (1,0) [0|0] "" Vector__XXX
 SG_ VCLEFT_a109_RCM_MIA m1 : 52|1@1+ (1,0) [0|0] "" Vector__XXX
 SG_ VCLEFT_a169_windowCurrentPeakF m2 : 52|1@1+ (1,0) [0|0] "" Vector__XXX
 SG_ VCLEFT_a229_seatEncOverBack m3 : 52|1@1+ (1,0) [0|0] "" Vector__XXX
 SG_ VCLEFT_a289_handlePWMPeriodR m4 : 52|1@1+ (1,0) [0|0] "" Vector__XXX
 SG_ VCLEFT_a349_CPSleepUndervoltage m5 : 52|1@1+ (1,0) [0|0] "" Vector__XXX
 SG_ VCLEFT_a108_DIF_MIA m1 : 51|1@1+ (1,0) [0|0] "" Vector__XXX
 SG_ VCLEFT_a168_windowDebugPinchR m2 : 51|1@1+ (1,0) [0|0] "" Vector__XXX
 SG_ VCLEFT_a228_seatEncOverTrack m3 : 51|1@1+ (1,0) [0|0] "" Vector__XXX
 SG_ VCLEFT_a288_handlePWMPeriodF m4 : 51|1@1+ (1,0) [0|0] "" Vector__XXX
 SG_ VCLEFT_a348_CPSleepOvercurrent m5 : 51|1@1+ (1,0) [0|0] "" Vector__XXX
 SG_ VCLEFT_a528_unableToRunStuckOnTe m8 : 51|1@1+ (1,0) [0|0] "" Vector__XXX
 SG_ VCLEFT_a107_BMS_MIA m1 : 50|1@1+ (1,0) [0|0] "" Vector__XXX
 SG_ VCLEFT_a167_windowDebugPinchF m2 : 50|1@1+ (1,0) [0|0] "" Vector__XXX
 SG_ VCLEFT_a227_seatEncStallLift m3 : 50|1@1+ (1,0) [0|0] "" Vector__XXX
 SG_ VCLEFT_a287_windowSpeedInvalidR m4 : 50|1@1+ (1,0) [0|0] "" Vector__XXX
 SG_ VCLEFT_a347_nonContMonitorCleare m5 : 50|1@1+ (1,0) [0|0] "" Vector__XXX
 SG_ VCLEFT_a527_continuousFeedUnexpe m8 : 50|1@1+ (1,0) [0|0] "" Vector__XXX
 SG_ VCLEFT_a046_Task1000msError m0 : 49|1@1+ (1,0) [0|0] "" Vector__XXX
 SG_ VCLEFT_a106_PCS_MIA m1 : 49|1@1+ (1,0) [0|0] "" Vector__XXX
 SG_ VCLEFT_a166_windowDebug m2 : 49|1@1+ (1,0) [0|0] "" Vector__XXX
 SG_ VCLEFT_a226_seatEncStallTilt m3 : 49|1@1+ (1,0) [0|0] "" Vector__XXX
 SG_ VCLEFT_a286_windowSpeedInvalidF m4 : 49|1@1+ (1,0) [0|0] "" Vector__XXX
 SG_ VCLEFT_a346_eFuseMgmtVbatFused2 m5 : 49|1@1+ (1,0) [0|0] "" Vector__XXX
 SG_ VCLEFT_a526_pcbaOverTemperature m8 : 49|1@1+ (1,0) [0|0] "" Vector__XXX
 SG_ VCLEFT_a586_doorRemoteUnlatchFai m9 : 49|1@1+ (1,0) [0|0] "" Vector__XXX
 SG_ VCLEFT_a045_Task100msError m0 : 48|1@1+ (1,0) [0|0] "" Vector__XXX
 SG_ VCLEFT_a105_TAS_MIA m1 : 48|1@1+ (1,0) [0|0] "" Vector__XXX
 SG_ VCLEFT_a165_windowFactoryTest2 m2 : 48|1@1+ (1,0) [0|0] "" Vector__XXX
 SG_ VCLEFT_a225_seatEncStallBack m3 : 48|1@1+ (1,0) [0|0] "" Vector__XXX
 SG_ VCLEFT_a285_blowerChipComms m4 : 48|1@1+ (1,0) [0|0] "" Vector__XXX
 SG_ VCLEFT_a345_chargePortPowerCycli m5 : 48|1@1+ (1,0) [0|0] "" Vector__XXX
 SG_ VCLEFT_a525_LVBatterySWMisconfig m8 : 48|1@1+ (1,0) [0|0] "" Vector__XXX
 SG_ VCLEFT_a585_doorRemoteUnlatchFai m9 : 48|1@1+ (1,0) [0|0] "" Vector__XXX
 SG_ VCLEFT_a044_Task10msError m0 : 47|1@1+ (1,0) [0|0] "" Vector__XXX
 SG_ VCLEFT_a104_DAS_MIA m1 : 47|1@1+ (1,0) [0|0] "" Vector__XXX
 SG_ VCLEFT_a164_windowFactoryTest m2 : 47|1@1+ (1,0) [0|0] "" Vector__XXX
 SG_ VCLEFT_a224_seatEncStallTrack m3 : 47|1@1+ (1,0) [0|0] "" Vector__XXX
 SG_ VCLEFT_a284_blowerFbkSanity m4 : 47|1@1+ (1,0) [0|0] "" Vector__XXX
 SG_ VCLEFT_a584_doorRemoteUnlatchedR m9 : 47|1@1+ (1,0) [0|0] "" Vector__XXX
 SG_ VCLEFT_a043_Task1msError m0 : 46|1@1+ (1,0) [0|0] "" Vector__XXX
 SG_ VCLEFT_a103_CP_MIA m1 : 46|1@1+ (1,0) [0|0] "" Vector__XXX
 SG_ VCLEFT_a163_windowEncoderStallR m2 : 46|1@1+ (1,0) [0|0] "" Vector__XXX
 SG_ VCLEFT_a283_latchUnexpectedArmR m4 : 46|1@1+ (1,0) [0|0] "" Vector__XXX
 SG_ VCLEFT_a523_eFuseThresholdsIncor m8 : 46|1@1+ (1,0) [0|0] "" Vector__XXX
 SG_ VCLEFT_a583_doorRemoteUnlatchedF m9 : 46|1@1+ (1,0) [0|0] "" Vector__XXX
 SG_ VCLEFT_a042_HighStackUsage m0 : 45|1@1+ (1,0) [0|0] "" Vector__XXX
 SG_ VCLEFT_a102_PTC_MIA m1 : 45|1@1+ (1,0) [0|0] "" Vector__XXX
 SG_ VCLEFT_a162_windowEncoderStallF m2 : 45|1@1+ (1,0) [0|0] "" Vector__XXX
 SG_ VCLEFT_a282_latchUnexpectedArmF m4 : 45|1@1+ (1,0) [0|0] "" Vector__XXX
 SG_ VCLEFT_a342_trailerLightControll m5 : 45|1@1+ (1,0) [0|0] "" Vector__XXX
 SG_ VCLEFT_a522_trailerLightUnexpect m8 : 45|1@1+ (1,0) [0|0] "" Vector__XXX
 SG_ VCLEFT_a041_HighCPULoad m0 : 44|1@1+ (1,0) [0|0] "" Vector__XXX
 SG_ VCLEFT_a101_PM_MIA m1 : 44|1@1+ (1,0) [0|0] "" Vector__XXX
 SG_ VCLEFT_a161_windowUndercurrentR m2 : 44|1@1+ (1,0) [0|0] "" Vector__XXX
 SG_ VCLEFT_a281_latchDidNotDisarmR m4 : 44|1@1+ (1,0) [0|0] "" Vector__XXX
 SG_ VCLEFT_a341_trailerLightFault m5 : 44|1@1+ (1,0) [0|0] "" Vector__XXX
 SG_ VCLEFT_a521_seatHeatPadUnexpecte m8 : 44|1@1+ (1,0) [0|0] "" Vector__XXX
 SG_ VCLEFT_a100_CANbus_MIA m1 : 43|1@1+ (1,0) [0|0] "" Vector__XXX
 SG_ VCLEFT_a160_windowUndercurrentF m2 : 43|1@1+ (1,0) [0|0] "" Vector__XXX
 SG_ VCLEFT_a280_latchDidNotDisarmF m4 : 43|1@1+ (1,0) [0|0] "" Vector__XXX
 SG_ VCLEFT_a340_trailerRightTurnLigh m5 : 43|1@1+ (1,0) [0|0] "" Vector__XXX
 SG_ VCLEFT_a520_configMismatch m8 : 43|1@1+ (1,0) [0|0] "" Vector__XXX
 SG_ VCLEFT_a099_PARK_MIA m1 : 42|1@1+ (1,0) [0|0] "" Vector__XXX
 SG_ VCLEFT_a159_windowPinchOverideR m2 : 42|1@1+ (1,0) [0|0] "" Vector__XXX
 SG_ VCLEFT_a219_motorCurrentDropout m3 : 42|1@1+ (1,0) [0|0] "" Vector__XXX
 SG_ VCLEFT_a279_VCSECUnderVoltage m4 : 42|1@1+ (1,0) [0|0] "" Vector__XXX
 SG_ VCLEFT_a339_trailerLeftTurnLight m5 : 42|1@1+ (1,0) [0|0] "" Vector__XXX
 SG_ VCLEFT_a098_DIR_MIA m1 : 41|1@1+ (1,0) [0|0] "" Vector__XXX
 SG_ VCLEFT_a158_windowPinchOverideF m2 : 41|1@1+ (1,0) [0|0] "" Vector__XXX
 SG_ VCLEFT_a218_motorDriverFault m3 : 41|1@1+ (1,0) [0|0] "" Vector__XXX
 SG_ VCLEFT_a278_BLERearUnderVoltage m4 : 41|1@1+ (1,0) [0|0] "" Vector__XXX
 SG_ VCLEFT_a338_trailerLightControll m5 : 41|1@1+ (1,0) [0|0] "" Vector__XXX
 SG_ VCLEFT_a097_CMP_MIA m1 : 40|1@1+ (1,0) [0|0] "" Vector__XXX
 SG_ VCLEFT_a157_windowNoInputRear m2 : 40|1@1+ (1,0) [0|0] "" Vector__XXX
 SG_ VCLEFT_a217_SPI_MIA_debugData2 m3 : 40|1@1+ (1,0) [0|0] "" Vector__XXX
 SG_ VCLEFT_a277_BLELeftUnderVoltage m4 : 40|1@1+ (1,0) [0|0] "" Vector__XXX
 SG_ VCLEFT_a337_windowDropRevThermal m5 : 40|1@1+ (1,0) [0|0] "" Vector__XXX
 SG_ VCLEFT_a096_OCS1P_MIA m1 : 39|1@1+ (1,0) [0|0] "" Vector__XXX
 SG_ VCLEFT_a156_windowNoInputFront m2 : 39|1@1+ (1,0) [0|0] "" Vector__XXX
 SG_ VCLEFT_a216_SPI_MIA_debugData1 m3 : 39|1@1+ (1,0) [0|0] "" Vector__XXX
 SG_ VCLEFT_a276_mirrorDebug m4 : 39|1@1+ (1,0) [0|0] "" Vector__XXX
 SG_ VCLEFT_a336_windowDropRevThermal m5 : 39|1@1+ (1,0) [0|0] "" Vector__XXX
 SG_ VCLEFT_a095_CHG_MIA m1 : 38|1@1+ (1,0) [0|0] "" Vector__XXX
 SG_ VCLEFT_a155_windowThermalRear m2 : 38|1@1+ (1,0) [0|0] "" Vector__XXX
 SG_ VCLEFT_a215_currentDesyncWarning m3 : 38|1@1+ (1,0) [0|0] "" Vector__XXX
 SG_ VCLEFT_a275_leftTurnLightFault m4 : 38|1@1+ (1,0) [0|0] "" Vector__XXX
 SG_ VCLEFT_a335_intrusionSensorInter m5 : 38|1@1+ (1,0) [0|0] "" Vector__XXX
 SG_ VCLEFT_a455_liftgateUnexpectedSh m7 : 38|1@1+ (1,0) [0|0] "" Vector__XXX
 SG_ VCLEFT_a094_EPAS3P_MIA m1 : 37|1@1+ (1,0) [0|0] "" Vector__XXX
 SG_ VCLEFT_a154_windowThermalFront m2 : 37|1@1+ (1,0) [0|0] "" Vector__XXX
 SG_ VCLEFT_a214_epbmOverIDynNew m3 : 37|1@1+ (1,0) [0|0] "" Vector__XXX
 SG_ VCLEFT_a274_handleStuckActiveR m4 : 37|1@1+ (1,0) [0|0] "" Vector__XXX
 SG_ VCLEFT_a334_overheadConsoleInter m5 : 37|1@1+ (1,0) [0|0] "" Vector__XXX
 SG_ VCLEFT_a454_wirelessChargerFault m7 : 37|1@1+ (1,0) [0|0] "" Vector__XXX
 SG_ VCLEFT_a093_VCSEATP_MIA m1 : 36|1@1+ (1,0) [0|0] "" Vector__XXX
 SG_ VCLEFT_a153_windowUncalRear m2 : 36|1@1+ (1,0) [0|0] "" Vector__XXX
 SG_ VCLEFT_a213_epbmUnderIDynNew m3 : 36|1@1+ (1,0) [0|0] "" Vector__XXX
 SG_ VCLEFT_a273_handleStuckActiveF m4 : 36|1@1+ (1,0) [0|0] "" Vector__XXX
 SG_ VCLEFT_a333_overheadConsoleMIA m5 : 36|1@1+ (1,0) [0|0] "" Vector__XXX
 SG_ VCLEFT_a393_pitchEstimationNoGPS m6 : 36|1@1+ (1,0) [0|0] "" Vector__XXX
 SG_ VCLEFT_a453_liftgatePinchDetecte m7 : 36|1@1+ (1,0) [0|0] "" Vector__XXX
 SG_ VCLEFT_a573_seatHeatDisabledRear m9 : 36|1@1+ (1,0) [0|0] "" Vector__XXX
 SG_ VCLEFT_a092_VCSEATD_MIA m1 : 35|1@1+ (1,0) [0|0] "" Vector__XXX
 SG_ VCLEFT_a152_windowUncalFront m2 : 35|1@1+ (1,0) [0|0] "" Vector__XXX
 SG_ VCLEFT_a212_epbmOverIStaticNew m3 : 35|1@1+ (1,0) [0|0] "" Vector__XXX
 SG_ VCLEFT_a272_vhclPwrStateMsmtch m4 : 35|1@1+ (1,0) [0|0] "" Vector__XXX
 SG_ VCLEFT_a332_intrusionSensorMIA m5 : 35|1@1+ (1,0) [0|0] "" Vector__XXX
 SG_ VCLEFT_a392_pitchEstimationGPSIm m6 : 35|1@1+ (1,0) [0|0] "" Vector__XXX
 SG_ VCLEFT_a572_seatHeatDisabledRear m9 : 35|1@1+ (1,0) [0|0] "" Vector__XXX
 SG_ VCLEFT_a031_UDSActive m0 : 34|1@1+ (1,0) [0|0] "" Vector__XXX
 SG_ VCLEFT_a091_CMPD_MIA m1 : 34|1@1+ (1,0) [0|0] "" Vector__XXX
 SG_ VCLEFT_a151_windowPinchRear m2 : 34|1@1+ (1,0) [0|0] "" Vector__XXX
 SG_ VCLEFT_a211_epbmUnderIStaticNew m3 : 34|1@1+ (1,0) [0|0] "" Vector__XXX
 SG_ VCLEFT_a331_shortDropFailedR m5 : 34|1@1+ (1,0) [0|0] "" Vector__XXX
 SG_ VCLEFT_a391_pitchEstimationImpla m6 : 34|1@1+ (1,0) [0|0] "" Vector__XXX
 SG_ VCLEFT_a451_wirelessChargerMIA m7 : 34|1@1+ (1,0) [0|0] "" Vector__XXX
 SG_ VCLEFT_a571_seatHeatDisabledRear m9 : 34|1@1+ (1,0) [0|0] "" Vector__XXX
 SG_ VCLEFT_a030_ECULogUploadRequest m0 : 33|1@1+ (1,0) [0|0] "" Vector__XXX
 SG_ VCLEFT_a090_APS_MIA m1 : 33|1@1+ (1,0) [0|0] "" Vector__XXX
 SG_ VCLEFT_a150_windowPinchFront m2 : 33|1@1+ (1,0) [0|0] "" Vector__XXX
 SG_ VCLEFT_a210_epbStateTime m3 : 33|1@1+ (1,0) [0|0] "" Vector__XXX
 SG_ VCLEFT_a270_seatLiftHCEncStlDbg m4 : 33|1@1+ (1,0) [0|0] "" Vector__XXX
 SG_ VCLEFT_a330_shortDropFailedF m5 : 33|1@1+ (1,0) [0|0] "" Vector__XXX
 SG_ VCLEFT_a390_steerColUpDownEncode m6 : 33|1@1+ (1,0) [0|0] "" Vector__XXX
 SG_ VCLEFT_a570_seatHeatDisabledF m9 : 33|1@1+ (1,0) [0|0] "" Vector__XXX
 SG_ VCLEFT_a029_CoreDump m0 : 32|1@1+ (1,0) [0|0] "" Vector__XXX
 SG_ VCLEFT_a089_IBST_MIA m1 : 32|1@1+ (1,0) [0|0] "" Vector__XXX
 SG_ VCLEFT_a209_epbStateMisTime m3 : 32|1@1+ (1,0) [0|0] "" Vector__XXX
 SG_ VCLEFT_a269_seatTiltHCEncStlDbg m4 : 32|1@1+ (1,0) [0|0] "" Vector__XXX
 SG_ VCLEFT_a329_noRideHeightCalib m5 : 32|1@1+ (1,0) [0|0] "" Vector__XXX
 SG_ VCLEFT_a389_steerColInOutEncoder m6 : 32|1@1+ (1,0) [0|0] "" Vector__XXX
 SG_ VCLEFT_a088_DIRER_MIA m1 : 31|1@1+ (1,0) [0|0] "" Vector__XXX
 SG_ VCLEFT_a208_epbFaulted m3 : 31|1@1+ (1,0) [0|0] "" Vector__XXX
 SG_ VCLEFT_a268_seatBackHCEncStlDbg m4 : 31|1@1+ (1,0) [0|0] "" Vector__XXX
 SG_ VCLEFT_a328_hghtSnsrFaultRL m5 : 31|1@1+ (1,0) [0|0] "" Vector__XXX
 SG_ VCLEFT_a388_steerColUpDownMotorE m6 : 31|1@1+ (1,0) [0|0] "" Vector__XXX
 SG_ VCLEFT_a448_steeringColUpDownEnd m7 : 31|1@1+ (1,0) [0|0] "" Vector__XXX
 SG_ VCLEFT_a087_DIREL_MIA m1 : 30|1@1+ (1,0) [0|0] "" Vector__XXX
 SG_ VCLEFT_a207_epbmEnableWrong m3 : 30|1@1+ (1,0) [0|0] "" Vector__XXX
 SG_ VCLEFT_a267_seatTrackHCEncStlDbg m4 : 30|1@1+ (1,0) [0|0] "" Vector__XXX
 SG_ VCLEFT_a327_hghtSnsrFaultFL m5 : 30|1@1+ (1,0) [0|0] "" Vector__XXX
 SG_ VCLEFT_a387_steerColInOutMotorEn m6 : 30|1@1+ (1,0) [0|0] "" Vector__XXX
 SG_ VCLEFT_a447_steeringColInOutEnds m7 : 30|1@1+ (1,0) [0|0] "" Vector__XXX
 SG_ VCLEFT_a086_VCBATT_MIA m1 : 29|1@1+ (1,0) [0|0] "" Vector__XXX
 SG_ VCLEFT_a206_epbWrongDirection m3 : 29|1@1+ (1,0) [0|0] "" Vector__XXX
 SG_ VCLEFT_a266_seatLiftStallDebug m4 : 29|1@1+ (1,0) [0|0] "" Vector__XXX
 SG_ VCLEFT_a326_hghtSnsrUnplgdRL m5 : 29|1@1+ (1,0) [0|0] "" Vector__XXX
 SG_ VCLEFT_a386_steerColUpDownMotorU m6 : 29|1@1+ (1,0) [0|0] "" Vector__XXX
 SG_ VCLEFT_a446_trailerAuxReversePow m7 : 29|1@1+ (1,0) [0|0] "" Vector__XXX
 SG_ VCLEFT_a085_CCCM_MIA m1 : 28|1@1+ (1,0) [0|0] "" Vector__XXX
 SG_ VCLEFT_a145_brakeSwitchStuck m2 : 28|1@1+ (1,0) [0|0] "" Vector__XXX
 SG_ VCLEFT_a205_epbmOverIDyn m3 : 28|1@1+ (1,0) [0|0] "" Vector__XXX
 SG_ VCLEFT_a265_seatTiltStallDebug m4 : 28|1@1+ (1,0) [0|0] "" Vector__XXX
 SG_ VCLEFT_a325_hghtSnsrUnplgdFL m5 : 28|1@1+ (1,0) [0|0] "" Vector__XXX
 SG_ VCLEFT_a385_steerColInOutMotorUn m6 : 28|1@1+ (1,0) [0|0] "" Vector__XXX
 SG_ VCLEFT_a445_drv8703SpiFaultDBG m7 : 28|1@1+ (1,0) [0|0] "" Vector__XXX
 SG_ VCLEFT_a084_TPMS_MIA m1 : 27|1@1+ (1,0) [0|0] "" Vector__XXX
 SG_ VCLEFT_a204_epbmUnderIDyn m3 : 27|1@1+ (1,0) [0|0] "" Vector__XXX
 SG_ VCLEFT_a264_seatBackStallDebug m4 : 27|1@1+ (1,0) [0|0] "" Vector__XXX
 SG_ VCLEFT_a324_mirrorHeatFault m5 : 27|1@1+ (1,0) [0|0] "" Vector__XXX
 SG_ VCLEFT_a384_steerColUpDownMotorS m6 : 27|1@1+ (1,0) [0|0] "" Vector__XXX
 SG_ VCLEFT_a444_drv8703Fault m7 : 27|1@1+ (1,0) [0|0] "" Vector__XXX
 SG_ VCLEFT_a083_VCLEFT_IPC_MIA m1 : 26|1@1+ (1,0) [0|0] "" Vector__XXX
 SG_ VCLEFT_a143_mirrorManuallyFolded m2 : 26|1@1+ (1,0) [0|0] "" Vector__XXX
 SG_ VCLEFT_a203_epbmOverIStatic m3 : 26|1@1+ (1,0) [0|0] "" Vector__XXX
 SG_ VCLEFT_a263_seatTrackStallDebug m4 : 26|1@1+ (1,0) [0|0] "" Vector__XXX
 SG_ VCLEFT_a323_mirrorCalibrated m5 : 26|1@1+ (1,0) [0|0] "" Vector__XXX
 SG_ VCLEFT_a383_steerColInOutMotorSt m6 : 26|1@1+ (1,0) [0|0] "" Vector__XXX
 SG_ VCLEFT_a022_TaskInitError m0 : 25|1@1+ (1,0) [0|0] "" Vector__XXX
 SG_ VCLEFT_a082_VCRIGHT_IPC_MIA m1 : 25|1@1+ (1,0) [0|0] "" Vector__XXX
 SG_ VCLEFT_a202_epbmUnderIStatic m3 : 25|1@1+ (1,0) [0|0] "" Vector__XXX
 SG_ VCLEFT_a322_windowRezeroedDebugR m5 : 25|1@1+ (1,0) [0|0] "" Vector__XXX
 SG_ VCLEFT_a382_pitchEstimation2 m6 : 25|1@1+ (1,0) [0|0] "" Vector__XXX
 SG_ VCLEFT_a021_TaskSchedulerError m0 : 24|1@1+ (1,0) [0|0] "" Vector__XXX
 SG_ VCLEFT_a141_12VAuxPowerTrip m2 : 24|1@1+ (1,0) [0|0] "" Vector__XXX
 SG_ VCLEFT_a201_motorDutyEncDisabl m3 : 24|1@1+ (1,0) [0|0] "" Vector__XXX
 SG_ VCLEFT_a261_emergencyLatchRelRea m4 : 24|1@1+ (1,0) [0|0] "" Vector__XXX
 SG_ VCLEFT_a321_windowRezeroedDebugF m5 : 24|1@1+ (1,0) [0|0] "" Vector__XXX
 SG_ VCLEFT_a381_pitchEstimation1 m6 : 24|1@1+ (1,0) [0|0] "" Vector__XXX
 SG_ VCLEFT_a501_vnf1048Configuration m8 : 24|1@1+ (1,0) [0|0] "" Vector__XXX
 SG_ VCLEFT_a140_BLELeftPowerCycled m2 : 23|1@1+ (1,0) [0|0] "" Vector__XXX
 SG_ VCLEFT_a200_motorPhantomEncoder m3 : 23|1@1+ (1,0) [0|0] "" Vector__XXX
 SG_ VCLEFT_a260_latchDisarmDelayR m4 : 23|1@1+ (1,0) [0|0] "" Vector__XXX
 SG_ VCLEFT_a320_windowReportCrackedA m5 : 23|1@1+ (1,0) [0|0] "" Vector__XXX
 SG_ VCLEFT_a380_steerColThermalLimit m6 : 23|1@1+ (1,0) [0|0] "" Vector__XXX
 SG_ VCLEFT_a500_eFuseASICStateMismat m8 : 23|1@1+ (1,0) [0|0] "" Vector__XXX
 SG_ VCLEFT_a139_BLERearPowerCycled m2 : 22|1@1+ (1,0) [0|0] "" Vector__XXX
 SG_ VCLEFT_a259_latchDisarmDelayF m4 : 22|1@1+ (1,0) [0|0] "" Vector__XXX
 SG_ VCLEFT_a499_epbmInvalidateCdp m8 : 22|1@1+ (1,0) [0|0] "" Vector__XXX
 SG_ VCLEFT_a138_consoleDoorAssist m2 : 21|1@1+ (1,0) [0|0] "" Vector__XXX
 SG_ VCLEFT_a318_trailerIncorrectConf m5 : 21|1@1+ (1,0) [0|0] "" Vector__XXX
 SG_ VCLEFT_a017_NVMMStatusDbg m0 : 20|1@1+ (1,0) [0|0] "" Vector__XXX
 SG_ VCLEFT_a137_VCSECPowerCycled m2 : 20|1@1+ (1,0) [0|0] "" Vector__XXX
 SG_ VCLEFT_a197_VEHCANUndertrminate m3 : 20|1@1+ (1,0) [0|0] "" Vector__XXX
 SG_ VCLEFT_a317_epbmLimpModeEnabled m5 : 20|1@1+ (1,0) [0|0] "" Vector__XXX
 SG_ VCLEFT_a617_APP_MIA m10 : 20|1@1+ (1,0) [0|0] "" Vector__XXX
 SG_ VCLEFT_a016_NVMMRecordError m0 : 19|1@1+ (1,0) [0|0] "" Vector__XXX
 SG_ VCLEFT_a136_brakeSwitchMismatch m2 : 19|1@1+ (1,0) [0|0] "" Vector__XXX
 SG_ VCLEFT_a196_VEHCANOverterminate m3 : 19|1@1+ (1,0) [0|0] "" Vector__XXX
 SG_ VCLEFT_a316_mirrorPrematureFoldS m5 : 19|1@1+ (1,0) [0|0] "" Vector__XXX
 SG_ VCLEFT_a376_seat2RowBridgeCurren m6 : 19|1@1+ (1,0) [0|0] "" Vector__XXX
 SG_ VCLEFT_a015_NVMMError m0 : 18|1@1+ (1,0) [0|0] "" Vector__XXX
 SG_ VCLEFT_a135_SteerColInOutUnCal m2 : 18|1@1+ (1,0) [0|0] "" Vector__XXX
 SG_ VCLEFT_a315_leftInteriorTrunkLig m5 : 18|1@1+ (1,0) [0|0] "" Vector__XXX
 SG_ VCLEFT_a375_windowPinchOverrideN m6 : 18|1@1+ (1,0) [0|0] "" Vector__XXX
 SG_ VCLEFT_a134_SteerColUpDownUnCal m2 : 17|1@1+ (1,0) [0|0] "" Vector__XXX
 SG_ VCLEFT_a254_seatUncalLift m4 : 17|1@1+ (1,0) [0|0] "" Vector__XXX
 SG_ VCLEFT_a314_leftMapPocketLightFa m5 : 17|1@1+ (1,0) [0|0] "" Vector__XXX
 SG_ VCLEFT_a374_trailerLightFaultMod m6 : 17|1@1+ (1,0) [0|0] "" Vector__XXX
 SG_ VCLEFT_a494_12vSocketRearEFuseTr m8 : 17|1@1+ (1,0) [0|0] "" Vector__XXX
 SG_ VCLEFT_a013_AlertManagerFault m0 : 16|1@1+ (1,0) [0|0] "" Vector__XXX
 SG_ VCLEFT_a133_blowerLowRPMCBang m2 : 16|1@1+ (1,0) [0|0] "" Vector__XXX
 SG_ VCLEFT_a193_blowerMIA m3 : 16|1@1+ (1,0) [0|0] "" Vector__XXX
 SG_ VCLEFT_a253_seatUncalTilt m4 : 16|1@1+ (1,0) [0|0] "" Vector__XXX
 SG_ VCLEFT_a313_leftFootwellLightFau m5 : 16|1@1+ (1,0) [0|0] "" Vector__XXX
 SG_ VCLEFT_a373_windowSwOpenReqInDog m6 : 16|1@1+ (1,0) [0|0] "" Vector__XXX
 SG_ VCLEFT_a493_12vSocketFrontEFuseT m8 : 16|1@1+ (1,0) [0|0] "" Vector__XXX
 SG_ VCLEFT_a012_CPUReset m0 : 15|1@1+ (1,0) [0|0] "" Vector__XXX
 SG_ VCLEFT_a132_blowerSoftStall m2 : 15|1@1+ (1,0) [0|0] "" Vector__XXX
 SG_ VCLEFT_a192_blowerGeneralFault m3 : 15|1@1+ (1,0) [0|0] "" Vector__XXX
 SG_ VCLEFT_a252_seatUncalBack m4 : 15|1@1+ (1,0) [0|0] "" Vector__XXX
 SG_ VCLEFT_a312_leftTailLightFault m5 : 15|1@1+ (1,0) [0|0] "" Vector__XXX
 SG_ VCLEFT_a372_seat2RowBackrestUnla m6 : 15|1@1+ (1,0) [0|0] "" Vector__XXX
 SG_ VCLEFT_a131_blowerICTransFault m2 : 14|1@1+ (1,0) [0|0] "" Vector__XXX
 SG_ VCLEFT_a191_TLCOvercurrent m3 : 14|1@1+ (1,0) [0|0] "" Vector__XXX
 SG_ VCLEFT_a251_seatUncalTrack m4 : 14|1@1+ (1,0) [0|0] "" Vector__XXX
 SG_ VCLEFT_a311_leftBrakeLightFault m5 : 14|1@1+ (1,0) [0|0] "" Vector__XXX
 SG_ VCLEFT_a371_seat2RowTrackUnlatch m6 : 14|1@1+ (1,0) [0|0] "" Vector__XXX
 SG_ VCLEFT_a551_interiorDoorRequestI m9 : 14|1@1+ (1,0) [0|0] "" Vector__XXX
 SG_ VCLEFT_a010_ExtSupplyVoltError m0 : 13|1@1+ (1,0) [0|0] "" Vector__XXX
 SG_ VCLEFT_a130_blowerICWarning m2 : 13|1@1+ (1,0) [0|0] "" Vector__XXX
 SG_ VCLEFT_a190_eFuseMgmtVbatFused m3 : 13|1@1+ (1,0) [0|0] "" Vector__XXX
 SG_ VCLEFT_a250_seatHeatMIARearR m4 : 13|1@1+ (1,0) [0|0] "" Vector__XXX
 SG_ VCLEFT_a310_mirrorFoldStall m5 : 13|1@1+ (1,0) [0|0] "" Vector__XXX
 SG_ VCLEFT_a370_seat2RowPitchUnlatch m6 : 13|1@1+ (1,0) [0|0] "" Vector__XXX
 SG_ VCLEFT_a490_vehicleOccupiedOnOTA m8 : 13|1@1+ (1,0) [0|0] "" Vector__XXX
 SG_ VCLEFT_a550_ambientTempDelta m9 : 13|1@1+ (1,0) [0|0] "" Vector__XXX
 SG_ VCLEFT_a129_blowerICLatchFault m2 : 12|1@1+ (1,0) [0|0] "" Vector__XXX
 SG_ VCLEFT_a189_latchUnableToRearmR m3 : 12|1@1+ (1,0) [0|0] "" Vector__XXX
 SG_ VCLEFT_a249_seatHeatShortRearR m4 : 12|1@1+ (1,0) [0|0] "" Vector__XXX
 SG_ VCLEFT_a309_brakeSwitchFaulted m5 : 12|1@1+ (1,0) [0|0] "" Vector__XXX
 SG_ VCLEFT_a429_seatAbuseBufferFull m7 : 12|1@1+ (1,0) [0|0] "" Vector__XXX
 SG_ VCLEFT_a188_latchUnableToRearmF m3 : 11|1@1+ (1,0) [0|0] "" Vector__XXX
 SG_ VCLEFT_a248_seatHeatIRearR m4 : 11|1@1+ (1,0) [0|0] "" Vector__XXX
 SG_ VCLEFT_a308_sirenMIA m5 : 11|1@1+ (1,0) [0|0] "" Vector__XXX
 SG_ VCLEFT_a428_seatAbuseBufferWarn m7 : 11|1@1+ (1,0) [0|0] "" Vector__XXX
 SG_ VCLEFT_a187_latchReleaseFailedR m3 : 10|1@1+ (1,0) [0|0] "" Vector__XXX
 SG_ VCLEFT_a247_seatHeatMIARearC m4 : 10|1@1+ (1,0) [0|0] "" Vector__XXX
 SG_ VCLEFT_a307_handleDisconnectedR m5 : 10|1@1+ (1,0) [0|0] "" Vector__XXX
 SG_ VCLEFT_a427_seatAbuseMotorStop m7 : 10|1@1+ (1,0) [0|0] "" Vector__XXX
 SG_ VCLEFT_a006_CANTX_cyclicError m0 : 9|1@1+ (1,0) [0|0] "" Vector__XXX
 SG_ VCLEFT_a066_emiosIsrShortPeriodD m1 : 9|1@1+ (1,0) [0|0] "" Vector__XXX
 SG_ VCLEFT_a186_latchReleaseFailedF m3 : 9|1@1+ (1,0) [0|0] "" Vector__XXX
 SG_ VCLEFT_a246_seatHeatShortRearC m4 : 9|1@1+ (1,0) [0|0] "" Vector__XXX
 SG_ VCLEFT_a306_handleDisconnectedF m5 : 9|1@1+ (1,0) [0|0] "" Vector__XXX
 SG_ VCLEFT_a426_seatAbuseMotorWarn m7 : 9|1@1+ (1,0) [0|0] "" Vector__XXX
 SG_ VCLEFT_a546_mirrorFoldTypeChange m9 : 9|1@1+ (1,0) [0|0] "" Vector__XXX
 SG_ VCLEFT_a005_CANTXError m0 : 8|1@1+ (1,0) [0|0] "" Vector__XXX
 SG_ VCLEFT_a065_emiosIsrRateLimitedD m1 : 8|1@1+ (1,0) [0|0] "" Vector__XXX
 SG_ VCLEFT_a185_summonAborted m3 : 8|1@1+ (1,0) [0|0] "" Vector__XXX
 SG_ VCLEFT_a245_seatHeatIRearC m4 : 8|1@1+ (1,0) [0|0] "" Vector__XXX
 SG_ VCLEFT_a305_rearIntHandleUnexpec m5 : 8|1@1+ (1,0) [0|0] "" Vector__XXX
 SG_ VCLEFT_a365_pitchUnlatchDisabled m6 : 8|1@1+ (1,0) [0|0] "" Vector__XXX
 SG_ VCLEFT_a545_LVBatteryTypeUnknown m9 : 8|1@1+ (1,0) [0|0] "" Vector__XXX
 SG_ VCLEFT_a064_busSleepReqTimeout m1 : 7|1@1+ (1,0) [0|0] "" Vector__XXX
 SG_ VCLEFT_a244_seatHeatMIARearL m4 : 7|1@1+ (1,0) [0|0] "" Vector__XXX
 SG_ VCLEFT_a304_frontIntHandleUnexpe m5 : 7|1@1+ (1,0) [0|0] "" Vector__XXX
 SG_ VCLEFT_a484_leftBrakeLightFaultU m8 : 7|1@1+ (1,0) [0|0] "" Vector__XXX
 SG_ VCLEFT_a003_SWAssertion m0 : 6|1@1+ (1,0) [0|0] "" Vector__XXX
 SG_ VCLEFT_a063_SwitchFault m1 : 6|1@1+ (1,0) [0|0] "" Vector__XXX
 SG_ VCLEFT_a123_AID_MIA m2 : 6|1@1+ (1,0) [0|0] "" Vector__XXX
 SG_ VCLEFT_a183_doorStateFactoryTest m3 : 6|1@1+ (1,0) [0|0] "" Vector__XXX
 SG_ VCLEFT_a243_seatHeatShortRearL m4 : 6|1@1+ (1,0) [0|0] "" Vector__XXX
 SG_ VCLEFT_a303_eFuseMgmtWindowLift m5 : 6|1@1+ (1,0) [0|0] "" Vector__XXX
 SG_ VCLEFT_a363_liftgateOpenAngleSet m6 : 6|1@1+ (1,0) [0|0] "" Vector__XXX
 SG_ VCLEFT_a483_leftTurnLightFaultUs m8 : 6|1@1+ (1,0) [0|0] "" Vector__XXX
 SG_ VCLEFT_a002_PowerLossReset m0 : 5|1@1+ (1,0) [0|0] "" Vector__XXX
 SG_ VCLEFT_a062_XCPWasConnected m1 : 5|1@1+ (1,0) [0|0] "" Vector__XXX
 SG_ VCLEFT_a122_ICR_MIA m2 : 5|1@1+ (1,0) [0|0] "" Vector__XXX
 SG_ VCLEFT_a182_emergencyLatchRel m3 : 5|1@1+ (1,0) [0|0] "" Vector__XXX
 SG_ VCLEFT_a242_seatHeatIRearL m4 : 5|1@1+ (1,0) [0|0] "" Vector__XXX
 SG_ VCLEFT_a302_blowerGeneralFault m5 : 5|1@1+ (1,0) [0|0] "" Vector__XXX
 SG_ VCLEFT_a362_movingThresholdsInco m6 : 5|1@1+ (1,0) [0|0] "" Vector__XXX
 SG_ VCLEFT_a482_NCV77XXFault m8 : 5|1@1+ (1,0) [0|0] "" Vector__XXX
 SG_ VCLEFT_a001_WatchdogReset m0 : 4|1@1+ (1,0) [0|0] "" Vector__XXX
 SG_ VCLEFT_a061_XCPConnected m1 : 4|1@1+ (1,0) [0|0] "" Vector__XXX
 SG_ VCLEFT_a181_rearDoorLatchRehome m3 : 4|1@1+ (1,0) [0|0] "" Vector__XXX
 SG_ VCLEFT_a241_seatHeatMIAFront m4 : 4|1@1+ (1,0) [0|0] "" Vector__XXX
 SG_ VCLEFT_a301_swcOverVoltage m5 : 4|1@1+ (1,0) [0|0] "" Vector__XXX
 SG_ VCLEFT_a361_stationaryThresholds m6 : 4|1@1+ (1,0) [0|0] "" Vector__XXX
 SG_ VCLEFT_a481_vnf1048SelfTestFailu m8 : 4|1@1+ (1,0) [0|0] "" Vector__XXX
 SG_ VCLEFT_matrixIndex M : 0|4@1+ (1,0) [0|0] "" Vector__XXX

BO_ 258 VCLEFT_doorStatus: 8 VEH
 SG_ VCLEFT_frontHandlePWM: 16|7@1+ (1,0) [0|0] "%" X
 SG_ VCLEFT_frontHandlePulled: 10|1@1+ (1,0) [0|0] "" X
 SG_ VCLEFT_frontHandlePulledPersist: 62|1@1+ (1,0) [0|0] "" X
 SG_ VCLEFT_frontIntSwitchPressed: 31|1@1+ (1,0) [0|0] "" X
 SG_ VCLEFT_frontLatchStatus: 0|4@1+ (1,0) [0|0] "" X
 SG_ VCLEFT_frontLatchSwitch: 8|1@1+ (1,0) [0|0] "" X
 SG_ VCLEFT_frontRelActuatorSwitch: 12|1@1+ (1,0) [0|0] "" X
 SG_ VCLEFT_mirrorDipped: 61|1@1+ (1,0) [0|0] "" X
 SG_ VCLEFT_mirrorFoldState: 52|3@1+ (1,0) [0|0] "" X
 SG_ VCLEFT_mirrorHeatState: 58|3@1+ (1,0) [0|0] "" X
 SG_ VCLEFT_mirrorRecallState: 55|3@1+ (1,0) [0|0] "" X
 SG_ VCLEFT_mirrorState: 49|3@1+ (1,0) [0|0] "" X
 SG_ VCLEFT_mirrorTiltXPosition: 33|8@1+ (0.02,0) [0|0] "V" X
 SG_ VCLEFT_mirrorTiltYPosition: 41|8@1+ (0.02,0) [0|0] "V" X
 SG_ VCLEFT_rearHandlePWM: 24|7@1+ (1,0) [0|0] "%" X
 SG_ VCLEFT_rearHandlePulled: 11|1@1+ (1,0) [0|0] "" X
 SG_ VCLEFT_rearIntSwitchPressed: 32|1@1+ (1,0) [0|0] "" X
 SG_ VCLEFT_rearLatchStatus: 4|4@1+ (1,0) [0|0] "" X
 SG_ VCLEFT_rearLatchSwitch: 9|1@1+ (1,0) [0|0] "" X
 SG_ VCLEFT_rearRelActuatorSwitch: 13|1@1+ (1,0) [0|0] "" X

BO_ 626 VCLEFT_epbmDebug: 8 VEH
 SG_ VCLEFT_epbmDebugIndex M: 0|1@1+ (1,0) [0|0] "" X
 SG_ VCLEFT_epbmCaliperState m0: 1|3@1+ (1,0) [0|0] "" X
 SG_ VCLEFT_epbmMotorEnabled m0: 4|1@1+ (1,0) [0|0] "" X
 SG_ VCLEFT_epbMotorCurrent m0: 5|11@1+ (0.01,0) [0|0] "A" X
 SG_ VCLEFT_epbmApplyVoltage m0: 16|11@1+ (0.01,0) [0|0] "A" X
 SG_ VCLEFT_epbmReleaseVoltage m0: 27|11@1+ (0.01,0) [0|0] "A" X
 SG_ VCLEFT_summonFaultReason m0: 38|5@1+ (1,0) [0|0] "" X
 SG_ VCLEFT_epbSummonState m0: 43|3@1+ (1,0) [0|0] "" X
 SG_ VCLEFT_epbmSummonState m0: 46|3@1+ (1,0) [0|0] "" X
 SG_ VCLEFT_epbmUnitStatus m0: 49|5@1+ (1,0) [0|0] "" X
 SG_ VCLEFT_epbUnitStatus m0: 54|5@1+ (1,0) [0|0] "" X
 SG_ VCLEFT_epbmFaultStatus m0: 59|2@1+ (1,0) [0|0] "" X
 SG_ VCLEFT_epbFaultStatus m0: 61|2@1+ (1,0) [0|0] "" X
 SG_ VCLEFT_epbmOpenAllowed m1: 1|1@1+ (1,0) [0|0] "" X
 SG_ VCLEFT_epbmDynamicAllowed m1: 2|1@1+ (1,0) [0|0] "" X
 SG_ VCLEFT_epbmParkAllowed m1: 3|1@1+ (1,0) [0|0] "" X
 SG_ VCLEFT_epbmStartAllowed m1: 4|1@1+ (1,0) [0|0] "" X
 SG_ VCLEFT_epbmServiceAllowed m1: 5|1@1+ (1,0) [0|0] "" X
 SG_ VCLEFT_epbmWinchAllowed m1: 6|1@1+ (1,0) [0|0] "" X
 SG_ VCLEFT_epbmWinchReleaseAllowed m1: 7|1@1+ (1,0) [0|0] "" X
 SG_ VCLEFT_epbmParkingAllowed m1: 8|1@1+ (1,0) [0|0] "" X
 SG_ VCLEFT_epbmDynApplyingAllowed m1: 9|1@1+ (1,0) [0|0] "" X
 SG_ VCLEFT_epbmReleasingAllowed m1: 10|1@1+ (1,0) [0|0] "" X
 SG_ VCLEFT_epbmFaultAllowed m1: 11|1@1+ (1,0) [0|0] "" X
 SG_ VCLEFT_epbmSummonAllowed m1: 12|1@1+ (1,0) [0|0] "" X
 SG_ VCLEFT_epbmSummonParkAllowed m1: 13|1@1+ (1,0) [0|0] "" X
 SG_ VCLEFT_epbmSummonReleaseAllowed m1: 14|1@1+ (1,0) [0|0] "" X
 SG_ VCLEFT_summonInitAllowed m1: 15|1@1+ (1,0) [0|0] "" X
 SG_ VCLEFT_epbmUnknownAllowed m1: 16|1@1+ (1,0) [0|0] "" X
 SG_ VCLEFT_summonIdleAllowed m1: 17|1@1+ (1,0) [0|0] "" X
 SG_ VCLEFT_summonArmedAllowed m1: 18|1@1+ (1,0) [0|0] "" X
 SG_ VCLEFT_summonActiveAllowed m1: 19|1@1+ (1,0) [0|0] "" X
 SG_ VCLEFT_summonCompleteAllowed m1: 20|1@1+ (1,0) [0|0] "" X
 SG_ VCLEFT_summonFaultAllowed m1: 21|1@1+ (1,0) [0|0] "" X
 SG_ VCLEFT_summonUnavailableAllowed m1: 22|1@1+ (1,0) [0|0] "" X
 SG_ VCLEFT_cdpEnumDummy m1: 24|2@1+ (1,0) [0|0] "" X

BO_ 642 VCLEFT_hvacBlowerFeedback: 8 VEH
 SG_ VCLEFT_blowerIndex M: 0|2@1+ (1,0) [0|0] "" X
 SG_ VCLEFT_hvacBlowerEnabled m0: 2|1@1+ (1,0) [0|0] "" X
 SG_ VCLEFT_hvacBlowerOutputDuty m0: 3|7@1+ (1,0) [0|0] "%" X
 SG_ VCLEFT_hvacBlowerRPMTarget m0: 10|10@1+ (10,0) [0|0] "rpm" X
 SG_ VCLEFT_hvacBlowerRPMActual m0: 20|10@1+ (10,0) [0|0] "rpm" X
 SG_ VCLEFT_hvacBlowerTorque m0: 34|8@1- (0.025,-1.5) [0|0] "Nm" X
 SG_ VCLEFT_hvacBlowerFETTemp m0: 42|8@1+ (1,-40) [0|0] "degC" X
 SG_ VCLEFT_hvacBlowerITerm m0: 50|8@1+ (0.025,-1.5) [0|0] "Nm" X
 SG_ VCLEFT_hvacBlowerInitd m0: 58|1@1+ (1,0) [0|0] "" X
 SG_ VCLEFT_hvacBlowerFault m0: 59|1@1+ (1,0) [0|0] "" X
 SG_ VCLEFT_hvacBlowerLimitFETTemps m0: 60|1@1+ (1,0) [0|0] "" X
 SG_ VCLEFT_hvacBlowerPowerOn m0: 61|1@1+ (1,0) [0|0] "" X
 SG_ VCLEFT_hvacBlowerSpiError m0: 62|1@1+ (1,0) [0|0] "" X
 SG_ VCLEFT_hvacBlowerRs m1: 2|8@1+ (0.0025,0) [0|0] "Ohm" X
 SG_ VCLEFT_hvacBlowerIPhase0 m1: 10|8@1+ (0.2,0) [0|0] "A" X
 SG_ VCLEFT_hvacBlowerIPhase1 m1: 18|8@1+ (0.2,0) [0|0] "A" X
 SG_ VCLEFT_hvacBlowerIPhase2 m1: 26|8@1+ (0.2,0) [0|0] "A" X

BO_ 770 VCLEFT_info: 8 Vector__XXX
 SG_ VCLEFT_infoComponentId m10 : 48|16@1+ (1,0) [0|0] "" Vector__XXX
 SG_ VCLEFT_infoSubUsageId m11 : 40|16@1+ (1,0) [0|0] "" Vector__XXX
 SG_ VCLEFT_infoCBCAppCRC m31 : 32|32@1+ (1,0) [0|0] "" Vector__XXX
 SG_ VCLEFT_infoHardwareId m10 : 32|16@1+ (1,0) [0|0] "" Vector__XXX
 SG_ VCLEFT_infoLUMBARLAppCRC m16 : 32|32@1+ (1,0) [0|0] "" Vector__XXX
 SG_ VCLEFT_infoRGBIPFLAppCRC m38 : 32|32@1+ (1,0) [0|0] "" Vector__XXX
 SG_ VCLEFT_infoRGBIPFRAppCRC m39 : 32|32@1+ (1,0) [0|0] "" Vector__XXX
 SG_ VCLEFT_infoSubcomponent3 m24 : 32|32@1+ (1,0) [0|0] "" Vector__XXX
 SG_ VCLEFT_infoTLCAppCRC m33 : 32|32@1+ (1,0) [0|0] "" Vector__XXX
 SG_ VCLEFT_infoVCUSBAppCRC m32 : 32|32@1+ (1,0) [0|0] "" Vector__XXX
 SG_ VCLEFT_swcAppCRC m23 : 32|32@1+ (1,0) [0|0] "" Vector__XXX
 SG_ VCLEFT_infoBootCrc m20 : 24|32@1+ (1,0) [0|0] "" Vector__XXX
 SG_ VCLEFT_infoUsageId m11 : 24|16@1+ (1,0) [0|0] "" Vector__XXX
 SG_ VCLEFT_infoAssemblyId m11 : 16|8@1+ (1,0) [0|0] "" Vector__XXX
 SG_ VCLEFT_infoBuildConfigId m10 : 16|16@1+ (1,0) [0|0] "" Vector__XXX
 SG_ VCLEFT_infoAppCrc m13 : 8|32@1+ (1,0) [0|0] "" Vector__XXX
 SG_ VCLEFT_infoAppGitHash m17 : 8|56@1+ (1,0) [0|0] "" Vector__XXX
 SG_ VCLEFT_infoBootGitHash m18 : 8|56@1+ (1,0) [0|0] "" Vector__XXX
 SG_ VCLEFT_infoBootUdsProtoVersion m20 : 8|16@1+ (1,0) [0|0] "" Vector__XXX
 SG_ VCLEFT_infoBuildType m10 : 8|3@1+ (1,0) [0|0] "" Vector__XXX
 SG_ VCLEFT_infoPcbaId m11 : 8|8@1+ (1,0) [0|0] "" Vector__XXX
 SG_ VCLEFT_infoPlatformType m19 : 8|8@1+ (1,0) [0|0] "" Vector__XXX
 SG_ VCLEFT_infoIndex M : 0|8@1+ (1,0) [0|0] "" Vector__XXX

BO_ 1860 VCLEFT_recallStatus: 1 VEH
 SG_ VCLEFT_columnRecallStatus: 4|2@1+ (1,0) [0|0] "" X
 SG_ VCLEFT_mirrorRecallStatus: 6|2@1+ (1,0) [0|0] "" X
 SG_ VCLEFT_seatRecallStatus: 2|2@1+ (1,0) [0|0] "" X
 SG_ VCLEFT_systemRecallStatus: 0|2@1+ (1,0) [0|0] "" X

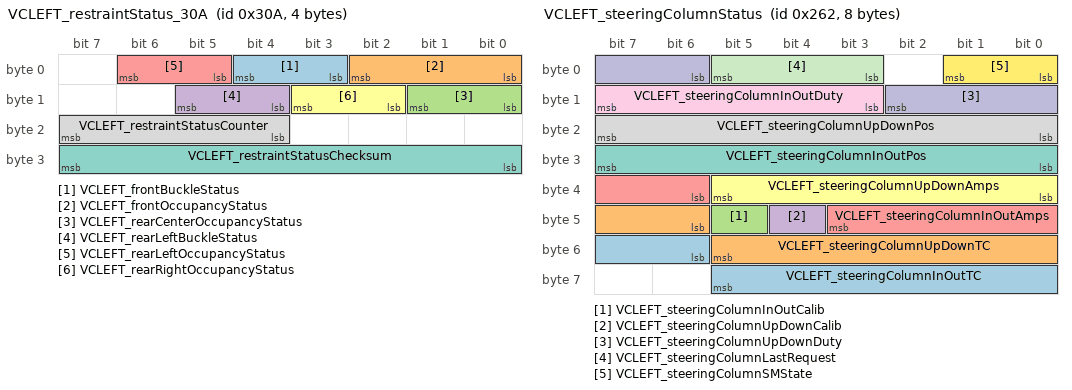
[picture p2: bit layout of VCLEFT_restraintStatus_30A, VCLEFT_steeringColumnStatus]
BO_ 778 VCLEFT_restraintStatus_30A: 4 VEH
 SG_ VCLEFT_frontBuckleStatus: 3|2@1+ (1,0) [0|0] "" X
 SG_ VCLEFT_frontOccupancyStatus: 0|3@1+ (1,0) [0|0] "" X
 SG_ VCLEFT_rearCenterOccupancyStatus: 8|2@1+ (1,0) [0|0] "" X
 SG_ VCLEFT_rearLeftBuckleStatus: 12|2@1+ (1,0) [0|0] "" X
 SG_ VCLEFT_rearLeftOccupancyStatus: 5|2@1+ (1,0) [0|0] "" X
 SG_ VCLEFT_rearRightOccupancyStatus: 10|2@1+ (1,0) [0|0] "" X
 SG_ VCLEFT_restraintStatusChecksum: 24|8@1+ (1,0) [0|0] "" X
 SG_ VCLEFT_restraintStatusCounter: 20|4@1+ (1,0) [0|0] "" X

BO_ 1250 VCLEFT_seatStatus: 8 Vector__XXX
 SG_ VCLEFT_lumbarDevMaxPumpPressB m4 : 60|1@1+ (1,0) [0|0] "" Vector__XXX
 SG_ VCLEFT_lumbarDevMaxPumpPressA m4 : 59|1@1+ (1,0) [0|0] "" Vector__XXX
 SG_ VCLEFT_lumbarGeneralErr m4 : 58|1@1+ (1,0) [0|0] "" Vector__XXX
 SG_ VCLEFT_lumbarMinPErr m4 : 57|1@1+ (1,0) [0|0] "" Vector__XXX
 SG_ VCLEFT_lumbarMaxOperatingPErr m4 : 56|1@1+ (1,0) [0|0] "" Vector__XXX
 SG_ VCLEFT_frontSeatBackPercentage m1 : 55|7@1+ (1,0) [0|0] "" Vector__XXX
 SG_ VCLEFT_frontSeatLiftPercentage m2 : 55|7@1+ (1,0) [0|0] "" Vector__XXX
 SG_ VCLEFT_frontSeatTiltPercentage m3 : 55|7@1+ (1,0) [0|0] "" Vector__XXX
 SG_ VCLEFT_frontSeatTrackPercentage m0 : 55|7@1+ (1,0) [0|0] "" Vector__XXX
 SG_ VCLEFT_lumbarOvercurrentErr m4 : 55|1@1+ (1,0) [0|0] "" Vector__XXX
 SG_ VCLEFT_lumbarMaxPErr m4 : 54|1@1+ (1,0) [0|0] "" Vector__XXX
 SG_ VCLEFT_frontSeatBackBridgeSt m1 : 53|2@1+ (1,0) [0|0] "" Vector__XXX
 SG_ VCLEFT_frontSeatLiftBridgeSt m2 : 53|2@1+ (1,0) [0|0] "" Vector__XXX
 SG_ VCLEFT_frontSeatTiltBridgeSt m3 : 53|2@1+ (1,0) [0|0] "" Vector__XXX
 SG_ VCLEFT_frontSeatTrackBridgeSt m0 : 53|2@1+ (1,0) [0|0] "" Vector__XXX
 SG_ VCLEFT_lumbarActiveTooLongErr m4 : 53|1@1+ (1,0) [0|0] "" Vector__XXX
 SG_ VCLEFT_frontSeatBackLog m1 : 52|1@1+ (1,0) [0|0] "" Vector__XXX
 SG_ VCLEFT_frontSeatLiftLog m2 : 52|1@1+ (1,0) [0|0] "" Vector__XXX
 SG_ VCLEFT_frontSeatTiltLog m3 : 52|1@1+ (1,0) [0|0] "" Vector__XXX
 SG_ VCLEFT_frontSeatTrackLog m0 : 52|1@1+ (1,0) [0|0] "" Vector__XXX
 SG_ VCLEFT_frontSeatBackCalibrated m1 : 51|1@1+ (1,0) [0|0] "" Vector__XXX
 SG_ VCLEFT_frontSeatLiftCalibrated m2 : 51|1@1+ (1,0) [0|0] "" Vector__XXX
 SG_ VCLEFT_frontSeatTiltCalibrated m3 : 51|1@1+ (1,0) [0|0] "" Vector__XXX
 SG_ VCLEFT_frontSeatTrackCalibrated m0 : 51|1@1+ (1,0) [0|0] "" Vector__XXX
 SG_ VCLEFT_frontSeatBackState m1 : 48|3@1+ (1,0) [0|0] "" Vector__XXX
 SG_ VCLEFT_frontSeatLiftState m2 : 48|3@1+ (1,0) [0|0] "" Vector__XXX
 SG_ VCLEFT_frontSeatTiltState m3 : 48|3@1+ (1,0) [0|0] "" Vector__XXX
 SG_ VCLEFT_frontSeatTrackState m0 : 48|3@1+ (1,0) [0|0] "" Vector__XXX
 SG_ VCLEFT_lumbarBPressureHpaFilt m4 : 43|10@1+ (1,0) [0|0] "" Vector__XXX
 SG_ VCLEFT_frontSeatTiltPosOffset m6 : 40|12@1- (0.1,0) [0|0] "" Vector__XXX
 SG_ VCLEFT_frontSeatTiltPosReal m5 : 40|12@1- (0.1,0) [0|0] "" Vector__XXX
 SG_ VCLEFT_frontSeatBackDuty m1 : 36|12@1- (0.1,0) [0|0] "" Vector__XXX
 SG_ VCLEFT_frontSeatLiftDuty m2 : 36|12@1- (0.1,0) [0|0] "" Vector__XXX
 SG_ VCLEFT_frontSeatTiltDuty m3 : 36|12@1- (0.1,0) [0|0] "" Vector__XXX
 SG_ VCLEFT_frontSeatTrackDuty m0 : 36|12@1- (0.1,0) [0|0] "" Vector__XXX
 SG_ VCLEFT_lumbarBPressureHpa m4 : 31|12@1+ (1,0) [0|0] "" Vector__XXX
 SG_ VCLEFT_frontSeatLiftPosOffset m6 : 28|12@1- (1,0) [0|0] "" Vector__XXX
 SG_ VCLEFT_frontSeatLiftPosReal m5 : 28|12@1- (1,0) [0|0] "" Vector__XXX
 SG_ VCLEFT_frontSeatBackCurrent m1 : 24|12@1- (0.01,0) [0|0] "" Vector__XXX
 SG_ VCLEFT_frontSeatLiftCurrent m2 : 24|12@1- (0.01,0) [0|0] "" Vector__XXX
 SG_ VCLEFT_frontSeatTiltCurrent m3 : 24|12@1- (0.01,0) [0|0] "" Vector__XXX
 SG_ VCLEFT_frontSeatTrackCurrent m0 : 24|12@1- (0.01,0) [0|0] "" Vector__XXX
 SG_ VCLEFT_lumbarAPressureHpaFilt m4 : 21|10@1+ (1,0) [0|0] "" Vector__XXX
 SG_ VCLEFT_frontSeatBackPosOffset m6 : 16|12@1- (0.1,0) [0|0] "" Vector__XXX
 SG_ VCLEFT_frontSeatBackPosReal m5 : 16|12@1- (0.1,0) [0|0] "" Vector__XXX
 SG_ VCLEFT_lumbarBPressurePercentage m7 : 10|7@1+ (1,0) [0|0] "" Vector__XXX
 SG_ VCLEFT_lumbarAPressureHpa m4 : 9|12@1+ (1,0) [0|0] "" Vector__XXX
 SG_ VCLEFT_frontSeatBackPos m1 : 8|16@1- (1,0) [0|0] "" Vector__XXX
 SG_ VCLEFT_frontSeatLiftPos m2 : 8|16@1- (1,0) [0|0] "" Vector__XXX
 SG_ VCLEFT_frontSeatTiltPos m3 : 8|16@1- (1,0) [0|0] "" Vector__XXX
 SG_ VCLEFT_frontSeatTrackPos m0 : 8|16@1- (1,0) [0|0] "" Vector__XXX
 SG_ VCLEFT_lumbarBState m4 : 6|3@1+ (1,0) [0|0] "" Vector__XXX
 SG_ VC_AH_1RowLeftSeatMovementHealth m0 : 5|3@1+ (1,0) [0|0] "" Vector__XXX
 SG_ VCLEFT_frontSeatTrackPosOffset m6 : 3|12@1- (1,0) [0|0] "" Vector__XXX
 SG_ VCLEFT_frontSeatTrackPosReal m5 : 3|12@1- (1,0) [0|0] "" Vector__XXX
 SG_ VCLEFT_lumbarAPressurePercentage m7 : 3|7@1+ (1,0) [0|0] "" Vector__XXX
 SG_ VCLEFT_lumbarAState m4 : 3|3@1+ (1,0) [0|0] "" Vector__XXX
 SG_ VCLEFT_seatStatusIndex M : 0|3@1+ (1,0) [0|0] "" Vector__XXX

BO_ 930 VCLEFT_status: 8 VEH
 SG_ VCLEFT_statusIndex M: 0|1@1+ (1,0) [0|0] "" X
 SG_ VCLEFT_loadShedPriority m0: 1|8@1+ (1,0) [0|0] "" X
 SG_ VCLEFT_vehiclePowerStateDBG m0: 9|2@1+ (1,0) [0|0] "" X
 SG_ VCLEFT_consoleDoorAssist m0: 11|1@1+ (1,0) [0|0] "" X
 SG_ VCLEFT_OTAState m0: 12|1@1+ (1,0) [0|0] "" X
 SG_ VCLEFT_5AVoltage m0: 13|10@1+ (0.00544368,0) [0|0] "V" X
 SG_ VCLEFT_vbatProt m0: 23|12@1+ (0.00544368,0) [0|0] "V" X
 SG_ VCLEFT_footwellLightCurrent m0: 35|12@1- (0.1,0) [0|0] "mA" X
 SG_ VCLEFT_swcInputVoltage m0: 47|8@1+ (0.1,0) [0|0] "V" X
 SG_ VCLEFT_swcPCBATemperature m0: 55|8@1- (1,-40) [0|0] "degC" X
 SG_ VCLEFT_pcbaTemperature m1: 1|11@1+ (0.125,-40) [0|0] "degC" X
 SG_ VCLEFT_DIeFuseCurrent m1: 12|12@1- (0.1,0) [0|0] "A" X
 SG_ VCLEFT_DIeFuseFault m1: 24|1@1+ (1,0) [0|0] "" X
 SG_ VCLEFT_tlcPCBATemperature m1: 32|8@1- (1,-40) [0|0] "degC" X

BO_ 610 VCLEFT_steeringColumnStatus: 8 Vector__XXX
 SG_ VCLEFT_steeringColumnInOutTC : 54|8@1+ (0.5,-10) [0|0] "" Vector__XXX
 SG_ VCLEFT_steeringColumnUpDownTC : 46|8@1+ (0.5,-10) [0|0] "" Vector__XXX
 SG_ VCLEFT_steeringColumnInOutCalib : 45|1@1+ (1,0) [0|0] "" Vector__XXX
 SG_ VCLEFT_steeringColumnUpDownCalib : 44|1@1+ (1,0) [0|0] "" Vector__XXX
 SG_ VCLEFT_steeringColumnInOutAmps : 38|6@1- (0.63,0) [0|0] "" Vector__XXX
 SG_ VCLEFT_steeringColumnUpDownAmps : 32|6@1- (0.63,0) [0|0] "" Vector__XXX
 SG_ VCLEFT_steeringColumnInOutPos : 24|8@1- (1,103) [0|0] "" Vector__XXX
 SG_ VCLEFT_steeringColumnUpDownPos : 16|8@1- (1,103) [0|0] "" Vector__XXX
 SG_ VCLEFT_steeringColumnInOutDuty : 11|5@1- (7,0) [0|0] "" Vector__XXX
 SG_ VCLEFT_steeringColumnUpDownDuty : 6|5@1- (7,0) [0|0] "" Vector__XXX
 SG_ VCLEFT_steeringColumnLastRequest : 3|3@1+ (1,0) [0|0] "" Vector__XXX
 SG_ VCLEFT_steeringColumnSMState : 0|2@1+ (1,0) [0|0] "" Vector__XXX

BO_ 962 VCLEFT_switchStatus: 8 VEH
 SG_ VCLEFT_switchStatusIndex M : 0|2@1+ (1,0) [0|2] "" X
 SG_ VCLEFT_2RowSeatBothFoldFlatSwitc m1 : 40|1@1+ (1,0) [0|1] "" X
 SG_ VCLEFT_2RowSeatCenterSwitch m1 : 37|1@1+ (1,0) [0|1] "" X
 SG_ VCLEFT_2RowSeatLeftFoldFlatSwitc m1 : 38|1@1+ (1,0) [0|1] "" X
 SG_ VCLEFT_2RowSeatReclineSwitch m1 : 36|1@1+ (1,0) [0|1] "" X
 SG_ VCLEFT_2RowSeatRightFoldFlatSwit m1 : 39|1@1+ (1,0) [0|1] "" X
 SG_ VCLEFT_brakePressed m0 : 60|1@1+ (1,0) [0|1] "" X
 SG_ VCLEFT_brakeSwitchPressed m0 : 4|1@1+ (1,0) [0|1] "" X
 SG_ VCLEFT_btnWindowAutoDownLR m1 : 35|1@1+ (1,0) [0|1] "" X
 SG_ VCLEFT_btnWindowAutoUpLR m1 : 33|1@1+ (1,0) [0|1] "" X
 SG_ VCLEFT_btnWindowDownLR m1 : 34|1@1+ (1,0) [0|1] "" X
 SG_ VCLEFT_btnWindowSwPackAutoDownLF m0 : 35|1@1+ (1,0) [0|1] "" X
 SG_ VCLEFT_btnWindowSwPackAutoDownLR m0 : 39|1@1+ (1,0) [0|1] "" X
 SG_ VCLEFT_btnWindowSwPackAutoDownRF m0 : 43|1@1+ (1,0) [0|1] "" X
 SG_ VCLEFT_btnWindowSwPackAutoDownRR m0 : 47|1@1+ (1,0) [0|1] "" X
 SG_ VCLEFT_btnWindowSwPackAutoUpLF m0 : 33|1@1+ (1,0) [0|1] "" X
 SG_ VCLEFT_btnWindowSwPackAutoUpLR m0 : 37|1@1+ (1,0) [0|1] "" X
 SG_ VCLEFT_btnWindowSwPackAutoUpRF m0 : 41|1@1+ (1,0) [0|1] "" X
 SG_ VCLEFT_btnWindowSwPackAutoUpRR m0 : 45|1@1+ (1,0) [0|1] "" X
 SG_ VCLEFT_btnWindowSwPackDownLF m0 : 34|1@1+ (1,0) [0|1] "" X
 SG_ VCLEFT_btnWindowSwPackDownLR m0 : 38|1@1+ (1,0) [0|1] "" X
 SG_ VCLEFT_btnWindowSwPackDownRF m0 : 42|1@1+ (1,0) [0|1] "" X
 SG_ VCLEFT_btnWindowSwPackDownRR m0 : 46|1@1+ (1,0) [0|1] "" X
 SG_ VCLEFT_btnWindowSwPackUpLF m0 : 32|1@1+ (1,0) [0|1] "" X
 SG_ VCLEFT_btnWindowSwPackUpLR m0 : 36|1@1+ (1,0) [0|1] "" X
 SG_ VCLEFT_btnWindowSwPackUpRF m0 : 40|1@1+ (1,0) [0|1] "" X
 SG_ VCLEFT_btnWindowSwPackUpRR m0 : 44|1@1+ (1,0) [0|1] "" X
 SG_ VCLEFT_btnWindowUpLR m1 : 32|1@1+ (1,0) [0|1] "" X
 SG_ VCLEFT_frontBuckleSwitch m0 : 48|2@1+ (1,0) [0|3] "" X
 SG_ VCLEFT_frontOccupancySwitch m0 : 50|2@1+ (1,0) [0|3] "" X
 SG_ VCLEFT_frontSeatBackrestBack m0 : 20|2@1+ (1,0) [0|3] "" X
 SG_ VCLEFT_frontSeatBackrestForward m0 : 22|2@1+ (1,0) [0|3] "" X
 SG_ VCLEFT_frontSeatLiftDown m0 : 16|2@1+ (1,0) [0|3] "" X
 SG_ VCLEFT_frontSeatLiftUp m0 : 18|2@1+ (1,0) [0|3] "" X
 SG_ VCLEFT_frontSeatLumbarDown m0 : 24|2@1+ (1,0) [0|3] "" X
 SG_ VCLEFT_frontSeatLumbarIn m0 : 28|2@1+ (1,0) [0|3] "" X
 SG_ VCLEFT_frontSeatLumbarOut m0 : 30|2@1+ (1,0) [0|3] "" X
 SG_ VCLEFT_frontSeatLumbarUp m0 : 26|2@1+ (1,0) [0|3] "" X
 SG_ VCLEFT_frontSeatTiltDown m0 : 12|2@1+ (1,0) [0|3] "" X
 SG_ VCLEFT_frontSeatTiltUp m0 : 14|2@1+ (1,0) [0|3] "" X
 SG_ VCLEFT_frontSeatTrackBack m0 : 8|2@1+ (1,0) [0|3] "" X
 SG_ VCLEFT_frontSeatTrackForward m0 : 10|2@1+ (1,0) [0|3] "" X
 SG_ VCLEFT_hazardButtonPressed m0 : 3|1@1+ (1,0) [0|1] "" X
 SG_ VCLEFT_hornSwitchPressed m0 : 2|1@1+ (1,0) [0|1] "" X
 SG_ VCLEFT_rearCenterBuckleSwitch m0 : 62|2@1+ (1,0) [0|3] "" X
 SG_ VCLEFT_rearCenterOccupancySwitch m0 : 54|2@1+ (1,0) [0|3] "" X
 SG_ VCLEFT_rearHVACButtonPressed m0 : 61|1@1+ (1,0) [0|1] "" X
 SG_ VCLEFT_rearLeftBuckleSwitch m0 : 52|2@1+ (1,0) [0|3] "" X
 SG_ VCLEFT_rearLeftOccupancySwitch m0 : 56|2@1+ (1,0) [0|3] "" X
 SG_ VCLEFT_rearRightOccupancySwitch m0 : 58|2@1+ (1,0) [0|3] "" X
 SG_ VCLEFT_rightMirrorTilt m0 : 5|3@1+ (1,0) [0|4] "" X
 SG_ VCLEFT_swcLeftDoublePress m1 : 41|1@1+ (1,0) [0|1] "" X
 SG_ VCLEFT_swcLeftPressed m1 : 5|2@1+ (1,0) [0|3] "" X
 SG_ VCLEFT_swcLeftScrollTicks m1 : 16|6@1- (1,0) [-32|31] "" X
 SG_ VCLEFT_swcLeftTiltLeft m1 : 14|2@1+ (1,0) [0|3] "" X
 SG_ VCLEFT_swcLeftTiltRight m1 : 3|2@1+ (1,0) [0|3] "" X
 SG_ VCLEFT_swcRightDoublePress m1 : 42|1@1+ (1,0) [0|1] "" X
 SG_ VCLEFT_swcRightPressed m1 : 12|2@1+ (1,0) [0|3] "" X
 SG_ VCLEFT_swcRightScrollTicks m1 : 24|6@1- (1,0) [-32|31] "" X
 SG_ VCLEFT_swcRightTiltLeft m1 : 8|2@1+ (1,0) [0|3] "" X
 SG_ VCLEFT_swcRightTiltRight m1 : 10|2@1+ (1,0) [0|3] "" X

BO_ 960 VCRIGHT_alertMatrix: 8 Vector__XXX
 SG_ VCRIGHT_a060_engineeringBuild m0 : 63|1@1+ (1,0) [0|0] "" Vector__XXX
 SG_ VCRIGHT_a120_DI_DRIVE_MIA m1 : 63|1@1+ (1,0) [0|0] "" Vector__XXX
 SG_ VCRIGHT_a180_frontDoorLatchRehom m2 : 63|1@1+ (1,0) [0|0] "" Vector__XXX
 SG_ VCRIGHT_a240_seatHeatShortFront m3 : 63|1@1+ (1,0) [0|0] "" Vector__XXX
 SG_ VCRIGHT_a360_detectedStationaryW m5 : 63|1@1+ (1,0) [0|0] "" Vector__XXX
 SG_ VCRIGHT_a540_hvacActuatorDitherD m8 : 63|1@1+ (1,0) [0|0] "" Vector__XXX
 SG_ VCRIGHT_a059_inputResistanceHigh m0 : 62|1@1+ (1,0) [0|0] "" Vector__XXX
 SG_ VCRIGHT_a119_SCCM_MIA m1 : 62|1@1+ (1,0) [0|0] "" Vector__XXX
 SG_ VCRIGHT_a179_trunkSwitchVCFRONTM m2 : 62|1@1+ (1,0) [0|0] "" Vector__XXX
 SG_ VCRIGHT_a239_seatHeatIFront m3 : 62|1@1+ (1,0) [0|0] "" Vector__XXX
 SG_ VCRIGHT_a299_buckleFaulted3RowR m4 : 62|1@1+ (1,0) [0|0] "" Vector__XXX
 SG_ VCRIGHT_a359_hvacUpperModeWarnin m5 : 62|1@1+ (1,0) [0|0] "" Vector__XXX
 SG_ VCRIGHT_a539_dogModeMonitorTrip m8 : 62|1@1+ (1,0) [0|0] "" Vector__XXX
 SG_ VCRIGHT_a599_LVBatteryTypeUnsupp m9 : 62|1@1+ (1,0) [0|0] "" Vector__XXX
 SG_ VCRIGHT_a058_inputRHighSyncDebug m0 : 61|1@1+ (1,0) [0|0] "" Vector__XXX
 SG_ VCRIGHT_a118_VCFRONT_MIA m1 : 61|1@1+ (1,0) [0|0] "" Vector__XXX
 SG_ VCRIGHT_a178_trunkSwitchVCBATTMI m2 : 61|1@1+ (1,0) [0|0] "" Vector__XXX
 SG_ VCRIGHT_a238_lumbarValveMIA m3 : 61|1@1+ (1,0) [0|0] "" Vector__XXX
 SG_ VCRIGHT_a298_buckleFaulted3RowL m4 : 61|1@1+ (1,0) [0|0] "" Vector__XXX
 SG_ VCRIGHT_a358_hvacRHVaneWarning m5 : 61|1@1+ (1,0) [0|0] "" Vector__XXX
 SG_ VCRIGHT_a538_hvacSystemNotNomina m8 : 61|1@1+ (1,0) [0|0] "" Vector__XXX
 SG_ VCRIGHT_a598_childModeMonitorTri m9 : 61|1@1+ (1,0) [0|0] "" Vector__XXX
 SG_ VCRIGHT_a057_HVP_MIA m0 : 60|1@1+ (1,0) [0|0] "" Vector__XXX
 SG_ VCRIGHT_a117_VCLEFT_MIA m1 : 60|1@1+ (1,0) [0|0] "" Vector__XXX
 SG_ VCRIGHT_a237_lumbarOverPresB m3 : 60|1@1+ (1,0) [0|0] "" Vector__XXX
 SG_ VCRIGHT_a297_seatBelowMinPumpTmp m4 : 60|1@1+ (1,0) [0|0] "" Vector__XXX
 SG_ VCRIGHT_a357_hvacLHVaneWarning m5 : 60|1@1+ (1,0) [0|0] "" Vector__XXX
 SG_ VCRIGHT_a537_solarCalcsNotNomina m8 : 60|1@1+ (1,0) [0|0] "" Vector__XXX
 SG_ VCRIGHT_a116_VCRIGHT_MIA m1 : 59|1@1+ (1,0) [0|0] "" Vector__XXX
 SG_ VCRIGHT_a176_windowSealDefectRea m2 : 59|1@1+ (1,0) [0|0] "" Vector__XXX
 SG_ VCRIGHT_a236_lumbarOverPresA m3 : 59|1@1+ (1,0) [0|0] "" Vector__XXX
 SG_ VCRIGHT_a296_occupancyFaulted3Ro m4 : 59|1@1+ (1,0) [0|0] "" Vector__XXX
 SG_ VCRIGHT_a356_hvacRHBleedWarning m5 : 59|1@1+ (1,0) [0|0] "" Vector__XXX
 SG_ VCRIGHT_a115_VCSEC_MIA m1 : 58|1@1+ (1,0) [0|0] "" Vector__XXX
 SG_ VCRIGHT_a175_windowSealDefectFro m2 : 58|1@1+ (1,0) [0|0] "" Vector__XXX
 SG_ VCRIGHT_a235_seatCurrUnderLift m3 : 58|1@1+ (1,0) [0|0] "" Vector__XXX
 SG_ VCRIGHT_a295_occupancyFaulted3Ro m4 : 58|1@1+ (1,0) [0|0] "" Vector__XXX
 SG_ VCRIGHT_a355_hvacLHBleedWarning m5 : 58|1@1+ (1,0) [0|0] "" Vector__XXX
 SG_ VCRIGHT_a114_ESP_MIA m1 : 57|1@1+ (1,0) [0|0] "" Vector__XXX
 SG_ VCRIGHT_a174_BLERightPowerCycled m2 : 57|1@1+ (1,0) [0|0] "" Vector__XXX
 SG_ VCRIGHT_a234_seatCurrUnderTilt m3 : 57|1@1+ (1,0) [0|0] "" Vector__XXX
 SG_ VCRIGHT_a294_occupancyFaultedRea m4 : 57|1@1+ (1,0) [0|0] "" Vector__XXX
 SG_ VCRIGHT_a113_UI_MIA m1 : 56|1@1+ (1,0) [0|0] "" Vector__XXX
 SG_ VCRIGHT_a173_windowBtnDoorOpen m2 : 56|1@1+ (1,0) [0|0] "" Vector__XXX
 SG_ VCRIGHT_a233_seatCurrUnderBack m3 : 56|1@1+ (1,0) [0|0] "" Vector__XXX
 SG_ VCRIGHT_a293_buckleFaultedRearR m4 : 56|1@1+ (1,0) [0|0] "" Vector__XXX
 SG_ VCRIGHT_a533_cabinModelDebug m8 : 56|1@1+ (1,0) [0|0] "" Vector__XXX
 SG_ VCRIGHT_a112_EPBL_MIA m1 : 55|1@1+ (1,0) [0|0] "" Vector__XXX
 SG_ VCRIGHT_a172_SPI_MIA m2 : 55|1@1+ (1,0) [0|0] "" Vector__XXX
 SG_ VCRIGHT_a232_seatCurrUnderTrack m3 : 55|1@1+ (1,0) [0|0] "" Vector__XXX
 SG_ VCRIGHT_a292_buckleFaultedRearC m4 : 55|1@1+ (1,0) [0|0] "" Vector__XXX
 SG_ VCRIGHT_a352_audioCurrentSpikeDa m5 : 55|1@1+ (1,0) [0|0] "" Vector__XXX
 SG_ VCRIGHT_a111_EPBR_MIA m1 : 54|1@1+ (1,0) [0|0] "" Vector__XXX
 SG_ VCRIGHT_a231_seatEncOverLift m3 : 54|1@1+ (1,0) [0|0] "" Vector__XXX
 SG_ VCRIGHT_a291_buckleFaultedFront m4 : 54|1@1+ (1,0) [0|0] "" Vector__XXX
 SG_ VCRIGHT_a110_GTW_MIA m1 : 53|1@1+ (1,0) [0|0] "" Vector__XXX
 SG_ VCRIGHT_a170_windowCurrentPeakR m2 : 53|1@1+ (1,0) [0|0] "" Vector__XXX
 SG_ VCRIGHT_a230_seatEncOverTilt m3 : 53|1@1+ (1,0) [0|0] "" Vector__XXX
 SG_ VCRIGHT_a290_occupancyFaultedFro m4 : 53|1@1+ (1,0) [0|0] "" Vector__XXX
 SG_ VCRIGHT_a109_RCM_MIA m1 : 52|1@1+ (1,0) [0|0] "" Vector__XXX
 SG_ VCRIGHT_a169_windowCurrentPeakF m2 : 52|1@1+ (1,0) [0|0] "" Vector__XXX
 SG_ VCRIGHT_a229_seatEncOverBack m3 : 52|1@1+ (1,0) [0|0] "" Vector__XXX
 SG_ VCRIGHT_a289_handlePWMPeriodR m4 : 52|1@1+ (1,0) [0|0] "" Vector__XXX
 SG_ VCRIGHT_a589_defogSysDriverlessS m9 : 52|1@1+ (1,0) [0|0] "" Vector__XXX
 SG_ VCRIGHT_a108_DIF_MIA m1 : 51|1@1+ (1,0) [0|0] "" Vector__XXX
 SG_ VCRIGHT_a168_windowDebugPinchR m2 : 51|1@1+ (1,0) [0|0] "" Vector__XXX
 SG_ VCRIGHT_a228_seatEncOverTrack m3 : 51|1@1+ (1,0) [0|0] "" Vector__XXX
 SG_ VCRIGHT_a288_handlePWMPeriodF m4 : 51|1@1+ (1,0) [0|0] "" Vector__XXX
 SG_ VCRIGHT_a528_unableToRunStuckOnT m8 : 51|1@1+ (1,0) [0|0] "" Vector__XXX
 SG_ VCRIGHT_a107_BMS_MIA m1 : 50|1@1+ (1,0) [0|0] "" Vector__XXX
 SG_ VCRIGHT_a167_windowDebugPinchF m2 : 50|1@1+ (1,0) [0|0] "" Vector__XXX
 SG_ VCRIGHT_a227_seatEncStallLift m3 : 50|1@1+ (1,0) [0|0] "" Vector__XXX
 SG_ VCRIGHT_a287_windowSpeedInvalidR m4 : 50|1@1+ (1,0) [0|0] "" Vector__XXX
 SG_ VCRIGHT_a347_nonContMonitorClear m5 : 50|1@1+ (1,0) [0|0] "" Vector__XXX
 SG_ VCRIGHT_a527_continuousFeedUnexp m8 : 50|1@1+ (1,0) [0|0] "" Vector__XXX
 SG_ VCRIGHT_a046_Task1000msError m0 : 49|1@1+ (1,0) [0|0] "" Vector__XXX
 SG_ VCRIGHT_a106_PCS_MIA m1 : 49|1@1+ (1,0) [0|0] "" Vector__XXX
 SG_ VCRIGHT_a166_windowDebug m2 : 49|1@1+ (1,0) [0|0] "" Vector__XXX
 SG_ VCRIGHT_a226_seatEncStallTilt m3 : 49|1@1+ (1,0) [0|0] "" Vector__XXX
 SG_ VCRIGHT_a286_windowSpeedInvalidF m4 : 49|1@1+ (1,0) [0|0] "" Vector__XXX
 SG_ VCRIGHT_a346_cabinRadarEFuseFaul m5 : 49|1@1+ (1,0) [0|0] "" Vector__XXX
 SG_ VCRIGHT_a526_pcbaOverTemperature m8 : 49|1@1+ (1,0) [0|0] "" Vector__XXX
 SG_ VCRIGHT_a586_doorRemoteUnlatchFa m9 : 49|1@1+ (1,0) [0|0] "" Vector__XXX
 SG_ VCRIGHT_a045_Task100msError m0 : 48|1@1+ (1,0) [0|0] "" Vector__XXX
 SG_ VCRIGHT_a105_TAS_MIA m1 : 48|1@1+ (1,0) [0|0] "" Vector__XXX
 SG_ VCRIGHT_a165_windowFactoryTest2 m2 : 48|1@1+ (1,0) [0|0] "" Vector__XXX
 SG_ VCRIGHT_a225_seatEncStallBack m3 : 48|1@1+ (1,0) [0|0] "" Vector__XXX
 SG_ VCRIGHT_a285_gloveboxOverCurrent m4 : 48|1@1+ (1,0) [0|0] "" Vector__XXX
 SG_ VCRIGHT_a345_HVACPTCHeaterPwrEFu m5 : 48|1@1+ (1,0) [0|0] "" Vector__XXX
 SG_ VCRIGHT_a525_LVBatterySWMisconfi m8 : 48|1@1+ (1,0) [0|0] "" Vector__XXX
 SG_ VCRIGHT_a585_doorRemoteUnlatchFa m9 : 48|1@1+ (1,0) [0|0] "" Vector__XXX
 SG_ VCRIGHT_a044_Task10msError m0 : 47|1@1+ (1,0) [0|0] "" Vector__XXX
 SG_ VCRIGHT_a104_DAS_MIA m1 : 47|1@1+ (1,0) [0|0] "" Vector__XXX
 SG_ VCRIGHT_a164_windowFactoryTest m2 : 47|1@1+ (1,0) [0|0] "" Vector__XXX
 SG_ VCRIGHT_a224_seatEncStallTrack m3 : 47|1@1+ (1,0) [0|0] "" Vector__XXX
 SG_ VCRIGHT_a284_gloveboxUnderCurren m4 : 47|1@1+ (1,0) [0|0] "" Vector__XXX
 SG_ VCRIGHT_a344_rearDefrostOvercurr m5 : 47|1@1+ (1,0) [0|0] "" Vector__XXX
 SG_ VCRIGHT_a584_doorRemoteUnlatched m9 : 47|1@1+ (1,0) [0|0] "" Vector__XXX
 SG_ VCRIGHT_a043_Task1msError m0 : 46|1@1+ (1,0) [0|0] "" Vector__XXX
 SG_ VCRIGHT_a103_CP_MIA m1 : 46|1@1+ (1,0) [0|0] "" Vector__XXX
 SG_ VCRIGHT_a163_windowEncoderStallR m2 : 46|1@1+ (1,0) [0|0] "" Vector__XXX
 SG_ VCRIGHT_a283_latchUnexpectedArmR m4 : 46|1@1+ (1,0) [0|0] "" Vector__XXX
 SG_ VCRIGHT_a343_rearDefrostUndercur m5 : 46|1@1+ (1,0) [0|0] "" Vector__XXX
 SG_ VCRIGHT_a583_doorRemoteUnlatched m9 : 46|1@1+ (1,0) [0|0] "" Vector__XXX
 SG_ VCRIGHT_a042_HighStackUsage m0 : 45|1@1+ (1,0) [0|0] "" Vector__XXX
 SG_ VCRIGHT_a102_PTC_MIA m1 : 45|1@1+ (1,0) [0|0] "" Vector__XXX
 SG_ VCRIGHT_a162_windowEncoderStallF m2 : 45|1@1+ (1,0) [0|0] "" Vector__XXX
 SG_ VCRIGHT_a282_latchUnexpectedArmF m4 : 45|1@1+ (1,0) [0|0] "" Vector__XXX
 SG_ VCRIGHT_a342_rearDefrostDisabled m5 : 45|1@1+ (1,0) [0|0] "" Vector__XXX
 SG_ VCRIGHT_a041_HighCPULoad m0 : 44|1@1+ (1,0) [0|0] "" Vector__XXX
 SG_ VCRIGHT_a101_PM_MIA m1 : 44|1@1+ (1,0) [0|0] "" Vector__XXX
 SG_ VCRIGHT_a161_windowUndercurrentR m2 : 44|1@1+ (1,0) [0|0] "" Vector__XXX
 SG_ VCRIGHT_a281_latchDidNotDisarmR m4 : 44|1@1+ (1,0) [0|0] "" Vector__XXX
 SG_ VCRIGHT_a100_CANbus_MIA m1 : 43|1@1+ (1,0) [0|0] "" Vector__XXX
 SG_ VCRIGHT_a160_windowUndercurrentF m2 : 43|1@1+ (1,0) [0|0] "" Vector__XXX
 SG_ VCRIGHT_a280_latchDidNotDisarmF m4 : 43|1@1+ (1,0) [0|0] "" Vector__XXX
 SG_ VCRIGHT_a520_configMismatch m8 : 43|1@1+ (1,0) [0|0] "" Vector__XXX
 SG_ VCRIGHT_a099_PARK_MIA m1 : 42|1@1+ (1,0) [0|0] "" Vector__XXX
 SG_ VCRIGHT_a159_windowPinchOverideR m2 : 42|1@1+ (1,0) [0|0] "" Vector__XXX
 SG_ VCRIGHT_a219_motorCurrentDropout m3 : 42|1@1+ (1,0) [0|0] "" Vector__XXX
 SG_ VCRIGHT_a279_trunkFailedToClose m4 : 42|1@1+ (1,0) [0|0] "" Vector__XXX
 SG_ VCRIGHT_a098_DIR_MIA m1 : 41|1@1+ (1,0) [0|0] "" Vector__XXX
 SG_ VCRIGHT_a158_windowPinchOverideF m2 : 41|1@1+ (1,0) [0|0] "" Vector__XXX
 SG_ VCRIGHT_a218_motorDriverFault m3 : 41|1@1+ (1,0) [0|0] "" Vector__XXX
 SG_ VCRIGHT_a278_hvacPtcHeatingUnava m4 : 41|1@1+ (1,0) [0|0] "" Vector__XXX
 SG_ VCRIGHT_a097_CMP_MIA m1 : 40|1@1+ (1,0) [0|0] "" Vector__XXX
 SG_ VCRIGHT_a157_windowNoInputRear m2 : 40|1@1+ (1,0) [0|0] "" Vector__XXX
 SG_ VCRIGHT_a217_SPI_MIA_debugData2 m3 : 40|1@1+ (1,0) [0|0] "" Vector__XXX
 SG_ VCRIGHT_a277_BLERightUnderVoltag m4 : 40|1@1+ (1,0) [0|0] "" Vector__XXX
 SG_ VCRIGHT_a337_windowDropRevTherma m5 : 40|1@1+ (1,0) [0|0] "" Vector__XXX
 SG_ VCRIGHT_a096_OCS1P_MIA m1 : 39|1@1+ (1,0) [0|0] "" Vector__XXX
 SG_ VCRIGHT_a156_windowNoInputFront m2 : 39|1@1+ (1,0) [0|0] "" Vector__XXX
 SG_ VCRIGHT_a216_SPI_MIA_debugData1 m3 : 39|1@1+ (1,0) [0|0] "" Vector__XXX
 SG_ VCRIGHT_a276_mirrorDebug m4 : 39|1@1+ (1,0) [0|0] "" Vector__XXX
 SG_ VCRIGHT_a336_windowDropRevTherma m5 : 39|1@1+ (1,0) [0|0] "" Vector__XXX
 SG_ VCRIGHT_a095_CHG_MIA m1 : 38|1@1+ (1,0) [0|0] "" Vector__XXX
 SG_ VCRIGHT_a155_windowThermalRear m2 : 38|1@1+ (1,0) [0|0] "" Vector__XXX
 SG_ VCRIGHT_a215_currentDesyncWarnin m3 : 38|1@1+ (1,0) [0|0] "" Vector__XXX
 SG_ VCRIGHT_a275_rightTurnLightFault m4 : 38|1@1+ (1,0) [0|0] "" Vector__XXX
 SG_ VCRIGHT_a094_EPAS3P_MIA m1 : 37|1@1+ (1,0) [0|0] "" Vector__XXX
 SG_ VCRIGHT_a154_windowThermalFront m2 : 37|1@1+ (1,0) [0|0] "" Vector__XXX
 SG_ VCRIGHT_a214_epbmOverIDynNew m3 : 37|1@1+ (1,0) [0|0] "" Vector__XXX
 SG_ VCRIGHT_a274_handleStuckActiveR m4 : 37|1@1+ (1,0) [0|0] "" Vector__XXX
 SG_ VCRIGHT_a454_ptcHeaterBadRodDete m7 : 37|1@1+ (1,0) [0|0] "" Vector__XXX
 SG_ VCRIGHT_a093_VCSEATP_MIA m1 : 36|1@1+ (1,0) [0|0] "" Vector__XXX
 SG_ VCRIGHT_a153_windowUncalRear m2 : 36|1@1+ (1,0) [0|0] "" Vector__XXX
 SG_ VCRIGHT_a213_epbmUnderIDynNew m3 : 36|1@1+ (1,0) [0|0] "" Vector__XXX
 SG_ VCRIGHT_a273_handleStuckActiveF m4 : 36|1@1+ (1,0) [0|0] "" Vector__XXX
 SG_ VCRIGHT_a573_seatHeatDisabledRea m9 : 36|1@1+ (1,0) [0|0] "" Vector__XXX
 SG_ VCRIGHT_a092_VCSEATD_MIA m1 : 35|1@1+ (1,0) [0|0] "" Vector__XXX
 SG_ VCRIGHT_a152_windowUncalFront m2 : 35|1@1+ (1,0) [0|0] "" Vector__XXX
 SG_ VCRIGHT_a212_epbmOverIStaticNew m3 : 35|1@1+ (1,0) [0|0] "" Vector__XXX
 SG_ VCRIGHT_a272_vhclPwrStateMsmtch m4 : 35|1@1+ (1,0) [0|0] "" Vector__XXX
 SG_ VCRIGHT_a572_seatHeatDisabledRea m9 : 35|1@1+ (1,0) [0|0] "" Vector__XXX
 SG_ VCRIGHT_a031_UDSActive m0 : 34|1@1+ (1,0) [0|0] "" Vector__XXX
 SG_ VCRIGHT_a091_CMPD_MIA m1 : 34|1@1+ (1,0) [0|0] "" Vector__XXX
 SG_ VCRIGHT_a151_windowPinchRear m2 : 34|1@1+ (1,0) [0|0] "" Vector__XXX
 SG_ VCRIGHT_a211_epbmUnderIStaticNew m3 : 34|1@1+ (1,0) [0|0] "" Vector__XXX
 SG_ VCRIGHT_a271_THSSensorFault m4 : 34|1@1+ (1,0) [0|0] "" Vector__XXX
 SG_ VCRIGHT_a331_shortDropFailedR m5 : 34|1@1+ (1,0) [0|0] "" Vector__XXX
 SG_ VCRIGHT_a451_ptcSeqRodOutOfRetri m7 : 34|1@1+ (1,0) [0|0] "" Vector__XXX
 SG_ VCRIGHT_a571_seatHeatDisabledRea m9 : 34|1@1+ (1,0) [0|0] "" Vector__XXX
 SG_ VCRIGHT_a030_ECULogUploadRequest m0 : 33|1@1+ (1,0) [0|0] "" Vector__XXX
 SG_ VCRIGHT_a090_APS_MIA m1 : 33|1@1+ (1,0) [0|0] "" Vector__XXX
 SG_ VCRIGHT_a150_windowPinchFront m2 : 33|1@1+ (1,0) [0|0] "" Vector__XXX
 SG_ VCRIGHT_a210_epbStateTime m3 : 33|1@1+ (1,0) [0|0] "" Vector__XXX
 SG_ VCRIGHT_a270_seatLiftHCEncStlDbg m4 : 33|1@1+ (1,0) [0|0] "" Vector__XXX
 SG_ VCRIGHT_a330_shortDropFailedF m5 : 33|1@1+ (1,0) [0|0] "" Vector__XXX
 SG_ VCRIGHT_a450_ptcForcedOutOfSeqRo m7 : 33|1@1+ (1,0) [0|0] "" Vector__XXX
 SG_ VCRIGHT_a570_seatHeatDisabledF m9 : 33|1@1+ (1,0) [0|0] "" Vector__XXX
 SG_ VCRIGHT_a029_CoreDump m0 : 32|1@1+ (1,0) [0|0] "" Vector__XXX
 SG_ VCRIGHT_a089_IBST_MIA m1 : 32|1@1+ (1,0) [0|0] "" Vector__XXX
 SG_ VCRIGHT_a149_incarDeepTempSns m2 : 32|1@1+ (1,0) [0|0] "" Vector__XXX
 SG_ VCRIGHT_a209_epbStateMisTime m3 : 32|1@1+ (1,0) [0|0] "" Vector__XXX
 SG_ VCRIGHT_a269_seatTiltHCEncStlDbg m4 : 32|1@1+ (1,0) [0|0] "" Vector__XXX
 SG_ VCRIGHT_a088_DIRER_MIA m1 : 31|1@1+ (1,0) [0|0] "" Vector__XXX
 SG_ VCRIGHT_a148_incarMidTempSns m2 : 31|1@1+ (1,0) [0|0] "" Vector__XXX
 SG_ VCRIGHT_a208_epbFaulted m3 : 31|1@1+ (1,0) [0|0] "" Vector__XXX
 SG_ VCRIGHT_a268_seatBackHCEncStlDbg m4 : 31|1@1+ (1,0) [0|0] "" Vector__XXX
 SG_ VCRIGHT_a448_manualHVACAlert m7 : 31|1@1+ (1,0) [0|0] "" Vector__XXX
 SG_ VCRIGHT_a087_DIREL_MIA m1 : 30|1@1+ (1,0) [0|0] "" Vector__XXX
 SG_ VCRIGHT_a147_incarProbeTempSns m2 : 30|1@1+ (1,0) [0|0] "" Vector__XXX
 SG_ VCRIGHT_a207_epbmEnableWrong m3 : 30|1@1+ (1,0) [0|0] "" Vector__XXX
 SG_ VCRIGHT_a267_seatTrackHCEncStlDb m4 : 30|1@1+ (1,0) [0|0] "" Vector__XXX
 SG_ VCRIGHT_a086_VCBATT_MIA m1 : 29|1@1+ (1,0) [0|0] "" Vector__XXX
 SG_ VCRIGHT_a146_ductRightTempSns m2 : 29|1@1+ (1,0) [0|0] "" Vector__XXX
 SG_ VCRIGHT_a206_epbWrongDirection m3 : 29|1@1+ (1,0) [0|0] "" Vector__XXX
 SG_ VCRIGHT_a266_seatLiftStallDebug m4 : 29|1@1+ (1,0) [0|0] "" Vector__XXX
 SG_ VCRIGHT_a446_cabinHVACUnavailabl m7 : 29|1@1+ (1,0) [0|0] "" Vector__XXX
 SG_ VCRIGHT_a085_CCCM_MIA m1 : 28|1@1+ (1,0) [0|0] "" Vector__XXX
 SG_ VCRIGHT_a145_ductLeftTempSns m2 : 28|1@1+ (1,0) [0|0] "" Vector__XXX
 SG_ VCRIGHT_a205_epbmOverIDyn m3 : 28|1@1+ (1,0) [0|0] "" Vector__XXX
 SG_ VCRIGHT_a265_seatTiltStallDebug m4 : 28|1@1+ (1,0) [0|0] "" Vector__XXX
 SG_ VCRIGHT_a445_drv8703SpiFaultDBG m7 : 28|1@1+ (1,0) [0|0] "" Vector__XXX
 SG_ VCRIGHT_a084_TPMS_MIA m1 : 27|1@1+ (1,0) [0|0] "" Vector__XXX
 SG_ VCRIGHT_a144_evaporatorTempSns m2 : 27|1@1+ (1,0) [0|0] "" Vector__XXX
 SG_ VCRIGHT_a204_epbmUnderIDyn m3 : 27|1@1+ (1,0) [0|0] "" Vector__XXX
 SG_ VCRIGHT_a264_seatBackStallDebug m4 : 27|1@1+ (1,0) [0|0] "" Vector__XXX
 SG_ VCRIGHT_a324_mirrorHeatFault m5 : 27|1@1+ (1,0) [0|0] "" Vector__XXX
 SG_ VCRIGHT_a444_drv8703Fault m7 : 27|1@1+ (1,0) [0|0] "" Vector__XXX
 SG_ VCRIGHT_a083_VCLEFT_IPC_MIA m1 : 26|1@1+ (1,0) [0|0] "" Vector__XXX
 SG_ VCRIGHT_a143_mirrorManuallyFolde m2 : 26|1@1+ (1,0) [0|0] "" Vector__XXX
 SG_ VCRIGHT_a203_epbmOverIStatic m3 : 26|1@1+ (1,0) [0|0] "" Vector__XXX
 SG_ VCRIGHT_a263_seatTrackStallDebug m4 : 26|1@1+ (1,0) [0|0] "" Vector__XXX
 SG_ VCRIGHT_a323_mirrorCalibrated m5 : 26|1@1+ (1,0) [0|0] "" Vector__XXX
 SG_ VCRIGHT_a022_TaskInitError m0 : 25|1@1+ (1,0) [0|0] "" Vector__XXX
 SG_ VCRIGHT_a082_VCRIGHT_IPC_MIA m1 : 25|1@1+ (1,0) [0|0] "" Vector__XXX
 SG_ VCRIGHT_a142_hvacLowerModeFault m2 : 25|1@1+ (1,0) [0|0] "" Vector__XXX
 SG_ VCRIGHT_a202_epbmUnderIStatic m3 : 25|1@1+ (1,0) [0|0] "" Vector__XXX
 SG_ VCRIGHT_a262_PTCFaulted m4 : 25|1@1+ (1,0) [0|0] "" Vector__XXX
 SG_ VCRIGHT_a322_windowRezeroedDebug m5 : 25|1@1+ (1,0) [0|0] "" Vector__XXX
 SG_ VCRIGHT_a382_leftLiftgateTailLig m6 : 25|1@1+ (1,0) [0|0] "" Vector__XXX
 SG_ VCRIGHT_a021_TaskSchedulerError m0 : 24|1@1+ (1,0) [0|0] "" Vector__XXX
 SG_ VCRIGHT_a141_hvacUpperModeFault m2 : 24|1@1+ (1,0) [0|0] "" Vector__XXX
 SG_ VCRIGHT_a201_motorDutyEncDisabl m3 : 24|1@1+ (1,0) [0|0] "" Vector__XXX
 SG_ VCRIGHT_a261_emergencyLatchRelRe m4 : 24|1@1+ (1,0) [0|0] "" Vector__XXX
 SG_ VCRIGHT_a321_windowRezeroedDebug m5 : 24|1@1+ (1,0) [0|0] "" Vector__XXX
 SG_ VCRIGHT_a381_rearFogLightFault m6 : 24|1@1+ (1,0) [0|0] "" Vector__XXX
 SG_ VCRIGHT_a140_hvacRHVaneFault m2 : 23|1@1+ (1,0) [0|0] "" Vector__XXX
 SG_ VCRIGHT_a200_motorPhantomEncoder m3 : 23|1@1+ (1,0) [0|0] "" Vector__XXX
 SG_ VCRIGHT_a260_latchDisarmDelayR m4 : 23|1@1+ (1,0) [0|0] "" Vector__XXX
 SG_ VCRIGHT_a320_windowReportCracked m5 : 23|1@1+ (1,0) [0|0] "" Vector__XXX
 SG_ VCRIGHT_a380_reverseLightFault m6 : 23|1@1+ (1,0) [0|0] "" Vector__XXX
 SG_ VCRIGHT_a139_hvacLHVaneFault m2 : 22|1@1+ (1,0) [0|0] "" Vector__XXX
 SG_ VCRIGHT_a199_PRVCANUndertrminate m3 : 22|1@1+ (1,0) [0|0] "" Vector__XXX
 SG_ VCRIGHT_a259_latchDisarmDelayF m4 : 22|1@1+ (1,0) [0|0] "" Vector__XXX
 SG_ VCRIGHT_a319_rightExteriorTrunkL m5 : 22|1@1+ (1,0) [0|0] "" Vector__XXX
 SG_ VCRIGHT_a379_ductRightUpperTempS m6 : 22|1@1+ (1,0) [0|0] "" Vector__XXX
 SG_ VCRIGHT_a499_epbmInvalidateCdp m8 : 22|1@1+ (1,0) [0|0] "" Vector__XXX
 SG_ VCRIGHT_a138_hvacRHBleedFault m2 : 21|1@1+ (1,0) [0|0] "" Vector__XXX
 SG_ VCRIGHT_a198_PRVCANOverterminate m3 : 21|1@1+ (1,0) [0|0] "" Vector__XXX
 SG_ VCRIGHT_a258_PTCStuckInBoot m4 : 21|1@1+ (1,0) [0|0] "" Vector__XXX
 SG_ VCRIGHT_a318_leftExteriorTrunkLi m5 : 21|1@1+ (1,0) [0|0] "" Vector__XXX
 SG_ VCRIGHT_a378_ductLeftUpperTempSn m6 : 21|1@1+ (1,0) [0|0] "" Vector__XXX
 SG_ VCRIGHT_a017_NVMMStatusDbg m0 : 20|1@1+ (1,0) [0|0] "" Vector__XXX
 SG_ VCRIGHT_a137_hvacLHBleedFault m2 : 20|1@1+ (1,0) [0|0] "" Vector__XXX
 SG_ VCRIGHT_a197_VEHCANUndertrminate m3 : 20|1@1+ (1,0) [0|0] "" Vector__XXX
 SG_ VCRIGHT_a257_THSMIA m4 : 20|1@1+ (1,0) [0|0] "" Vector__XXX
 SG_ VCRIGHT_a317_epbmLimpModeEnabled m5 : 20|1@1+ (1,0) [0|0] "" Vector__XXX
 SG_ VCRIGHT_a377_ambientTempSns m6 : 20|1@1+ (1,0) [0|0] "" Vector__XXX
 SG_ VCRIGHT_a617_APP_MIA m10 : 20|1@1+ (1,0) [0|0] "" Vector__XXX
 SG_ VCRIGHT_a016_NVMMRecordError m0 : 19|1@1+ (1,0) [0|0] "" Vector__XXX
 SG_ VCRIGHT_a136_hvacIntakeFault m2 : 19|1@1+ (1,0) [0|0] "" Vector__XXX
 SG_ VCRIGHT_a196_VEHCANOverterminate m3 : 19|1@1+ (1,0) [0|0] "" Vector__XXX
 SG_ VCRIGHT_a256_PTCCurrentDrawNoReq m4 : 19|1@1+ (1,0) [0|0] "" Vector__XXX
 SG_ VCRIGHT_a316_mirrorPrematureFold m5 : 19|1@1+ (1,0) [0|0] "" Vector__XXX
 SG_ VCRIGHT_a376_seat2RowBridgeCurre m6 : 19|1@1+ (1,0) [0|0] "" Vector__XXX
 SG_ VCRIGHT_a496_gloveboxOpenFailed m8 : 19|1@1+ (1,0) [0|0] "" Vector__XXX
 SG_ VCRIGHT_a556_rcmReportedOCSError m9 : 19|1@1+ (1,0) [0|0] "" Vector__XXX
 SG_ VCRIGHT_a015_NVMMError m0 : 18|1@1+ (1,0) [0|0] "" Vector__XXX
 SG_ VCRIGHT_a135_hvacLowrModeUncalib m2 : 18|1@1+ (1,0) [0|0] "" Vector__XXX
 SG_ VCRIGHT_a195_hvcEFuseFault m3 : 18|1@1+ (1,0) [0|0] "" Vector__XXX
 SG_ VCRIGHT_a255_PTCOverTemp m4 : 18|1@1+ (1,0) [0|0] "" Vector__XXX
 SG_ VCRIGHT_a315_rightInteriorTrunkL m5 : 18|1@1+ (1,0) [0|0] "" Vector__XXX
 SG_ VCRIGHT_a375_windowPinchOverride m6 : 18|1@1+ (1,0) [0|0] "" Vector__XXX
 SG_ VCRIGHT_a555_RCM2_MIA m9 : 18|1@1+ (1,0) [0|0] "" Vector__XXX
 SG_ VCRIGHT_a134_hvacUpprModeUncalib m2 : 17|1@1+ (1,0) [0|0] "" Vector__XXX
 SG_ VCRIGHT_a194_cntctrPwrEFuseFault m3 : 17|1@1+ (1,0) [0|0] "" Vector__XXX
 SG_ VCRIGHT_a254_seatUncalLift m4 : 17|1@1+ (1,0) [0|0] "" Vector__XXX
 SG_ VCRIGHT_a314_rightMapPocketLight m5 : 17|1@1+ (1,0) [0|0] "" Vector__XXX
 SG_ VCRIGHT_a013_AlertManagerFault m0 : 16|1@1+ (1,0) [0|0] "" Vector__XXX
 SG_ VCRIGHT_a133_hvacRHVaneUncalib m2 : 16|1@1+ (1,0) [0|0] "" Vector__XXX
 SG_ VCRIGHT_a193_amplifierEFuseFault m3 : 16|1@1+ (1,0) [0|0] "" Vector__XXX
 SG_ VCRIGHT_a253_seatUncalTilt m4 : 16|1@1+ (1,0) [0|0] "" Vector__XXX
 SG_ VCRIGHT_a313_rightFootwellLightF m5 : 16|1@1+ (1,0) [0|0] "" Vector__XXX
 SG_ VCRIGHT_a373_windowSwOpenReqInDo m6 : 16|1@1+ (1,0) [0|0] "" Vector__XXX
 SG_ VCRIGHT_a012_CPUReset m0 : 15|1@1+ (1,0) [0|0] "" Vector__XXX
 SG_ VCRIGHT_a132_hvacLHVaneUncalib m2 : 15|1@1+ (1,0) [0|0] "" Vector__XXX
 SG_ VCRIGHT_a192_gloveboxLatchRel m3 : 15|1@1+ (1,0) [0|0] "" Vector__XXX
 SG_ VCRIGHT_a252_seatUncalBack m4 : 15|1@1+ (1,0) [0|0] "" Vector__XXX
 SG_ VCRIGHT_a312_rightTailLightFault m5 : 15|1@1+ (1,0) [0|0] "" Vector__XXX
 SG_ VCRIGHT_a372_seat2RowBackrestUnl m6 : 15|1@1+ (1,0) [0|0] "" Vector__XXX
 SG_ VCRIGHT_a131_hvacRHBleedUncalib m2 : 14|1@1+ (1,0) [0|0] "" Vector__XXX
 SG_ VCRIGHT_a191_gloveboxPower m3 : 14|1@1+ (1,0) [0|0] "" Vector__XXX
 SG_ VCRIGHT_a251_seatUncalTrack m4 : 14|1@1+ (1,0) [0|0] "" Vector__XXX
 SG_ VCRIGHT_a311_rightBrakeLightFaul m5 : 14|1@1+ (1,0) [0|0] "" Vector__XXX
 SG_ VCRIGHT_a371_seat2RowTrackUnlatc m6 : 14|1@1+ (1,0) [0|0] "" Vector__XXX
 SG_ VCRIGHT_a491_BPillarCameraHeater m8 : 14|1@1+ (1,0) [0|0] "" Vector__XXX
 SG_ VCRIGHT_a551_interiorDoorRequest m9 : 14|1@1+ (1,0) [0|0] "" Vector__XXX
 SG_ VCRIGHT_a010_ExtSupplyVoltError m0 : 13|1@1+ (1,0) [0|0] "" Vector__XXX
 SG_ VCRIGHT_a130_hvacLHBleedUncalib m2 : 13|1@1+ (1,0) [0|0] "" Vector__XXX
 SG_ VCRIGHT_a190_eFuseMgmtVbatFused m3 : 13|1@1+ (1,0) [0|0] "" Vector__XXX
 SG_ VCRIGHT_a250_seatHeatMIARearR m4 : 13|1@1+ (1,0) [0|0] "" Vector__XXX
 SG_ VCRIGHT_a310_mirrorFoldStall m5 : 13|1@1+ (1,0) [0|0] "" Vector__XXX
 SG_ VCRIGHT_a370_seat2RowPitchUnlatc m6 : 13|1@1+ (1,0) [0|0] "" Vector__XXX
 SG_ VCRIGHT_a490_vehicleOccupiedOnOT m8 : 13|1@1+ (1,0) [0|0] "" Vector__XXX
 SG_ VCRIGHT_a550_ambientTempDelta m9 : 13|1@1+ (1,0) [0|0] "" Vector__XXX
 SG_ VCRIGHT_a129_hvacIntakeUncalib m2 : 12|1@1+ (1,0) [0|0] "" Vector__XXX
 SG_ VCRIGHT_a189_latchUnableToRearmR m3 : 12|1@1+ (1,0) [0|0] "" Vector__XXX
 SG_ VCRIGHT_a249_seatHeatShortRearR m4 : 12|1@1+ (1,0) [0|0] "" Vector__XXX
 SG_ VCRIGHT_a369_ductRightLowerTempS m6 : 12|1@1+ (1,0) [0|0] "" Vector__XXX
 SG_ VCRIGHT_a429_seatAbuseBufferFull m7 : 12|1@1+ (1,0) [0|0] "" Vector__XXX
 SG_ VCRIGHT_a128_hvacActDrvFaultDBG m2 : 11|1@1+ (1,0) [0|0] "" Vector__XXX
 SG_ VCRIGHT_a188_latchUnableToRearmF m3 : 11|1@1+ (1,0) [0|0] "" Vector__XXX
 SG_ VCRIGHT_a248_seatHeatIRearR m4 : 11|1@1+ (1,0) [0|0] "" Vector__XXX
 SG_ VCRIGHT_a368_ductLeftLowerTempSn m6 : 11|1@1+ (1,0) [0|0] "" Vector__XXX
 SG_ VCRIGHT_a428_seatAbuseBufferWarn m7 : 11|1@1+ (1,0) [0|0] "" Vector__XXX
 SG_ VCRIGHT_a127_hvacActOvercurrentD m2 : 10|1@1+ (1,0) [0|0] "" Vector__XXX
 SG_ VCRIGHT_a187_latchReleaseFailedR m3 : 10|1@1+ (1,0) [0|0] "" Vector__XXX
 SG_ VCRIGHT_a247_seatHeatMIARearC m4 : 10|1@1+ (1,0) [0|0] "" Vector__XXX
 SG_ VCRIGHT_a307_handleDisconnectedR m5 : 10|1@1+ (1,0) [0|0] "" Vector__XXX
 SG_ VCRIGHT_a367_trunkLatchSwFault m6 : 10|1@1+ (1,0) [0|0] "" Vector__XXX
 SG_ VCRIGHT_a427_seatAbuseMotorStop m7 : 10|1@1+ (1,0) [0|0] "" Vector__XXX
 SG_ VCRIGHT_a006_CANTX_cyclicError m0 : 9|1@1+ (1,0) [0|0] "" Vector__XXX
 SG_ VCRIGHT_a066_emiosIsrShortPeriod m1 : 9|1@1+ (1,0) [0|0] "" Vector__XXX
 SG_ VCRIGHT_a126_hvacActOpenLoadDBG m2 : 9|1@1+ (1,0) [0|0] "" Vector__XXX
 SG_ VCRIGHT_a186_latchReleaseFailedF m3 : 9|1@1+ (1,0) [0|0] "" Vector__XXX
 SG_ VCRIGHT_a246_seatHeatShortRearC m4 : 9|1@1+ (1,0) [0|0] "" Vector__XXX
 SG_ VCRIGHT_a306_handleDisconnectedF m5 : 9|1@1+ (1,0) [0|0] "" Vector__XXX
 SG_ VCRIGHT_a366_trunkLatchUnhomed m6 : 9|1@1+ (1,0) [0|0] "" Vector__XXX
 SG_ VCRIGHT_a426_seatAbuseMotorWarn m7 : 9|1@1+ (1,0) [0|0] "" Vector__XXX
 SG_ VCRIGHT_a486_rightTailLightFault m8 : 9|1@1+ (1,0) [0|0] "" Vector__XXX
 SG_ VCRIGHT_a546_mirrorFoldTypeChang m9 : 9|1@1+ (1,0) [0|0] "" Vector__XXX
 SG_ VCRIGHT_a005_CANTXError m0 : 8|1@1+ (1,0) [0|0] "" Vector__XXX
 SG_ VCRIGHT_a065_emiosIsrRateLimited m1 : 8|1@1+ (1,0) [0|0] "" Vector__XXX
 SG_ VCRIGHT_a185_summonAborted m3 : 8|1@1+ (1,0) [0|0] "" Vector__XXX
 SG_ VCRIGHT_a245_seatHeatIRearC m4 : 8|1@1+ (1,0) [0|0] "" Vector__XXX
 SG_ VCRIGHT_a305_rearIntHandleUnexpe m5 : 8|1@1+ (1,0) [0|0] "" Vector__XXX
 SG_ VCRIGHT_a365_pitchUnlatchDisable m6 : 8|1@1+ (1,0) [0|0] "" Vector__XXX
 SG_ VCRIGHT_a545_LVBatteryTypeUnknow m9 : 8|1@1+ (1,0) [0|0] "" Vector__XXX
 SG_ VCRIGHT_a064_busSleepReqTimeout m1 : 7|1@1+ (1,0) [0|0] "" Vector__XXX
 SG_ VCRIGHT_a184_trunkFailedOpening m3 : 7|1@1+ (1,0) [0|0] "" Vector__XXX
 SG_ VCRIGHT_a244_seatHeatMIARearL m4 : 7|1@1+ (1,0) [0|0] "" Vector__XXX
 SG_ VCRIGHT_a304_frontIntHandleUnexp m5 : 7|1@1+ (1,0) [0|0] "" Vector__XXX
 SG_ VCRIGHT_a364_hvacIntakeWarning m6 : 7|1@1+ (1,0) [0|0] "" Vector__XXX
 SG_ VCRIGHT_a484_rightBrakeLightFaul m8 : 7|1@1+ (1,0) [0|0] "" Vector__XXX
 SG_ VCRIGHT_a003_SWAssertion m0 : 6|1@1+ (1,0) [0|0] "" Vector__XXX
 SG_ VCRIGHT_a063_SwitchFault m1 : 6|1@1+ (1,0) [0|0] "" Vector__XXX
 SG_ VCRIGHT_a183_doorStateFactoryTes m3 : 6|1@1+ (1,0) [0|0] "" Vector__XXX
 SG_ VCRIGHT_a243_seatHeatShortRearL m4 : 6|1@1+ (1,0) [0|0] "" Vector__XXX
 SG_ VCRIGHT_a303_eFuseMgmtWindowLift m5 : 6|1@1+ (1,0) [0|0] "" Vector__XXX
 SG_ VCRIGHT_a363_hvacLowerModeWarnin m6 : 6|1@1+ (1,0) [0|0] "" Vector__XXX
 SG_ VCRIGHT_a483_rightTurnLightFault m8 : 6|1@1+ (1,0) [0|0] "" Vector__XXX
 SG_ VCRIGHT_a002_PowerLossReset m0 : 5|1@1+ (1,0) [0|0] "" Vector__XXX
 SG_ VCRIGHT_a062_XCPWasConnected m1 : 5|1@1+ (1,0) [0|0] "" Vector__XXX
 SG_ VCRIGHT_a122_ICR_MIA m2 : 5|1@1+ (1,0) [0|0] "" Vector__XXX
 SG_ VCRIGHT_a182_emergencyLatchRel m3 : 5|1@1+ (1,0) [0|0] "" Vector__XXX
 SG_ VCRIGHT_a242_seatHeatIRearL m4 : 5|1@1+ (1,0) [0|0] "" Vector__XXX
 SG_ VCRIGHT_a362_movingThresholdsInc m6 : 5|1@1+ (1,0) [0|0] "" Vector__XXX
 SG_ VCRIGHT_a482_NCV77XXFault m8 : 5|1@1+ (1,0) [0|0] "" Vector__XXX
 SG_ VCRIGHT_a542_steeringWheelHeatin m9 : 5|1@1+ (1,0) [0|0] "" Vector__XXX
 SG_ VCRIGHT_a001_WatchdogReset m0 : 4|1@1+ (1,0) [0|0] "" Vector__XXX
 SG_ VCRIGHT_a061_XCPConnected m1 : 4|1@1+ (1,0) [0|0] "" Vector__XXX
 SG_ VCRIGHT_a181_rearDoorLatchRehome m3 : 4|1@1+ (1,0) [0|0] "" Vector__XXX
 SG_ VCRIGHT_a241_seatHeatMIAFront m4 : 4|1@1+ (1,0) [0|0] "" Vector__XXX
 SG_ VCRIGHT_a361_stationaryThreshold m6 : 4|1@1+ (1,0) [0|0] "" Vector__XXX
 SG_ VCRIGHT_matrixIndex M : 0|4@1+ (1,0) [0|0] "" Vector__XXX

BO_ 1795 VCRIGHT_debugThermal10Hz: 8 VEH
 SG_ VCRIGHT_debugThermal10HzIndex M: 0|3@1+ (1,0) [0|0] "" X
 SG_ VCRIGHT_wattsDemandEvapFeedback m0: 3|9@1- (20,0) [0|0] "W" X
 SG_ VCRIGHT_wattsDemandEvapFeedfwd m0: 12|9@1+ (20,0) [0|0] "W" X
 SG_ VCRIGHT_wattsHeaterLeftFeedback m0: 21|9@1- (20,0) [0|0] "W" X
 SG_ VCRIGHT_wattsHeaterLeftFeedfwd m0: 30|9@1+ (20,0) [0|0] "W" X
 SG_ VCRIGHT_wattsHeaterRightFeedback m0: 39|9@1- (20,0) [0|0] "W" X
 SG_ VCRIGHT_wattsHeaterRightFeedfwd m0: 48|9@1+ (20,0) [0|0] "W" X
 SG_ VCRIGHT_tempEvapAdjustmentLeft m1: 8|7@1+ (0.1,0) [0|0] "degC" X
 SG_ VCRIGHT_tempEvapAdjustmentRight m1: 16|7@1+ (0.1,0) [0|0] "degC" X
 SG_ VCRIGHT_hvacPanelFloorSplitRow1 m2: 8|8@1+ (0.4,0) [0|0] "%" X
 SG_ VCRIGHT_hvacDefrostPercent m2: 16|8@1+ (0.4,0) [0|0] "%" X
 SG_ VCRIGHT_hvacRow2Percent m2: 24|8@1+ (0.4,0) [0|0] "%" X
 SG_ VCRIGHT_hvacPanelFloorSplitRow2 m2: 32|8@1+ (0.4,0) [0|0] "%" X
 SG_ VCRIGHT_cabinTempThs m3: 8|8@1+ (0.5,-40) [0|0] "degC" X
 SG_ VCRIGHT_cabinTempThsBracket m3: 16|8@1+ (0.5,-40) [0|0] "degC" X
 SG_ VCRIGHT_cabinTempProbe m3: 24|8@1+ (0.5,-40) [0|0] "degC" X
 SG_ VCRIGHT_setTempAdjustmentLeft m3: 32|7@1+ (0.1,0) [0|0] "degC" X
 SG_ VCRIGHT_setTempAdjustmentRight m3: 40|7@1+ (0.1,0) [0|0] "degC" X
 SG_ VCRIGHT_hvacLHBleedCalibrated m4: 3|1@1+ (1,0) [0|0] "" X
 SG_ VCRIGHT_hvacActuatorsCalibrated m4: 4|1@1+ (1,0) [0|0] "" X
 SG_ VCRIGHT_hvacRHBleedCalibrated m4: 7|1@1+ (1,0) [0|0] "" X
 SG_ VCRIGHT_hvacLHVaneCalibrated m4: 11|1@1+ (1,0) [0|0] "" X
 SG_ VCRIGHT_hvacRHVaneCalibrated m4: 15|1@1+ (1,0) [0|0] "" X
 SG_ VCRIGHT_hvacUpperModeCalibrated m4: 19|1@1+ (1,0) [0|0] "" X
 SG_ VCRIGHT_hvacLowerModeCalibrated m4: 23|1@1+ (1,0) [0|0] "" X
 SG_ VCRIGHT_hvacIntakeCalibrated m4: 27|1@1+ (1,0) [0|0] "" X

BA_DEF_ BO_ "GenMsgSendType" ENUM "Cyclic";
BA_DEF_ BO_ "GenMsgCycleTime" INT 0 10000;

BA_ "GenMsgSendType" BO_ 832 0;
BA_ "GenMsgCycleTime" BO_ 832 100;

BA_ "GenMsgSendType" BO_ 577 0;
BA_ "GenMsgCycleTime" BO_ 577 100;

BA_ "GenMsgSendType" BO_ 753 0;
BA_ "GenMsgCycleTime" BO_ 753 100;

BA_ "GenMsgSendType" BO_ 769 0;
BA_ "GenMsgCycleTime" BO_ 769 1000;

BA_ "GenMsgSendType" BO_ 1009 0;
BA_ "GenMsgCycleTime" BO_ 1009 100;

BA_ "GenMsgSendType" BO_ 705 0;
BA_ "GenMsgCycleTime" BO_ 705 17;

BA_ "GenMsgSendType" BO_ 897 0;
BA_ "GenMsgCycleTime" BO_ 897 250;

BA_ "GenMsgSendType" BO_ 721 0;
BA_ "GenMsgCycleTime" BO_ 721 100;

BA_ "GenMsgSendType" BO_ 801 0;
BA_ "GenMsgCycleTime" BO_ 801 1000;

BA_ "GenMsgSendType" BO_ 737 0;
BA_ "GenMsgCycleTime" BO_ 737 20;

BA_ "GenMsgSendType" BO_ 929 0;
BA_ "GenMsgCycleTime" BO_ 929 100;

BA_ "GenMsgSendType" BO_ 864 0;
BA_ "GenMsgCycleTime" BO_ 864 100;

BA_ "GenMsgSendType" BO_ 258 0;
BA_ "GenMsgCycleTime" BO_ 258 100;

BA_ "GenMsgSendType" BO_ 626 0;
BA_ "GenMsgCycleTime" BO_ 626 50;

BA_ "GenMsgSendType" BO_ 642 0;
BA_ "GenMsgCycleTime" BO_ 642 50;

BA_ "GenMsgSendType" BO_ 770 0;
BA_ "GenMsgCycleTime" BO_ 770 1000;

BA_ "GenMsgSendType" BO_ 1860 0;
BA_ "GenMsgCycleTime" BO_ 1860 1000;

BA_ "GenMsgSendType" BO_ 778 0;
BA_ "GenMsgCycleTime" BO_ 778 50;

BA_ "GenMsgSendType" BO_ 1250 0;
BA_ "GenMsgCycleTime" BO_ 1250 100;

BA_ "GenMsgSendType" BO_ 930 0;
BA_ "GenMsgCycleTime" BO_ 930 50;

BA_ "GenMsgSendType" BO_ 610 0;
BA_ "GenMsgCycleTime" BO_ 610 100;

BA_ "GenMsgSendType" BO_ 962 0;
BA_ "GenMsgCycleTime" BO_ 962 50;

BA_ "GenMsgSendType" BO_ 960 0;
BA_ "GenMsgCycleTime" BO_ 960 100;

BA_ "GenMsgSendType" BO_ 1795 0;
BA_ "GenMsgCycleTime" BO_ 1795 10;

VAL_ 577 VCFRONT_coolantAirPurgeBatState 0 "INACTIVE" 1 "ACTIVE" 2 "COMPLETE" 3 "INTERRUPTED" 4 "PENDING";
VAL_ 577 VCFRONT_coolantFlowBatReason 0 "NONE" 1 "COOLANT_AIR_PURGE" 2 "NO_FLOW_REQ" 3 "OVERRIDE_BATT" 4 "ACTIVE_MANAGER_BATT" 5 "PASSIVE_MANAGER_BATT" 6 "BMS_FLOW_REQ" 7 "DAS_FLOW_REQ" 8 "OVERRIDE_PT" 9 "ACTIVE_MANAGER_PT" 10 "PASSIVE_MANAGER_PT" 11 "PCS_FLOW_REQ" 12 "DI_FLOW_REQ" 13 "DIS_FLOW_REQ";
VAL_ 577 VCFRONT_coolantFlowPTReason 0 "NONE" 1 "COOLANT_AIR_PURGE" 2 "NO_FLOW_REQ" 3 "OVERRIDE_BATT" 4 "ACTIVE_MANAGER_BATT" 5 "PASSIVE_MANAGER_BATT" 6 "BMS_FLOW_REQ" 7 "DAS_FLOW_REQ" 8 "OVERRIDE_PT" 9 "ACTIVE_MANAGER_PT" 10 "PASSIVE_MANAGER_PT" 11 "PCS_FLOW_REQ" 12 "DI_FLOW_REQ" 13 "DIS_FLOW_REQ";
VAL_ 577 VCFRONT_wasteHeatRequestType 0 "NONE" 1 "PARTIAL" 2 "FULL";

VAL_ 1009 VCFRONT_DRLLeftStatus 0 "OFF" 1 "ON" 2 "FAULT" 3 "SNA";
VAL_ 1009 VCFRONT_DRLRightStatus 0 "OFF" 1 "ON" 2 "FAULT" 3 "SNA";
VAL_ 1009 VCFRONT_ambientLightingBrightnes 255 "SNA";
VAL_ 1009 VCFRONT_fogLeftStatus 0 "OFF" 1 "ON" 2 "FAULT" 3 "SNA";
VAL_ 1009 VCFRONT_fogRightStatus 0 "OFF" 1 "ON" 2 "FAULT" 3 "SNA";
VAL_ 1009 VCFRONT_hazardLightRequest 0 "NONE" 1 "BUTTON" 2 "LOCK" 3 "UNLOCK" 4 "MISLOCK" 5 "CRASH" 6 "CAR_ALARM" 7 "DAS";
VAL_ 1009 VCFRONT_highBeamLeftStatus 0 "OFF" 1 "ON" 2 "FAULT" 3 "SNA";
VAL_ 1009 VCFRONT_highBeamRightStatus 0 "OFF" 1 "ON" 2 "FAULT" 3 "SNA";
VAL_ 1009 VCFRONT_indicatorLeftRequest 0 "OFF" 1 "ACTIVE_LOW" 2 "ACTIVE_HIGH";
VAL_ 1009 VCFRONT_indicatorRightRequest 0 "OFF" 1 "ACTIVE_LOW" 2 "ACTIVE_HIGH";
VAL_ 1009 VCFRONT_lowBeamLeftStatus 0 "OFF" 1 "ON" 2 "FAULT" 3 "SNA";
VAL_ 1009 VCFRONT_lowBeamRightStatus 0 "OFF" 1 "ON" 2 "FAULT" 3 "SNA";
VAL_ 1009 VCFRONT_parkLeftStatus 0 "OFF" 1 "ON" 2 "FAULT" 3 "SNA";
VAL_ 1009 VCFRONT_parkRightStatus 0 "OFF" 1 "ON" 2 "FAULT" 3 "SNA";
VAL_ 1009 VCFRONT_sideMarkersStatus 0 "OFF" 1 "ON" 2 "FAULT" 3 "SNA";
VAL_ 1009 VCFRONT_sideRepeaterLeftStatus 0 "OFF" 1 "ON" 2 "FAULT" 3 "SNA";
VAL_ 1009 VCFRONT_sideRepeaterRightStatus 0 "OFF" 1 "ON" 2 "FAULT" 3 "SNA";
VAL_ 1009 VCFRONT_simLatchingStalk 0 "IDLE" 1 "LEFT" 2 "RIGHT" 3 "SNA";
VAL_ 1009 VCFRONT_switchLightingBrightness 255 "SNA";
VAL_ 1009 VCFRONT_turnSignalLeftStatus 0 "OFF" 1 "ON" 2 "FAULT" 3 "SNA";
VAL_ 1009 VCFRONT_turnSignalRightStatus 0 "OFF" 1 "ON" 2 "FAULT" 3 "SNA";

VAL_ 258 VCLEFT_frontLatchStatus 0 "SNA" 1 "OPENED" 2 "CLOSED" 3 "CLOSING" 4 "OPENING" 5 "AJAR" 6 "TIMEOUT" 7 "DEFAULT" 8 "FAULT";
VAL_ 258 VCLEFT_mirrorFoldState 0 "UNKNOWN" 1 "FOLDED" 2 "UNFOLDED" 3 "FOLDING" 4 "UNFOLDING";
VAL_ 258 VCLEFT_mirrorHeatState 0 "SNA" 1 "ON" 2 "OFF" 3 "OFF_UNAVAILABLE" 4 "FAULT";
VAL_ 258 VCLEFT_mirrorRecallState 0 "INIT" 1 "RECALLING_AXIS_1" 2 "RECALLING_AXIS_2" 3 "RECALLING_COMPLETE" 4 "RECALLING_FAILED" 5 "RECALLING_STOPPED";
VAL_ 258 VCLEFT_mirrorState 0 "IDLE" 1 "TILT_X" 2 "TILT_Y" 3 "FOLD_UNFOLD" 4 "RECALL";
VAL_ 258 VCLEFT_rearLatchStatus 0 "SNA" 1 "OPENED" 2 "CLOSED" 3 "CLOSING" 4 "OPENING" 5 "AJAR" 6 "TIMEOUT" 7 "DEFAULT" 8 "FAULT";

VAL_ 626 VCLEFT_epbmDebugIndex 0 "STATES" 1 "TRANSITIONS";
VAL_ 626 VCLEFT_epbmCaliperState 0 "UNSAVED" 1 "UNKNOWN" 2 "REAPPLY" 3 "PARK" 4 "OPEN" 5 "SERVICE";
VAL_ 626 VCLEFT_summonFaultReason 0 "NONE" 1 "DI_MIA" 2 "DAS_MIA" 3 "ESP_MIA" 4 "EPBM_MIA" 5 "DI_FAULT" 6 "DI_APC_FAULT" 7 "DAS_FAULT" 8 "ESP_FAULT" 9 "VEH_CAN_FAULT" 10 "EAC_NOT_ALLOWED" 11 "EPBM_REQUEST" 12 "SPEED" 13 "EXTERNAL" 14 "PARK_MIA" 15 "PM_MIA" 16 "PM_REQUEST" 17 "OOC" 18 "MISMATCH" 19 "EPB_FAULT" 20 "DI_STATE_INVALID" 21 "PASSIVE_REQUEST" 22 "EPBREMOTE_MIA" 23 "REMOTE_SUMMON_FAULTED" 24 "LOCAL_UNIT_FAULTED" 25 "REMOTE_UNIT_FAULTED" 26 "START_IN_UNAVAILABLE" 27 "INVALID_REMOTE_STATE" 28 "REMOTE_DID_NOT_START";
VAL_ 626 VCLEFT_epbSummonState 0 "INIT" 1 "IDLE" 2 "ARMED" 3 "ACTIVE" 4 "COMPLETE" 5 "FAULT" 6 "UNAVAILABLE";
VAL_ 626 VCLEFT_epbmSummonState 0 "INIT" 1 "IDLE" 2 "ARMED" 3 "ACTIVE" 4 "COMPLETE" 5 "FAULT" 6 "UNAVAILABLE";
VAL_ 626 VCLEFT_epbmUnitStatus 0 "UNKNOWN" 1 "OPEN" 2 "DYNAMIC" 3 "PARK" 4 "START" 5 "SERVICE" 6 "WINCHMODE" 7 "WINCHMODE_RELEASING" 8 "PARKING" 9 "DYNAMIC_APPLYING" 10 "RELEASING" 11 "SERVICE_RELEASING" 12 "PARK_PENDING" 13 "WINCHMODE_PENDING" 14 "SUMMON" 15 "SUMMON_RELEASING" 16 "SUMMON_PARKING" 17 "EXTERNAL_DYNAMIC" 18 "RELEASING_FOR_EXTERNAL_PARK" 19 "EXTERNAL_PARKING" 20 "DYNAMIC_PARKING" 21 "COUNT";
VAL_ 626 VCLEFT_epbUnitStatus 0 "UNKNOWN" 1 "OPEN" 2 "DYNAMIC" 3 "PARK" 4 "START" 5 "SERVICE" 6 "WINCHMODE" 7 "WINCHMODE_RELEASING" 8 "PARKING" 9 "DYNAMIC_APPLYING" 10 "RELEASING" 11 "SERVICE_RELEASING" 12 "PARK_PENDING" 13 "WINCHMODE_PENDING" 14 "SUMMON" 15 "SUMMON_RELEASING" 16 "SUMMON_PARKING" 17 "EXTERNAL_DYNAMIC" 18 "RELEASING_FOR_EXTERNAL_PARK" 19 "EXTERNAL_PARKING" 20 "DYNAMIC_PARKING" 21 "COUNT";
VAL_ 626 VCLEFT_epbmFaultStatus 0 "NOMINAL" 1 "RETRY" 2 "FAULT" 3 "FAULT_IDLE";
VAL_ 626 VCLEFT_epbFaultStatus 0 "NOMINAL" 1 "RETRY" 2 "FAULT" 3 "FAULT_IDLE";
VAL_ 626 VCLEFT_cdpEnumDummy 0 "IDLE" 1 "VALID" 2 "INVALID";

VAL_ 642 VCLEFT_blowerIndex 0 "FEEDBACK_SIGNALS" 1 "VARS";
VAL_ 642 VCLEFT_hvacBlowerOutputDuty 127 "SNA";
VAL_ 642 VCLEFT_hvacBlowerRPMTarget 1023 "SNA";
VAL_ 642 VCLEFT_hvacBlowerTorque -128 "SNA";
VAL_ 642 VCLEFT_hvacBlowerFETTemp 255 "SNA";
VAL_ 642 VCLEFT_hvacBlowerITerm 255 "SNA";
VAL_ 642 VCLEFT_hvacBlowerRs 255 "SNA";
VAL_ 642 VCLEFT_hvacBlowerIPhase0 255 "SNA";
VAL_ 642 VCLEFT_hvacBlowerIPhase1 255 "SNA";
VAL_ 642 VCLEFT_hvacBlowerIPhase2 255 "SNA";

VAL_ 1860 VCLEFT_columnRecallStatus 0 "SNA" 1 "IN_PROGRESS" 2 "COMPLETE" 3 "INTERRUPTED";
VAL_ 1860 VCLEFT_mirrorRecallStatus 0 "SNA" 1 "IN_PROGRESS" 2 "COMPLETE" 3 "INTERRUPTED";
VAL_ 1860 VCLEFT_seatRecallStatus 0 "SNA" 1 "IN_PROGRESS" 2 "COMPLETE" 3 "INTERRUPTED";
VAL_ 1860 VCLEFT_systemRecallStatus 0 "SNA" 1 "IN_PROGRESS" 2 "COMPLETE" 3 "INTERRUPTED";

VAL_ 778 VCLEFT_frontBuckleStatus 0 "UNLATCHED" 1 "LATCHED" 2 "FAULTED" 3 "SNA";
VAL_ 778 VCLEFT_frontOccupancyStatus 0 "UNOCCUPIED" 1 "OCCUPIED" 2 "OCCUPANCY_FAULTED" 3 "NOT_CONFIGURED" 7 "OCCUPANCY_SNA";
VAL_ 778 VCLEFT_rearCenterOccupancyStatus 0 "UNOCCUPIED" 1 "OCCUPIED" 2 "OCCUPANCY_FAULTED" 3 "OCCUPANCY_SNA";
VAL_ 778 VCLEFT_rearLeftBuckleStatus 0 "UNLATCHED" 1 "LATCHED" 2 "FAULTED" 3 "SNA";
VAL_ 778 VCLEFT_rearLeftOccupancyStatus 0 "UNOCCUPIED" 1 "OCCUPIED" 2 "OCCUPANCY_FAULTED" 3 "OCCUPANCY_SNA";
VAL_ 778 VCLEFT_rearRightOccupancyStatus 0 "UNOCCUPIED" 1 "OCCUPIED" 2 "OCCUPANCY_FAULTED" 3 "OCCUPANCY_SNA";

VAL_ 930 VCLEFT_statusIndex 0 "MUX0" 1 "MUX1";
VAL_ 930 VCLEFT_vehiclePowerStateDBG 0 "OFF" 1 "CONDITIONING" 2 "ACCESSORY" 3 "DRIVE";
VAL_ 930 VCLEFT_swcInputVoltage 255 "SNA";
VAL_ 930 VCLEFT_swcPCBATemperature -128 "SNA";
VAL_ 930 VCLEFT_tlcPCBATemperature -128 "SNA";

VAL_ 962 VCLEFT_switchStatusIndex 0 "0" 1 "1" 2 "INVALID";
VAL_ 962 VCLEFT_rightMirrorTilt 0 "STOP" 1 "DOWN" 2 "UP" 3 "RIGHT" 4 "LEFT";
VAL_ 962 VCLEFT_frontSeatTrackBack 0 "SNA" 1 "OFF" 2 "ON" 3 "FAULT";
VAL_ 962 VCLEFT_frontSeatTrackForward 0 "SNA" 1 "OFF" 2 "ON" 3 "FAULT";
VAL_ 962 VCLEFT_frontSeatTiltDown 0 "SNA" 1 "OFF" 2 "ON" 3 "FAULT";
VAL_ 962 VCLEFT_frontSeatTiltUp 0 "SNA" 1 "OFF" 2 "ON" 3 "FAULT";
VAL_ 962 VCLEFT_frontSeatLiftDown 0 "SNA" 1 "OFF" 2 "ON" 3 "FAULT";
VAL_ 962 VCLEFT_frontSeatLiftUp 0 "SNA" 1 "OFF" 2 "ON" 3 "FAULT";
VAL_ 962 VCLEFT_frontSeatBackrestBack 0 "SNA" 1 "OFF" 2 "ON" 3 "FAULT";
VAL_ 962 VCLEFT_frontSeatBackrestForward 0 "SNA" 1 "OFF" 2 "ON" 3 "FAULT";
VAL_ 962 VCLEFT_frontSeatLumbarDown 0 "SNA" 1 "OFF" 2 "ON" 3 "FAULT";
VAL_ 962 VCLEFT_frontSeatLumbarUp 0 "SNA" 1 "OFF" 2 "ON" 3 "FAULT";
VAL_ 962 VCLEFT_frontSeatLumbarIn 0 "SNA" 1 "OFF" 2 "ON" 3 "FAULT";
VAL_ 962 VCLEFT_frontSeatLumbarOut 0 "SNA" 1 "OFF" 2 "ON" 3 "FAULT";
VAL_ 962 VCLEFT_frontBuckleSwitch 0 "SNA" 1 "OFF" 2 "ON" 3 "FAULT";
VAL_ 962 VCLEFT_frontOccupancySwitch 0 "SNA" 1 "OFF" 2 "ON" 3 "FAULT";
VAL_ 962 VCLEFT_rearLeftBuckleSwitch 0 "SNA" 1 "OFF" 2 "ON" 3 "FAULT";
VAL_ 962 VCLEFT_rearCenterOccupancySwitch 0 "SNA" 1 "OFF" 2 "ON" 3 "FAULT";
VAL_ 962 VCLEFT_rearLeftOccupancySwitch 0 "SNA" 1 "OFF" 2 "ON" 3 "FAULT";
VAL_ 962 VCLEFT_rearRightOccupancySwitch 0 "SNA" 1 "OFF" 2 "ON" 3 "FAULT";
VAL_ 962 VCLEFT_swcLeftTiltRight 0 "SNA" 1 "OFF" 2 "ON" 3 "FAULT";
VAL_ 962 VCLEFT_swcLeftPressed 0 "SNA" 1 "OFF" 2 "ON" 3 "FAULT";
VAL_ 962 VCLEFT_swcRightTiltLeft 0 "SNA" 1 "OFF" 2 "ON" 3 "FAULT";
VAL_ 962 VCLEFT_swcRightTiltRight 0 "SNA" 1 "OFF" 2 "ON" 3 "FAULT";
VAL_ 962 VCLEFT_swcRightPressed 0 "SNA" 1 "OFF" 2 "ON" 3 "FAULT";
VAL_ 962 VCLEFT_swcLeftTiltLeft 0 "SNA" 1 "OFF" 2 "ON" 3 "FAULT";

VAL_ 1795 VCRIGHT_debugThermal10HzIndex 0 "heaterAndEvapWatts" 1 "temps" 2 "airflow" 3 "cabinModel" 4 "actuatorStatus" 5 "END";
VAL_ 1795 VCRIGHT_tempEvapAdjustmentLeft 255 "SNA";
VAL_ 1795 VCRIGHT_tempEvapAdjustmentRight 255 "SNA";
VAL_ 1795 VCRIGHT_cabinTempThs 255 "SNA";
VAL_ 1795 VCRIGHT_cabinTempThsBracket 255 "SNA";
VAL_ 1795 VCRIGHT_cabinTempProbe 255 "SNA";
VAL_ 1795 VCRIGHT_setTempAdjustmentLeft 255 "SNA";
VAL_ 1795 VCRIGHT_setTempAdjustmentRight 255 "SNA";
CM_ BO_ 610 "ESP32-DualCAN Model3_VEH. Seen on this car: 8-byte frames; fit good (bits covered 100%, mux 100%, ranges 100%).";
VAL_ 610 VCLEFT_steeringColumnLastRequest 0 "SNA" 1 "NONE" 2 "UP" 3 "DOWN" 4 "IN" 5 "OUT" ;
VAL_ 610 VCLEFT_steeringColumnSMState 0 "SNA" 1 "RECALL" 2 "CALIBRATE" 3 "MANUAL_CONTROL" ;
CM_ BO_ 705 "ESP32-DualCAN Model3_VEH. Seen on this car: 8-byte frames; fit good (bits covered 100%, mux 100%, ranges 100%).";
VAL_ 705 VCFRONT_logging10HzIndex 0 "COOLANT_PUMPS" 1 "THERMAL_FAN" 2 "COOLANT_VALVE" 3 "COMPRESSOR_REFRIGERANT" 4 "ACTIVE_LOUVER" 5 "HP_CONTROLLER" 6 "RADAR_HEATER" 7 "EXV_TORQUE_COUNT" 8 "END" ;
CM_ BO_ 721 "ESP32-DualCAN Model3_VEH. Seen on this car: 2-byte frames; fit poor (bits covered 0%, mux 100%, ranges 100%).";
CM_ BO_ 737 "ESP32-DualCAN Model3_VEH. Seen on this car: 8-byte frames; fit good (bits covered 100%, mux 100%, ranges 100%). read by the app or firmware.";
VAL_ 737 VCFRONT_frunkLatchType 0 "UNKNOWN" 1 "DOUBLE_ACTUATOR" 2 "DOUBLE_PULL" ;
VAL_ 737 VCFRONT_closeValvesRoutineStatus 0 "NOT_READY" 1 "MOVING_TO_FILL_POSITION" 2 "READY_TO_FILL" 3 "FAULTED" ;
VAL_ 737 VCFRONT_passengerBuckleStatus 0 "UNBUCKLED" 1 "BUCKLED" ;
VAL_ 737 VCFRONT_refrigFillRoutineStatus 0 "NOT_READY" 1 "MOVING_TO_FILL_POSITION" 2 "READY_TO_FILL" 3 "FAULTED" ;
VAL_ 737 VCFRONT_coolantFillRoutineStatus 0 "NOT_READY" 1 "MOVING_TO_FILL_POSITION" 2 "READY_TO_FILL" 3 "FAULTED" ;
VAL_ 737 VCFRONT_radarHeaterState 0 "SNA" 1 "ON" 2 "OFF" 3 "OFF_UNAVAILABLE" 4 "FAULT" ;
VAL_ 737 VCFRONT_hvacPerfTestCommand 0 "NOT_STARTED" 1 "INIT" 2 "BLOW" 3 "BLOW_BILEVEL" 4 "STOP" ;
VAL_ 737 VCFRONT_closureEasterEggState 0 "IDLE" 1 "ISOTP_RX" 2 "WAITING_FOR_ACTIVE_LOCK" 3 "SHOW_SETUP" 4 "WAITING_FOR_SYNC_PULSE" 5 "PLAY" 6 "SHOW_CLEANUP" ;
VAL_ 737 VCFRONT_pressureRefrigDischarge 511 "SNA" ;
VAL_ 737 VCFRONT_hibernationState 0 "INIT" 1 "NOT_ACTIVE" 2 "ACTIVE" 3 "RECOVERY" 4 "EXIT" 5 "PREP" ;
VAL_ 737 VCFRONT_pressureRefrigSuction 127 "SNA" ;
VAL_ 737 VCFRONT_AS8510Voltage 4095 "SNA" ;
VAL_ 737 VCFRONT_sleepCurrent 4095 "SNA" ;
VAL_ 737 VCFRONT_crashState 0 "IDLE" 1 "MINOR_1" 2 "MINOR_2" 3 "SEVERE" ;
VAL_ 737 VCFRONT_crashDetectedType 0 "NONE" 1 "MINOR_1" 2 "MINOR_2" 3 "SEVERE" ;
VAL_ 737 VCFRONT_vbatMonitorVoltage 4095 "SNA" ;
VAL_ 737 VCFRONT_wiperState 0 "SNA" 1 "SERVICE" 2 "FAULT" 3 "DELAYED_REST" 4 "PARK" 5 "WASH" 6 "MOMENTARY_WIPE" 7 "INTERMITTENT_HIGH" 8 "INTERMITTENT_LOW" 9 "CONT_FAST" 10 "CONT_SLOW" 11 "INT_AUTO_LOW" 12 "INT_AUTO_HIGH" ;
VAL_ 737 VCFRONT_wiperPosition 0 "SNA" 1 "SERVICE" 2 "DEPRESSED_PARK" 3 "DELAYED_REST" 4 "WIPING" ;
VAL_ 737 VCFRONT_vehicleStatusDBG 0 "INIT" 1 "LOW_POWER_AWAKE" 2 "CONDITIONING" 3 "ACCESSORY" 4 "ACCESSORY_PLUS" 5 "DRIVE" 6 "OTA" 7 "WAIT_FOR_HIGH_POWER" 8 "TURN_ON_LV" 9 "SYSTEM_CHECKS" 10 "LV_ON" 11 "JUMP_START" 12 "LV_SHUTDOWN" 13 "GO_QUIET" 14 "SLEEP_SHUTDOWN" 15 "LOW_POWER_STANDBY" 16 "RESET" ;
VAL_ 737 VCFRONT_wiperSpeed 0 "SNA" 1 "OFF" 2 "1" 3 "2" 4 "3" 5 "4" 6 "5" 7 "LOW" 8 "HIGH" ;
VAL_ 737 VCFRONT_iBoosterStateDBG 0 "OFF" 1 "ON" 2 "GOING_DOWN" 3 "WRITING_DATA_SHUTDOWN" 4 "FORCE_OFF" ;
VAL_ 737 VCFRONT_frunkLatchStatus 0 "SNA" 1 "OPENED" 2 "CLOSED" 3 "CLOSING" 4 "OPENING" 5 "AJAR" 6 "TIMEOUT" 7 "DEFAULT" 8 "FAULT" ;
VAL_ 737 VCFRONT_statusIndex 0 "BODY_CONTROLS" 1 "VEHICLE_STATE" 2 "HOMELINK" 3 "REFRIGERANT_SYSTEM" 4 "SYSTEM_HEALTH" 5 "INVALID" ;
CM_ BO_ 753 "ESP32-DualCAN Model3_VEH. Seen on this car: 8-byte frames; fit good (bits covered 100%, mux 100%, ranges 100%).";
VAL_ 753 VCFRONT_EPAS3PSelfTestResult 0 "NOT_RUN" 1 "RUNNING" 2 "PASSED" 3 "FAILED_RAILS_UNSTABLE" 4 "FAILED_EFUSE_OUTPUT_SHORT" 5 "FAILED_POWER_FET_STUCK_ON" 6 "FAILED_ENABLE_LOW_MALFUNCTION" 7 "FAILED_POWER_FET_CHANNEL_OPEN" 8 "FAILED_ENABLE_HIGH_MALFUNCTION" 9 "FAILED_TURN_OFF_PATH_TOO_SLOW" 10 "FAILED_NOT_LATCHED" 11 "SKIPPED" ;
VAL_ 753 VCFRONT_EPAS3SSelfTestResult 0 "NOT_RUN" 1 "RUNNING" 2 "PASSED" 3 "FAILED_RAILS_UNSTABLE" 4 "FAILED_EFUSE_OUTPUT_SHORT" 5 "FAILED_POWER_FET_STUCK_ON" 6 "FAILED_ENABLE_LOW_MALFUNCTION" 7 "FAILED_POWER_FET_CHANNEL_OPEN" 8 "FAILED_ENABLE_HIGH_MALFUNCTION" 9 "FAILED_TURN_OFF_PATH_TOO_SLOW" 10 "FAILED_NOT_LATCHED" 11 "SKIPPED" ;
VAL_ 753 VCFRONT_ESPMotorSelfTestResult 0 "NOT_RUN" 1 "RUNNING" 2 "PASSED" 3 "FAILED_RAILS_UNSTABLE" 4 "FAILED_EFUSE_OUTPUT_SHORT" 5 "FAILED_POWER_FET_STUCK_ON" 6 "FAILED_ENABLE_LOW_MALFUNCTION" 7 "FAILED_POWER_FET_CHANNEL_OPEN" 8 "FAILED_ENABLE_HIGH_MALFUNCTION" 9 "FAILED_TURN_OFF_PATH_TOO_SLOW" 10 "FAILED_NOT_LATCHED" 11 "SKIPPED" ;
VAL_ 753 VCFRONT_iBoosterSelfTestResult 0 "NOT_RUN" 1 "RUNNING" 2 "PASSED" 3 "FAILED_RAILS_UNSTABLE" 4 "FAILED_EFUSE_OUTPUT_SHORT" 5 "FAILED_POWER_FET_STUCK_ON" 6 "FAILED_ENABLE_LOW_MALFUNCTION" 7 "FAILED_POWER_FET_CHANNEL_OPEN" 8 "FAILED_ENABLE_HIGH_MALFUNCTION" 9 "FAILED_TURN_OFF_PATH_TOO_SLOW" 10 "FAILED_NOT_LATCHED" 11 "SKIPPED" ;
VAL_ 753 VCFRONT_pcsSelfTestResult 0 "NOT_RUN" 1 "RUNNING" 2 "PASSED" 3 "FAILED_RAILS_UNSTABLE" 4 "FAILED_EFUSE_OUTPUT_SHORT" 5 "FAILED_POWER_FET_STUCK_ON" 6 "FAILED_ENABLE_LOW_MALFUNCTION" 7 "FAILED_POWER_FET_CHANNEL_OPEN" 8 "FAILED_ENABLE_HIGH_MALFUNCTION" 9 "FAILED_TURN_OFF_PATH_TOO_SLOW" 10 "FAILED_NOT_LATCHED" 11 "SKIPPED" ;
VAL_ 753 VCFRONT_vcleftSelfTestResult 0 "NOT_RUN" 1 "RUNNING" 2 "PASSED" 3 "FAILED_RAILS_UNSTABLE" 4 "FAILED_EFUSE_OUTPUT_SHORT" 5 "FAILED_POWER_FET_STUCK_ON" 6 "FAILED_ENABLE_LOW_MALFUNCTION" 7 "FAILED_POWER_FET_CHANNEL_OPEN" 8 "FAILED_ENABLE_HIGH_MALFUNCTION" 9 "FAILED_TURN_OFF_PATH_TOO_SLOW" 10 "FAILED_NOT_LATCHED" 11 "SKIPPED" ;
VAL_ 753 VCFRONT_vcrightSelfTestResult 0 "NOT_RUN" 1 "RUNNING" 2 "PASSED" 3 "FAILED_RAILS_UNSTABLE" 4 "FAILED_EFUSE_OUTPUT_SHORT" 5 "FAILED_POWER_FET_STUCK_ON" 6 "FAILED_ENABLE_LOW_MALFUNCTION" 7 "FAILED_POWER_FET_CHANNEL_OPEN" 8 "FAILED_ENABLE_HIGH_MALFUNCTION" 9 "FAILED_TURN_OFF_PATH_TOO_SLOW" 10 "FAILED_NOT_LATCHED" 11 "SKIPPED" ;
VAL_ 753 VCFRONT_vbatFusedSelfTestResult 0 "NOT_RUN" 1 "RUNNING" 2 "PASSED" 3 "FAILED_RAILS_UNSTABLE" 4 "FAILED_EFUSE_OUTPUT_SHORT" 5 "FAILED_POWER_FET_STUCK_ON" 6 "FAILED_ENABLE_LOW_MALFUNCTION" 7 "FAILED_POWER_FET_CHANNEL_OPEN" 8 "FAILED_ENABLE_HIGH_MALFUNCTION" 9 "FAILED_TURN_OFF_PATH_TOO_SLOW" 10 "FAILED_NOT_LATCHED" 11 "SKIPPED" ;
VAL_ 753 VCFRONT_EPAS3PState 0 "OFF" 1 "ON" 2 "LOCKED_OUT" ;
VAL_ 753 VCFRONT_EPAS3SState 0 "OFF" 1 "ON" 2 "LOCKED_OUT" ;
VAL_ 753 VCFRONT_ESPMotorState 0 "OFF" 1 "ON" 2 "LOCKED_OUT" ;
VAL_ 753 VCFRONT_ESPValveState 0 "OFF" 1 "ON" 2 "LOCKED_OUT" ;
VAL_ 753 VCFRONT_PCSState 0 "OFF" 1 "ON" 2 "LOCKED_OUT" ;
VAL_ 753 VCFRONT_autopilot1State 0 "OFF" 1 "ON" 2 "LOCKED_OUT" ;
VAL_ 753 VCFRONT_autopilot2State 0 "OFF" 1 "ON" 2 "LOCKED_OUT" ;
VAL_ 753 VCFRONT_iBoosterState 0 "OFF" 1 "ON" 2 "LOCKED_OUT" ;
VAL_ 753 VCFRONT_leftControllerState 0 "OFF" 1 "ON" 2 "LOCKED_OUT" ;
VAL_ 753 VCFRONT_eFuseDebugStatusIndex 0 "VCRIGHT" 1 "PCS" 2 "IBOOSTER" 3 "EPAS3S" 4 "UNUSED_1" 5 "UNUSED_2" 6 "DRIVE_INVERTER" 7 "AUTOPILOT_2" 8 "MCU" 9 "HEADLAMP" 10 "VBAT_FUSED_HIGH_CURRENT" 11 "THERMALS_AND_MOTORS" 12 "RAILS_A_B" 13 "MISC_RAILS" 14 "STEERING_FEEDBACK" 15 "BRIDGE" 16 "INVALID" ;
CM_ BO_ 769 "ESP32-DualCAN Model3_VEH. Seen on this car: 8-byte frames; fit good (bits covered 100%, mux 100%, ranges 100%).";
VAL_ 769 VCFRONT_infoAssemblyId 1 "ASSEMBLY1" 255 "ASSEMBLY_SNA" ;
VAL_ 769 VCFRONT_infoBuildType 0 "UNKNOWN_BUILD" 1 "PLATFORM_BUILD" 2 "LOCAL_BUILD" 3 "TRACEABLE_CI_BUILD" 4 "MFG_BUILD" ;
VAL_ 769 VCFRONT_infoIndex 0 "DEPRECATED_0" 1 "DEPRECATED_1" 2 "DEPRECATED_2" 3 "DEPRECATED_3" 4 "DEPRECATED_4" 5 "DEPRECATED_5" 6 "DEPRECATED_6" 7 "DEPRECATED_7" 8 "DEPRECATED_8" 9 "DEPRECATED_9" 10 "BUILD_HWID_COMPONENTID" 11 "PCBAID_ASSYID_USAGEID" 13 "APP_CRC" 14 "BOOTLOADER_SVN" 15 "BOOTLOADER_CRC" 16 "SUBCOMPONENT1" 17 "APP_GITHASH" 18 "BOOTLOADER_GITHASH" 19 "VERSION_DEPRECATED" 20 "UDS_PROTOCOL_BOOTCRC" 23 "SUBCOMPONENT2" 24 "SUBCOMPONENT3" 31 "SUBCOMPONENT4" 32 "SUBCOMPONENT5" 33 "SUBCOMPONENT6" 34 "SUBCOMPONENT7" 35 "SUBCOMPONENT8" 36 "SUBCOMPONENT9" 37 "SUBCOMPONENT10" 38 "SUBCOMPONENT11" 39 "SUBCOMPONENT12" 40 "SUBCOMPONENT13" 41 "SUBCOMPONENT14" 255 "END" ;
CM_ BO_ 770 "ESP32-DualCAN Model3_VEH. Seen on this car: 8-byte frames; fit good (bits covered 100%, mux 71%, ranges 100%).";
VAL_ 770 VCLEFT_infoAssemblyId 1 "ASSEMBLY1" 255 "ASSEMBLY_SNA" ;
VAL_ 770 VCLEFT_infoBuildType 0 "UNKNOWN_BUILD" 1 "PLATFORM_BUILD" 2 "LOCAL_BUILD" 3 "TRACEABLE_CI_BUILD" 4 "MFG_BUILD" ;
VAL_ 770 VCLEFT_infoIndex 0 "DEPRECATED_0" 1 "DEPRECATED_1" 2 "DEPRECATED_2" 3 "DEPRECATED_3" 4 "DEPRECATED_4" 5 "DEPRECATED_5" 6 "DEPRECATED_6" 7 "DEPRECATED_7" 8 "DEPRECATED_8" 9 "DEPRECATED_9" 10 "BUILD_HWID_COMPONENTID" 11 "PCBAID_ASSYID_USAGEID" 13 "APP_CRC" 14 "BOOTLOADER_SVN" 15 "BOOTLOADER_CRC" 16 "SUBCOMPONENT1" 17 "APP_GITHASH" 18 "BOOTLOADER_GITHASH" 19 "VERSION_DEPRECATED" 20 "UDS_PROTOCOL_BOOTCRC" 23 "SUBCOMPONENT2" 24 "SUBCOMPONENT3" 31 "SUBCOMPONENT4" 32 "SUBCOMPONENT5" 33 "SUBCOMPONENT6" 34 "SUBCOMPONENT7" 35 "SUBCOMPONENT8" 36 "SUBCOMPONENT9" 37 "SUBCOMPONENT10" 38 "SUBCOMPONENT11" 39 "SUBCOMPONENT12" 40 "SUBCOMPONENT13" 41 "SUBCOMPONENT14" 255 "END" ;
CM_ BO_ 801 "ESP32-DualCAN Model3_VEH. Seen on this car: 8-byte frames; fit good (bits covered 100%, mux 100%, ranges 100%, checksum 100%).";
VAL_ 801 VCFRONT_tempAmbientFiltered 0 "SNA" ;
VAL_ 801 VCFRONT_washerFluidLevel 0 "SNA" 1 "LOW" 2 "NORMAL" ;
VAL_ 801 VCFRONT_tempAmbient 0 "SNA" ;
VAL_ 801 VCFRONT_brakeFluidLevel 0 "SNA" 1 "LOW" 2 "NORMAL" ;
VAL_ 801 VCFRONT_coolantLevel 0 "NOT_OK" 1 "FILLED" ;
VAL_ 801 VCFRONT_tempCoolantPTInlet 2047 "SNA" ;
VAL_ 801 VCFRONT_tempCoolantBatInlet 1023 "SNA" ;
CM_ BO_ 832 "ESP32-DualCAN Model3_VEH. Seen on this car: 8-byte frames; fit good (bits covered 100%, mux 100%, ranges 100%).";
VAL_ 832 VCFRONT_matrixIndex 0 "AlertMatrix0" 1 "AlertMatrix1" 2 "AlertMatrix2" 3 "AlertMatrix3" 4 "AlertMatrix4" 5 "AlertMatrix5" 6 "AlertMatrix6" 7 "AlertMatrix7" 8 "AlertMatrix8" 9 "AlertMatrix9" ;
CM_ BO_ 864 "ESP32-DualCAN Model3_VEH. Seen on this car: 8-byte frames; fit good (bits covered 100%, mux 100%, ranges 100%).";
VAL_ 864 VCLEFT_matrixIndex 0 "AlertMatrix0" 1 "AlertMatrix1" 2 "AlertMatrix2" 3 "AlertMatrix3" 4 "AlertMatrix4" 5 "AlertMatrix5" 6 "AlertMatrix6" 7 "AlertMatrix7" 8 "AlertMatrix8" 9 "AlertMatrix9" ;
CM_ BO_ 897 "ESP32-DualCAN Model3_VEH. Seen on this car: 8-byte frames; fit good (bits covered 100%, mux 100%, ranges 100%).";
VAL_ 897 VCFRONT_hpRefrigerantPurgeState 0 "IDLE" 1 "EVAP_PURGE" 2 "COMPLETE" ;
VAL_ 897 VCFRONT_radiatorFanRunReason 0 "NONE" 1 "ACTIVE_MANAGER" 2 "AMBIENT_SNIFF" 3 "NVH_MASKING" 4 "HEAT_PUMP" 5 "COAST_MODE" 6 "MIN_ON_GLOBAL" 7 "MIN_ON_NVH" 8 "UDS" 9 "RAD_CLEAR" 10 "DI_BURN_IN" ;
VAL_ 897 VCFRONT_passiveCoolingState 0 "ChillerCoolsSeriesLoop" 1 "ChillerCoolsParallelBattLoop" 2 "ChillerAndRadCoolSeriesLoop" 3 "CannotCoolBattery" ;
VAL_ 897 VCFRONT_coolantValveRadBypass 127 "SNA" ;
VAL_ 897 VCFRONT_radiatorFanFETTemp 255 "SNA" ;
VAL_ 897 VCFRONT_radBypassMoveReason 0 "INIT_UNBYPASS" 1 "INIT_BYPASS" 2 "PASSIVE_UNBYPASS" 3 "PASSIVE_BYPASS" 4 "RAD_HEAT_BYPASS" 5 "RAD_HEAT_UNBYPASS" 6 "ACTIVE_PT_UNBYPASS" 7 "ACTIVE_BATT_UNBYPASS" 8 "EXIT_SERIES" 9 "UDS" ;
VAL_ 897 VCFRONT_tempRefrigLiquid 2047 "SNA" ;
VAL_ 897 VCFRONT_pumpPowertrainFETTemp 255 "SNA" ;
VAL_ 897 VCFRONT_tempSuperheatActual 1023 "SNA" ;
VAL_ 897 VCFRONT_pumpBatteryFETTemp 255 "SNA" ;
VAL_ 897 VCFRONT_pumpPowertrainRPMTarget 1023 "SNA" ;
VAL_ 897 VCFRONT_tempRefrigSuction 255 "SNA" ;
VAL_ 897 VCFRONT_pumpBatteryRPMTarget 1023 "SNA" ;
VAL_ 897 VCFRONT_tempRefrigDischarge 2047 "SNA" ;
VAL_ 897 VCFRONT_modeDesired 0 "SERIES" 1 "PARALLEL" 2 "BLEND" 3 "AMBIENT_SOURCE" ;
VAL_ 897 VCFRONT_coolantValveCountRange 1023 "SNA" ;
VAL_ 897 VCFRONT_coolantValveRecalReason 0 "UNDEFINED" 1 "MAX_TRAVEL" 2 "GENERAL_FAULT" 3 "CALIBRATION_FAULT_NO_TRAVEL" 4 "SELF_TEST" 5 "MOTOR_FEEDBACK_INTERRUPTED" 6 "NVRAM_LOSS" 7 "SYSTEM_LEVEL_FAULT_RESPONSE" ;
VAL_ 897 VCFRONT_louverPosReason 0 "NONE" 1 "CONDENSOR_MANAGER" 2 "PASSIVE_MANAGER" 3 "SNIFFING" 4 "BOUNDS_CHECK" 5 "FAN_RUN" 6 "FAN_FAULT" 7 "COAST_MODE" 8 "UDS" ;
VAL_ 897 VCFRONT_modeTransitionID 0 "PARALLEL_F1_noFlowRequest" 1 "SERIES_F2_faultPumps" 2 "SERIES_F3_faultTempSensors" 3 "SER_2_drive_battBelowHotStagnationTemp" 4 "SER_3_drive_chillerPassivelyCools" 5 "SER_4_drive_radPassivelyCoolsBatt" 6 "SER_5_drive_battBelowPassiveOrNeedsHeat" 7 "SER_6_FC_battHeatingNeeded" 8 "PAR_2_drive_battNeedsActiveCooling" 9 "PAR_3_drive_ptNeedsActiveCooling" 10 "PAR_4_drive_chillerPassivelyCoolsBatt" 11 "PAR_5_drive_cannotPassivelyCoolBatt" 12 "PAR_6_drive_battAboveHotStagnationTemp" 13 "PAR_7_FC_battNeedsActiveCooling" 14 "PAR_8_FC_ptNeedsActiveCooling" 15 "PAR_9_FC_battAboveHotStagnationTemp" 16 "INIT" 17 "OVERRIDE" 18 "UNDEFINED" 19 "ENTER_AMBIENTSOURCE" 20 "EXIT_AMBIENTSOURCE" 21 "PAR_1_dragStripMode" 22 "SER_1_dragStripMode" 23 "SER_7_charge_battBelowPassiveTarget" 24 "PAR_10_charge_battAbovePassiveTarget" 25 "SER_8_service_highCoolantFlowReq" ;
VAL_ 897 VCFRONT_logging1HzIndex 0 "COOLANT" 1 "FAN_DEMAND_CONDENSER_AND_FET_TEMPS" 2 "COOLANT_VALVE" 3 "HEADLAMP_TEMPS" 4 "HEADLAMP_AIM" 5 "HP_EXV_RANGE" 6 "HP_DATA_AND_ACCUMULATORS" 7 "HP_CONTROL_LOOP_AND_STATE" 8 "HP_CYCLE_MODEL" 9 "HP_EXV_CALIBRATION" 10 "HP_DISSIPATION_AND_POWER" 11 "HP_TEMPS_AND_DEMANDS" 12 "HP_PRESSURE_CONTROL" 13 "HP_ARBITRATION" 14 "HP_MODE_SELECT_AND_ESTIMATES" 15 "HP_MODE_OPTIONS_AND_ESTIMATES" 16 "BODY_CONTROL" 17 "COOLANT_2" 18 "HP_PT_TARGETS" 19 "MISC_ACTUATORS" 20 "MISC" 21 "PART_FAILURE_CONFIDENCE" 22 "PART_FAILURE_CONFIDENCE_CONTINUED" 23 "MISC_TWO" 24 "END" ;
CM_ BO_ 929 "ESP32-DualCAN Model3_VEH. Seen on this car: 8-byte frames; fit good (bits covered 100%, mux 100%, ranges 100%, checksum 100%).";
VAL_ 929 VCFRONT_pcsEFuseVoltage 1023 "SNA" ;
VAL_ 929 VCFRONT_2RowRightUnbuckled 0 "NONE" 1 "OCCUPIED_AND_UNBUCKLED" 2 "SNA" ;
VAL_ 929 VCFRONT_2RowCenterUnbuckled 0 "NONE" 1 "OCCUPIED_AND_UNBUCKLED" 2 "SNA" ;
VAL_ 929 VCFRONT_2RowLeftUnbuckled 0 "NONE" 1 "OCCUPIED_AND_UNBUCKLED" 2 "SNA" ;
VAL_ 929 VCFRONT_passengerUnbuckled 0 "NONE" 1 "OCCUPIED_AND_UNBUCKLED" 2 "SNA" ;
VAL_ 929 VCFRONT_driverUnbuckled 0 "NONE" 1 "OCCUPIED_AND_UNBUCKLED" 2 "SNA" ;
VAL_ 929 VCFRONT_driverDoorStatus 0 "OPEN" 1 "CLOSED" ;
VAL_ 929 VCFRONT_driverBuckleStatus 0 "UNBUCKLED" 1 "BUCKLED" ;
VAL_ 929 VCFRONT_12vStatusForDrive 0 "NOT_READY_FOR_DRIVE_12V" 1 "READY_FOR_DRIVE_12V" 2 "EXIT_DRIVE_REQUESTED_12V" ;
VAL_ 929 VCFRONT_diPowerOnState 0 "POWERED_OFF" 1 "POWERED_ON_FOR_SUMMON" 2 "POWERED_ON_FOR_STATIONARY_HEAT" 3 "POWERED_ON_FOR_DRIVE" 4 "POWER_GOING_DOWN" 5 "POWERED_ON_FOR_WINCH" ;
VAL_ 929 VCFRONT_thermalSystemType 0 "LEGACY_THERMAL_SYSTEM" 1 "HEAT_PUMP_THERMAL_SYSTEM" ;
VAL_ 929 VCFRONT_3RowRightUnbuckled 0 "NONE" 1 "OCCUPIED_AND_UNBUCKLED" 2 "SNA" ;
VAL_ 929 VCFRONT_3RowLeftUnbuckled 0 "NONE" 1 "OCCUPIED_AND_UNBUCKLED" 2 "SNA" ;
VAL_ 929 VCFRONT_APGlassHeaterState 0 "SNA" 1 "ON" 2 "OFF" 3 "OFF_UNAVAILABLE" 4 "FAULT" ;
VAL_ 929 VCFRONT_vehicleStatusMuxIndex 0 "MUX0" 1 "MUX1" ;
CM_ BO_ 960 "ESP32-DualCAN Model3_VEH. Seen on this car: 8-byte frames; fit good (bits covered 100%, mux 100%, ranges 100%).";
VAL_ 960 VCRIGHT_matrixIndex 0 "AlertMatrix0" 1 "AlertMatrix1" 2 "AlertMatrix2" 3 "AlertMatrix3" 4 "AlertMatrix4" 5 "AlertMatrix5" 6 "AlertMatrix6" 7 "AlertMatrix7" 8 "AlertMatrix8" 9 "AlertMatrix9" ;
CM_ BO_ 1250 "ESP32-DualCAN Model3_VEH. Seen on this car: 8-byte frames; fit good (bits covered 100%, mux 100%, ranges 100%).";
VAL_ 1250 VCLEFT_frontSeatBackState 0 "STOPPED" 1 "MOVING_UP" 2 "MOVING_DOWN" 3 "RECALLING" 4 "CALIBRATING" 5 "UNDEFINED" ;
VAL_ 1250 VCLEFT_frontSeatLiftState 0 "STOPPED" 1 "MOVING_UP" 2 "MOVING_DOWN" 3 "RECALLING" 4 "CALIBRATING" 5 "UNDEFINED" ;
VAL_ 1250 VCLEFT_frontSeatTiltState 0 "STOPPED" 1 "MOVING_UP" 2 "MOVING_DOWN" 3 "RECALLING" 4 "CALIBRATING" 5 "UNDEFINED" ;
VAL_ 1250 VCLEFT_frontSeatTrackState 0 "STOPPED" 1 "MOVING_UP" 2 "MOVING_DOWN" 3 "RECALLING" 4 "CALIBRATING" 5 "UNDEFINED" ;
VAL_ 1250 VCLEFT_lumbarBState 0 "STOPPED" 1 "MOVING_UP" 2 "MOVING_DOWN" 3 "RECALLING" 4 "CALIBRATING" 5 "UNDEFINED" ;
VAL_ 1250 VCLEFT_lumbarAState 0 "STOPPED" 1 "MOVING_UP" 2 "MOVING_DOWN" 3 "RECALLING" 4 "CALIBRATING" 5 "UNDEFINED" ;
VAL_ 1250 VCLEFT_seatStatusIndex 0 "TRACK" 1 "BACK" 2 "LIFT" 3 "TILT" 4 "LUMBAR" 5 "POSITION" ;
